VERSION ""

NS_ :

BS_:

BU_: APIM_CISM FCIMB RACM_RCIM DSP WCM DACMC HUD_ADV TRM_ITRM ACM GWM _delete APIM IPC GENERIC TSTR

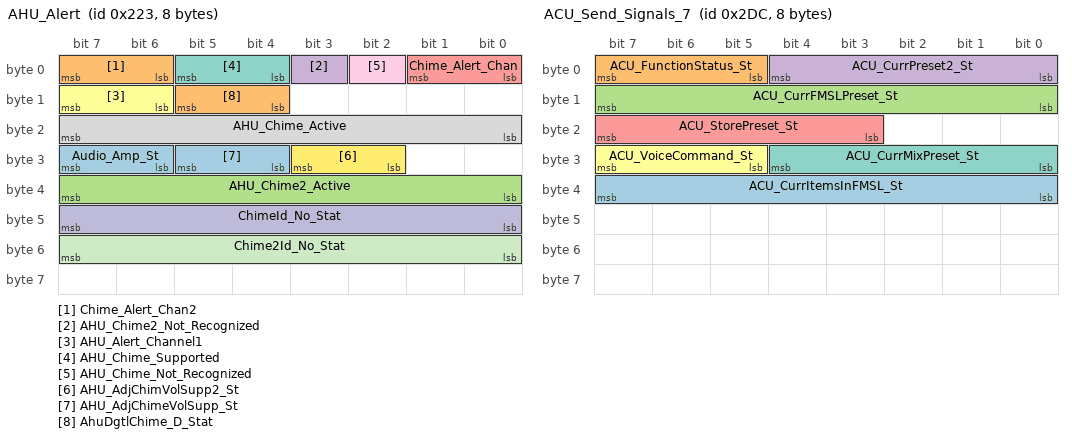
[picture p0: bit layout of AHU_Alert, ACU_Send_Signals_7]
BO_ 547 AHU_Alert: 8 ACM
 SG_ Audio_Amp_St : 31|2@0+ (1,0) [0|3] "SED"  GENERIC
 SG_ Chime_Alert_Chan2 : 7|2@0+ (1,0) [0|3] "SED"  DSP,IPC
 SG_ AHU_Chime2_Active : 39|8@0+ (1,0) [0|255] "SED"  DSP,IPC
 SG_ AHU_Chime2_Not_Recognized : 3|1@0+ (1,0) [0|1] "SED"  IPC
 SG_ Chime_Alert_Chan : 1|2@0+ (1,0) [0|3] "SED"  DSP,IPC
 SG_ AHU_Alert_Channel1 : 15|2@0+ (1,0) [0|3] "SED"  RACM_RCIM,IPC,APIM
 SG_ AHU_Chime_Supported : 5|2@0+ (1,0) [0|3] "SED"  APIM,IPC
 SG_ AHU_Chime_Active : 23|8@0+ (1,0) [0|255] "SED"  DSP,IPC
 SG_ AHU_Chime_Not_Recognized : 2|1@0+ (1,0) [0|1] "SED"  IPC
 SG_ ChimeId_No_Stat : 47|8@0+ (1,0) [0|255] "SED"  IPC
 SG_ Chime2Id_No_Stat : 55|8@0+ (1,0) [0|255] "SED"  IPC
 SG_ AHU_AdjChimVolSupp2_St : 27|2@0+ (1,0) [0|4] "SED"  IPC
 SG_ AHU_AdjChimeVolSupp_St : 29|2@0+ (1,0) [0|4] "SED"  IPC
 SG_ AhuDgtlChime_D_Stat : 13|2@0+ (1,0) [0|3] "SED"  DSP

BO_ 732 ACU_Send_Signals_7: 8 ACM
 SG_ ACU_CurrItemsInFMSL_St : 39|8@0+ (1,0) [0|255] "unitless"  APIM
 SG_ ACU_FunctionStatus_St : 7|3@0+ (1,0) [0|7] "SED"  RACM_RCIM,APIM,IPC
 SG_ ACU_CurrFMSLPreset_St : 15|8@0+ (1,0) [0|255] "unitless"  APIM
 SG_ ACU_CurrPreset2_St : 4|5@0+ (1,0) [0|31] "unitless"  HUD_ADV,RACM_RCIM,APIM,IPC
 SG_ ACU_StorePreset_St : 23|5@0+ (1,0) [0|31] "SED"  APIM,IPC
 SG_ ACU_VoiceCommand_St : 31|3@0+ (1,0) [0|7] "SED" Vector__XXX
 SG_ ACU_CurrMixPreset_St : 28|5@0+ (1,0) [0|31] "unitless"  IPC,RACM_RCIM,APIM

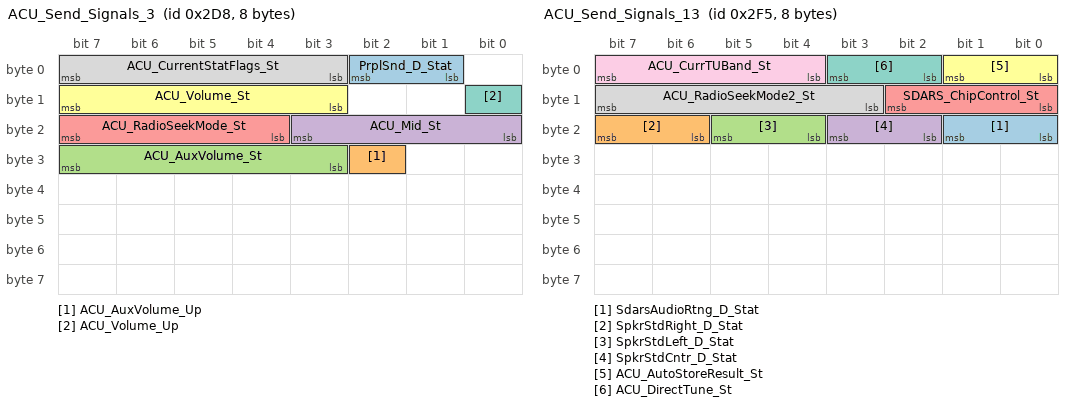
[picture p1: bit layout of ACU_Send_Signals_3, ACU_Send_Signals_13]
BO_ 728 ACU_Send_Signals_3: 8 ACM
 SG_ PrplSnd_D_Stat : 2|2@0+ (1,0) [0|3] "SED"  APIM_CISM,APIM
 SG_ ACU_AuxVolume_Up : 26|1@0+ (1,0) [0|1] "SED"  IPC
 SG_ ACU_AuxVolume_St : 31|5@0+ (1,0) [0|31] "unitless"  IPC
 SG_ ACU_Mid_St : 19|4@0+ (1,-7) [-7|8] "unitless"  APIM
 SG_ ACU_RadioSeekMode_St : 23|4@0+ (1,0) [0|15] "SED"  APIM,IPC
 SG_ ACU_Volume_St : 15|5@0+ (1,0) [0|30] "unitless"  HUD_ADV,GWM,RACM_RCIM,WCM,APIM,IPC
 SG_ ACU_Volume_Up : 8|1@0+ (1,0) [0|1] "SED"  HUD_ADV,RACM_RCIM,APIM,IPC
 SG_ ACU_CurrentStatFlags_St : 7|5@0+ (1,0) [0|31] "unitless"  RACM_RCIM,APIM,IPC

BO_ 489 ACU_Send_Signals_1: 8 ACM
 SG_ ACU_CurrentPSName_St : 7|64@0+ (1,0) [0|1.8446744074E+019] "unitless"  HUD_ADV,RACM_RCIM,APIM,IPC

BO_ 757 ACU_Send_Signals_13: 8 ACM
 SG_ SdarsAudioRtng_D_Stat : 17|2@0+ (1,0) [0|3] "SED"  APIM_CISM,APIM,GWM
 SG_ SpkrStdRight_D_Stat : 23|2@0+ (1,0) [0|3] "SED"  DSP,GWM
 SG_ SpkrStdLeft_D_Stat : 21|2@0+ (1,0) [0|3] "SED"  DSP,GWM
 SG_ SpkrStdCntr_D_Stat : 19|2@0+ (1,0) [0|3] "SED"  DSP,GWM
 SG_ SDARS_ChipControl_St : 10|3@0+ (1,0) [0|7] "SED"  APIM_CISM,GWM,APIM
 SG_ ACU_AutoStoreResult_St : 1|2@0+ (1,0) [0|3] "SED"  RACM_RCIM,GWM,APIM,IPC
 SG_ ACU_DirectTune_St : 3|2@0+ (1,0) [0|3] "SED"  GWM,APIM,IPC
 SG_ ACU_RadioSeekMode2_St : 15|5@0+ (1,0) [0|31] "SED"  HUD_ADV,RACM_RCIM,GWM,APIM,WCM,IPC
 SG_ ACU_CurrTUBand_St : 7|4@0+ (1,0) [0|15] "SED"  HUD_ADV,DSP,RACM_RCIM,GWM,APIM,WCM,IPC

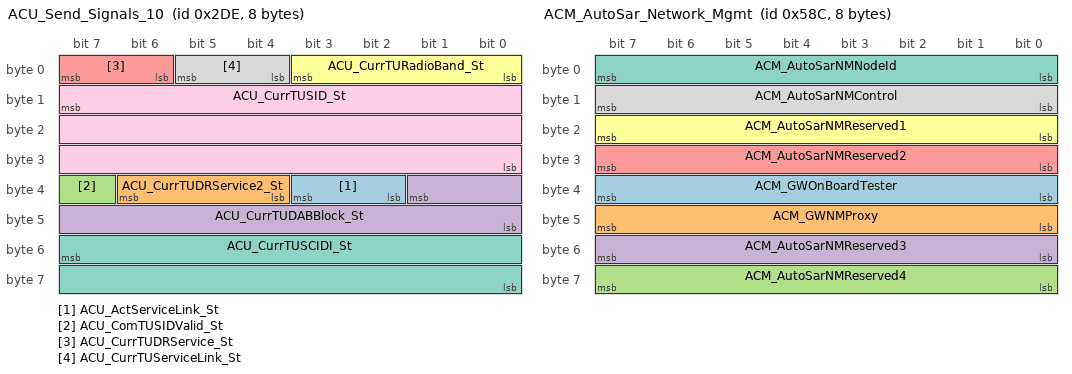
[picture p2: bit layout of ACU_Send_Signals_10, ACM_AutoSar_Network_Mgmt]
BO_ 734 ACU_Send_Signals_10: 8 ACM
 SG_ ACU_ActServiceLink_St : 35|2@0+ (1,0) [0|3] "SED"  IPC,RACM_RCIM,APIM
 SG_ ACU_CurrTUDRService2_St : 38|3@0+ (1,0) [0|7] "SED"  HUD_ADV,RACM_RCIM,APIM,IPC
 SG_ ACU_ComTUSIDValid_St : 39|1@0+ (1,0) [0|1] "SED"  APIM
 SG_ ACU_CurrTUDABBlock_St : 33|10@0+ (1,0) [0|1023] "SED"  HUD_ADV,RACM_RCIM,APIM,IPC
 SG_ ACU_CurrTUDRService_St : 7|2@0+ (1,0) [0|3] "SED"  APIM
 SG_ ACU_CurrTURadioBand_St : 3|4@0+ (1,0) [0|15] "SED" Vector__XXX
 SG_ ACU_CurrTUSCIDI_St : 55|16@0+ (1,0) [0|65535] "unitless"  RACM_RCIM,APIM
 SG_ ACU_CurrTUServiceLink_St : 5|2@0+ (1,0) [0|3] "SED"  RACM_RCIM,APIM
 SG_ ACU_CurrTUSID_St : 15|24@0+ (1,0) [0|16777215] "unitless"  RACM_RCIM,APIM

BO_ 1420 ACM_AutoSar_Network_Mgmt: 8 ACM
 SG_ ACM_GWOnBoardTester : 39|8@0+ (1,0) [0|255] "unitless"  HUD_ADV,GWM
 SG_ ACM_GWNMProxy : 47|8@0+ (1,0) [0|255] "unitless"  HUD_ADV,GWM
 SG_ ACM_AutoSarNMReserved4 : 63|8@0+ (1,0) [0|255] "unitless"  HUD_ADV,GWM
 SG_ ACM_AutoSarNMReserved3 : 55|8@0+ (1,0) [0|255] "unitless"  HUD_ADV,GWM
 SG_ ACM_AutoSarNMReserved2 : 31|8@0+ (1,0) [0|255] "unitless"  HUD_ADV,GWM
 SG_ ACM_AutoSarNMReserved1 : 23|8@0+ (1,0) [0|255] "unitless"  HUD_ADV,GWM
 SG_ ACM_AutoSarNMNodeId : 7|8@0+ (1,0) [0|255] "unitless"  HUD_ADV,GWM
 SG_ ACM_AutoSarNMControl : 15|8@0+ (1,0) [0|255] "unitless"  HUD_ADV,GWM

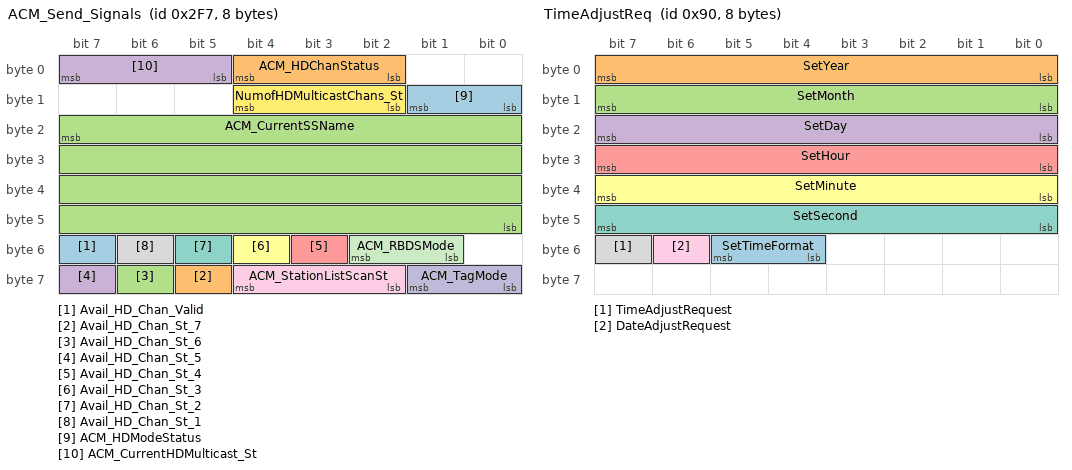
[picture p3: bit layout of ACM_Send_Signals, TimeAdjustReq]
BO_ 759 ACM_Send_Signals: 8 ACM
 SG_ Avail_HD_Chan_Valid : 55|1@0+ (1,0) [0|1] "SED"  APIM,RACM_RCIM
 SG_ Avail_HD_Chan_St_7 : 61|1@0+ (1,0) [0|1] "SED"  APIM,RACM_RCIM
 SG_ Avail_HD_Chan_St_6 : 62|1@0+ (1,0) [0|1] "SED"  APIM,RACM_RCIM
 SG_ Avail_HD_Chan_St_5 : 63|1@0+ (1,0) [0|1] "SED"  APIM,RACM_RCIM
 SG_ Avail_HD_Chan_St_4 : 51|1@0+ (1,0) [0|1] "SED"  APIM,RACM_RCIM
 SG_ Avail_HD_Chan_St_3 : 52|1@0+ (1,0) [0|1] "SED"  APIM,RACM_RCIM
 SG_ Avail_HD_Chan_St_2 : 53|1@0+ (1,0) [0|1] "SED"  APIM,RACM_RCIM
 SG_ Avail_HD_Chan_St_1 : 54|1@0+ (1,0) [0|1] "SED"  APIM,RACM_RCIM
 SG_ ACM_StationListScanSt : 60|3@0+ (1,0) [0|7] "SED"  APIM_CISM,APIM,IPC
 SG_ ACM_TagMode : 57|2@0+ (1,0) [0|3] "SED"  APIM_CISM,APIM,IPC
 SG_ ACM_RBDSMode : 50|2@0+ (1,0) [0|3] "SED"  APIM_CISM,RACM_RCIM,APIM,IPC
 SG_ NumofHDMulticastChans_St : 12|3@0+ (1,0) [0|7] "SED"  APIM_CISM,RACM_RCIM,APIM,IPC
 SG_ ACM_HDModeStatus : 9|2@0+ (1,0) [0|3] "SED"  APIM_CISM,HUD_ADV,RACM_RCIM,APIM,IPC
 SG_ ACM_HDChanStatus : 4|3@0+ (1,0) [0|7] "SED"  APIM_CISM,HUD_ADV,RACM_RCIM,APIM,IPC,DSP
 SG_ ACM_CurrentSSName : 23|32@0+ (1,0) [0|4294967295] "unitless"  APIM_CISM,HUD_ADV,RACM_RCIM,APIM,IPC
 SG_ ACM_CurrentHDMulticast_St : 7|3@0+ (1,0) [0|7] "SED"  APIM_CISM,HUD_ADV,RACM_RCIM,APIM,IPC

BO_ 144 TimeAdjustReq: 8 APIM
 SG_ SetTimeFormat : 53|2@0+ (1,0) [0|3] "SED"  IPC
 SG_ SetYear : 7|8@0+ (1,2000) [2000|2254] "year"  IPC
 SG_ SetMonth : 15|8@0+ (1,0) [0|12] "month"  IPC
 SG_ SetDay : 23|8@0+ (1,0) [0|31] "day"  IPC
 SG_ SetHour : 31|8@0+ (1,0) [0|23] "hour"  IPC
 SG_ SetMinute : 39|8@0+ (1,0) [0|59] "minute"  IPC
 SG_ SetSecond : 47|8@0+ (1,0) [0|59] "second"  IPC
 SG_ TimeAdjustRequest : 55|1@0+ (1,0) [0|1] "SED"  IPC
 SG_ DateAdjustRequest : 54|1@0+ (1,0) [0|1] "SED"  IPC

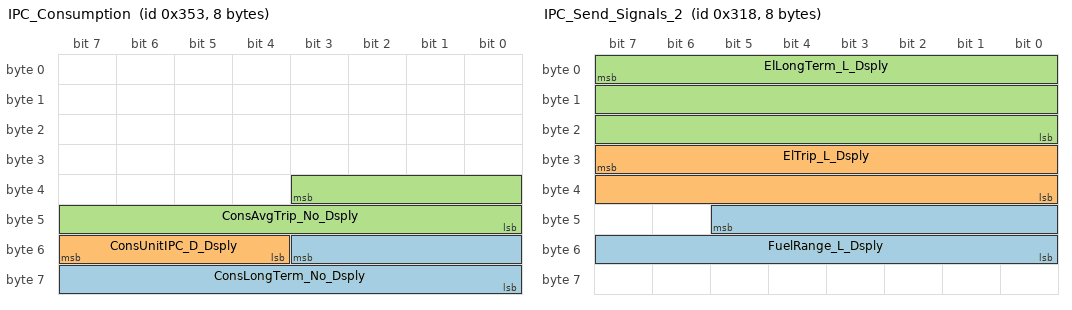
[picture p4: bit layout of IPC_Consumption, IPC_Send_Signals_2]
BO_ 851 IPC_Consumption: 8 IPC
 SG_ ConsLongTerm_No_Dsply : 51|12@0+ (1,0) [0|4093] "%"  GWM
 SG_ ConsUnitIPC_D_Dsply : 55|4@0+ (1,0) [0|15] "SED"  APIM_CISM,GWM,APIM
 SG_ ConsAvgTrip_No_Dsply : 35|12@0+ (1,0) [0|4093] "%"  GWM

BO_ 792 IPC_Send_Signals_2: 8 IPC
 SG_ FuelRange_L_Dsply : 45|14@0+ (0.1,0) [0|1638.3] "km"  APIM_CISM,HUD_ADV,GWM,ACM,APIM
 SG_ ElTrip_L_Dsply : 31|16@0+ (0.1,0) [0|6553.3] "unitless"  GWM
 SG_ ElLongTerm_L_Dsply : 7|24@0+ (0.1,0) [0|1677721.3] "unitless"  GWM

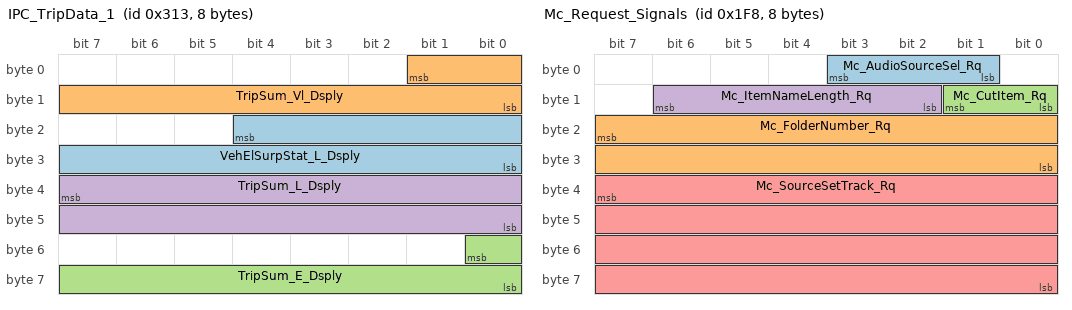
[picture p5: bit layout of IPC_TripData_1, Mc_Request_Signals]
BO_ 787 IPC_TripData_1: 8 IPC
 SG_ VehElSurpStat_L_Dsply : 20|13@0+ (0.1,-409.4) [-409.4|409.5] "Km"  GENERIC,GWM
 SG_ TripSum_Vl_Dsply : 1|10@0+ (0.1,0) [0|102.3] "Liters"  GWM
 SG_ TripSum_E_Dsply : 48|9@0+ (0.1,0) [0|50.9] "kw*hrs"  GWM
 SG_ TripSum_L_Dsply : 39|16@0+ (0.1,0) [0|6553.3] "Km"  GWM

BO_ 697 AUDIO_MC_WORD_Rx: 8 IPC
 SG_ AUDIO_MC_WORD_Rx : 7|64@0+ (1,0) [0|1.84467440737096E+019] "unitless"  APIM_CISM,ACM

BO_ 700 AUDIO_RDISP_WORD_Rx: 8 APIM
 SG_ AUDIO_RDISP_WORD_Rx : 7|64@0+ (1,0) [0|1.84467440737096E+019] "unitless"  APIM_CISM,ACM

BO_ 676 MC_RDISP_WORD_Tx: 8 IPC
 SG_ MC_RDISP_WORD_Tx : 7|64@0+ (1,0) [0|1.84467440737096E+019] "unitless"  APIM_CISM,APIM

BO_ 504 Mc_Request_Signals: 8 IPC
 SG_ Mc_AudioSourceSel_Rq : 3|3@0+ (1,0) [0|7] "SED"  APIM_CISM,ACM
 SG_ Mc_FolderNumber_Rq : 23|16@0+ (1,0) [0|65535] "unitless"  APIM_CISM,ACM
 SG_ Mc_CutItem_Rq : 9|2@0+ (1,0) [0|3] "SED"  APIM_CISM,ACM
 SG_ Mc_ItemNameLength_Rq : 14|5@0+ (1,0) [0|20] "SED"  APIM_CISM,ACM
 SG_ Mc_SourceSetTrack_Rq : 39|32@0+ (1,0) [0|4294967295] "unitless"  APIM_CISM,ACM

BO_ 410 Mc_Send_Signals_3: 8 IPC
 SG_ MyKey_e911Override_St : 39|2@0+ (1,0) [0|3] "SED"  APIM_CISM,APIM
 SG_ DoNotDisturbOveride_St : 26|2@0+ (1,0) [0|3] "SED"  APIM_CISM,APIM

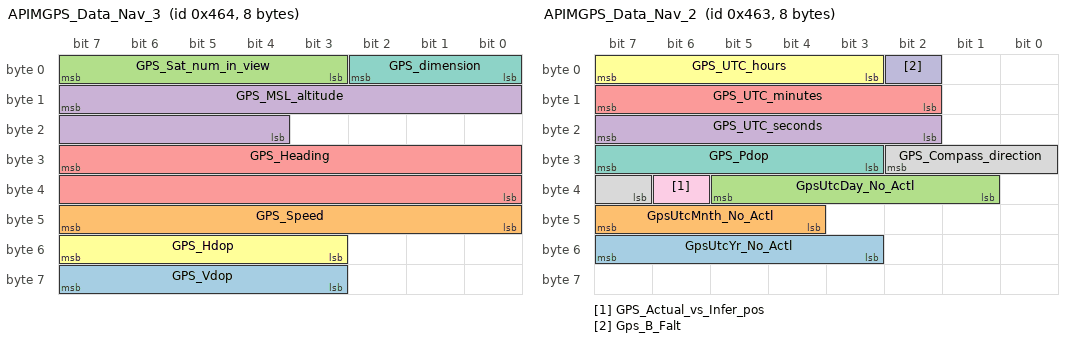
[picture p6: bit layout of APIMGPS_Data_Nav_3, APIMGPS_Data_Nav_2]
BO_ 1124 APIMGPS_Data_Nav_3: 8 APIM
 SG_ GPS_Vdop : 63|5@0+ (0.2,0) [0|5.8] "unitless"  GWM
 SG_ GPS_Speed : 47|8@0+ (1,0) [0|253] "MPH"  GWM
 SG_ GPS_Sat_num_in_view : 7|5@0+ (1,0) [0|29] "unitless"  GWM
 SG_ GPS_MSL_altitude : 15|12@0+ (10,-20460) [-20460|20470] "feet"  GWM
 SG_ GPS_Heading : 31|16@0+ (0.01,0) [0|655.33] "Degrees"  GWM
 SG_ GPS_Hdop : 55|5@0+ (0.2,0) [0|5.8] "unitless"  GWM
 SG_ GPS_dimension : 2|3@0+ (1,0) [0|7] "SED"  GWM

BO_ 1123 APIMGPS_Data_Nav_2: 8 APIM
 SG_ GpsUtcYr_No_Actl : 55|5@0+ (1,2010) [2010|2040] "Year"  GWM
 SG_ GpsUtcMnth_No_Actl : 47|4@0+ (1,1) [1|15] "Month"  GWM
 SG_ GpsUtcDay_No_Actl : 37|5@0+ (1,1) [1|32] "Day"  GWM
 SG_ GPS_UTC_seconds : 23|6@0+ (1,0) [0|59] "seconds"  GWM
 SG_ GPS_UTC_minutes : 15|6@0+ (1,0) [0|59] "Minutes"  GWM
 SG_ GPS_UTC_hours : 7|5@0+ (1,0) [0|23] "Hours"  GWM
 SG_ GPS_Pdop : 31|5@0+ (0.2,0) [0|5.8] "unitless"  GWM
 SG_ GPS_Compass_direction : 26|4@0+ (1,0) [0|15] "SED"  HUD_ADV,GWM,IPC
 SG_ GPS_Actual_vs_Infer_pos : 38|1@0+ (1,0) [0|1] "SED"  GWM
 SG_ Gps_B_Falt : 2|1@0+ (1,0) [0|1] "SED"  GWM

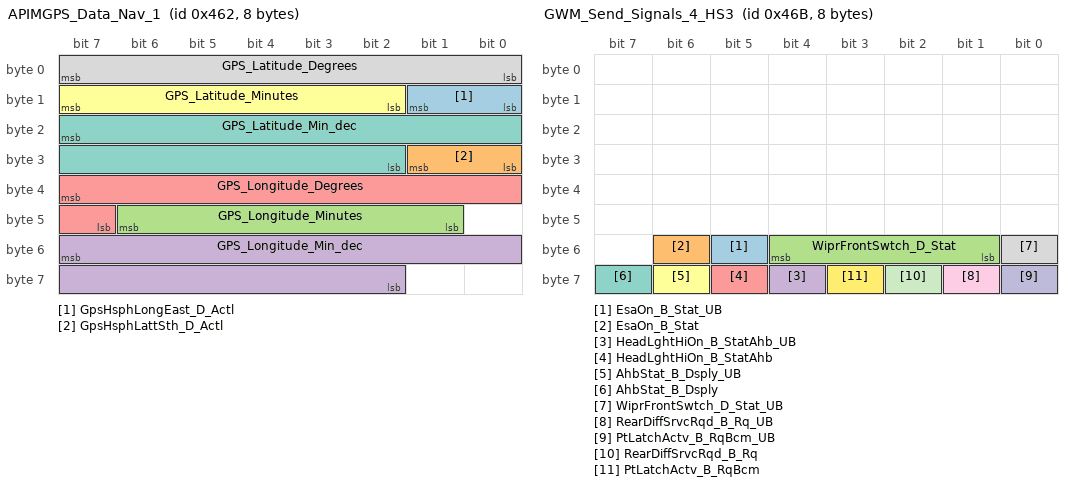
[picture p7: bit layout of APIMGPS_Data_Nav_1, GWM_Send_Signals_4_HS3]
BO_ 1122 APIMGPS_Data_Nav_1: 8 APIM
 SG_ GpsHsphLongEast_D_Actl : 9|2@0+ (1,0) [0|3] "SED"  GWM
 SG_ GpsHsphLattSth_D_Actl : 25|2@0+ (1,0) [0|3] "SED"  GWM
 SG_ GPS_Longitude_Minutes : 46|6@0+ (1,0) [0|61] "Minutes"  GWM
 SG_ GPS_Longitude_Min_dec : 55|14@0+ (0.0001,0) [0|1.6381] "Minutes"  GWM
 SG_ GPS_Longitude_Degrees : 39|9@0+ (1,-179) [-179|330] "Degrees"  GWM
 SG_ GPS_Latitude_Minutes : 15|6@0+ (1,0) [0|61] "Minutes"  GWM
 SG_ GPS_Latitude_Min_dec : 23|14@0+ (0.0001,0) [0|1.6381] "Minutes"  GWM
 SG_ GPS_Latitude_Degrees : 7|8@0+ (1,-89) [-89|164] "Degrees"  GWM

BO_ 1131 GWM_Send_Signals_4_HS3: 8 GWM
 SG_ EsaOn_B_Stat_UB : 53|1@0+ (1,0) [0|1] "SED"  IPC
 SG_ EsaOn_B_Stat : 54|1@0+ (1,0) [0|1] "SED"  IPC
 SG_ WiprFrontSwtch_D_Stat : 52|4@0+ (1,0) [0|15] "SED"  HUD_ADV,GENERIC
 SG_ HeadLghtHiOn_B_StatAhb_UB : 60|1@0+ (1,0) [0|1] "SED"  IPC
 SG_ HeadLghtHiOn_B_StatAhb : 61|1@0+ (1,0) [0|1] "SED"  IPC
 SG_ AhbStat_B_Dsply_UB : 62|1@0+ (1,0) [0|1] "SED"  IPC
 SG_ AhbStat_B_Dsply : 63|1@0+ (1,0) [0|1] "SED"  IPC
 SG_ WiprFrontSwtch_D_Stat_UB : 48|1@0+ (1,0) [0|1] "SED"  HUD_ADV,GENERIC
 SG_ RearDiffSrvcRqd_B_Rq_UB : 57|1@0+ (1,0) [0|1] "SED"  IPC
 SG_ PtLatchActv_B_RqBcm_UB : 56|1@0+ (1,0) [0|1] "SED"  IPC
 SG_ RearDiffSrvcRqd_B_Rq : 58|1@0+ (1,0) [0|1] "SED"  IPC
 SG_ PtLatchActv_B_RqBcm : 59|1@0+ (1,0) [0|1] "SED"  IPC

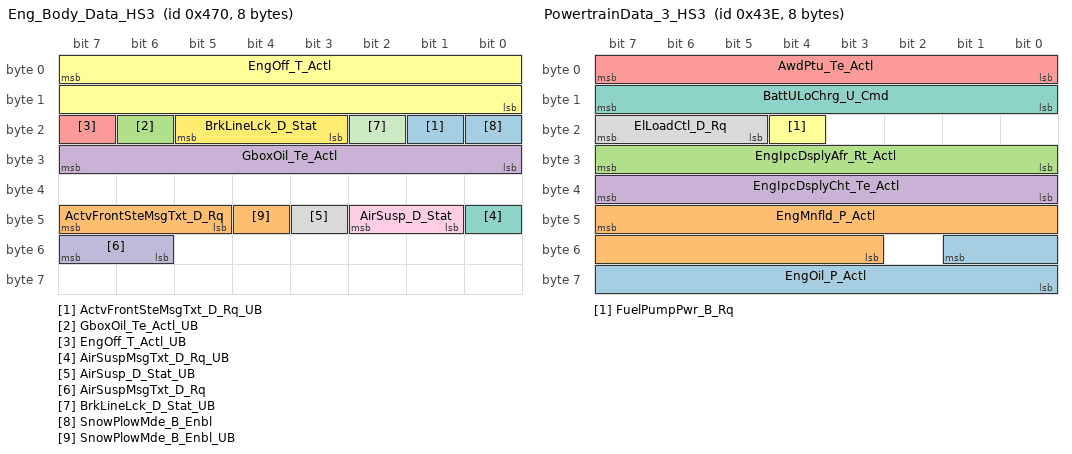
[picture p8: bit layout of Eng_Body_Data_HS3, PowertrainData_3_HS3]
BO_ 1136 Eng_Body_Data_HS3: 8 GWM
 SG_ ActvFrontSteMsgTxt_D_Rq_UB : 17|1@0+ (1,0) [0|1] "SED"  IPC
 SG_ ActvFrontSteMsgTxt_D_Rq : 47|3@0+ (1,0) [0|7] "SED"  IPC
 SG_ GboxOil_Te_Actl_UB : 22|1@0+ (1,0) [0|1] "SED"  APIM_CISM,APIM,IPC
 SG_ GboxOil_Te_Actl : 31|8@0+ (1,-60) [-60|193] "degC"  APIM_CISM,APIM,IPC
 SG_ EngOff_T_Actl_UB : 23|1@0+ (1,0) [0|1] "SED"  IPC
 SG_ EngOff_T_Actl : 7|16@0+ (1,0) [0|65534] "second^0.5"  IPC
 SG_ AirSuspMsgTxt_D_Rq_UB : 40|1@0+ (1,0) [0|1] "SED"  IPC
 SG_ AirSusp_D_Stat_UB : 43|1@0+ (1,0) [0|1] "SED"  IPC
 SG_ AirSusp_D_Stat : 42|2@0+ (1,0) [0|3] "SED"  IPC
 SG_ AirSuspMsgTxt_D_Rq : 55|2@0+ (1,0) [0|3] "SED"  IPC
 SG_ BrkLineLck_D_Stat_UB : 18|1@0+ (1,0) [0|1] "SED"  IPC
 SG_ BrkLineLck_D_Stat : 21|3@0+ (1,0) [0|7] "SED"  IPC
 SG_ SnowPlowMde_B_Enbl : 16|1@0+ (1,0) [0|1] "SED"  APIM_CISM,IPC,APIM
 SG_ SnowPlowMde_B_Enbl_UB : 44|1@0+ (1,0) [0|1] "SED"  APIM_CISM,IPC,APIM

BO_ 1106 TrailerAid_Stat1_HS3: 8 GWM
 SG_ TrlrSnsId_No_Actl : 7|48@0+ (1,0) [0|281474976710653] "unitless"  APIM,APIM_CISM,IPC

BO_ 1086 PowertrainData_3_HS3: 8 GWM
 SG_ EngOil_P_Actl : 49|10@0+ (1,0) [0|1023] "kilopascal"  APIM_CISM,APIM,IPC
 SG_ EngMnfld_P_Actl : 47|13@0+ (0.1,-206.8) [-206.8|612.3] "kilopascal"  APIM_CISM,APIM,IPC
 SG_ EngIpcDsplyAfr_Rt_Actl : 31|8@0+ (0.1,0) [0|25.5] "unitless"  IPC
 SG_ EngIpcDsplyCht_Te_Actl : 39|8@0+ (1,-60) [-60|195] "degC"  IPC
 SG_ AwdPtu_Te_Actl : 7|8@0+ (1,-50) [-50|204] "degC" Vector__XXX
 SG_ FuelPumpPwr_B_Rq : 20|1@0+ (1,0) [0|1] "SED"  IPC
 SG_ BattULoChrg_U_Cmd : 15|8@0+ (0.025,10.6) [10.6|16.975] "volt"  IPC
 SG_ ElLoadCtl_D_Rq : 23|3@0+ (1,0) [0|7] "SED"  IPC

BO_ 817 Locking_Systems_2_HS3: 8 GWM
 SG_ ChildLckMde_B_Stat : 56|1@0+ (1,0) [0|1] "SED"  GENERIC
 SG_ VehLckInd_D_Rq : 58|2@0+ (1,0) [0|3] "SED"  GENERIC
 SG_ DrTgateOpen_B_Rq : 59|1@0+ (1,0) [0|1] "SED"  GENERIC
 SG_ DrTgateExtSwMde_B_Stat : 32|1@0+ (1,0) [0|1] "SED"  GENERIC
 SG_ Remote_Device_Feedback : 50|3@0+ (1,0) [0|7] "SED"  GENERIC
 SG_ Veh_Lock_Requestor : 55|5@0+ (1,0) [0|31] "SED"  APIM_CISM,APIM,HUD_ADV
 SG_ R_Pwr_Sliding_Dr_Rqst : 36|1@0+ (1,0) [0|1] "SED"  GENERIC
 SG_ Power_Liftgate_Rqst : 0|1@0+ (1,0) [0|1] "SED"  GENERIC
 SG_ Veh_Lock_EvNum : 47|8@0+ (1,0) [0|255] "unitless"  HUD_ADV,IPC
 SG_ Power_Decklid_Rqst : 1|1@0+ (1,0) [0|1] "SED"  GENERIC
 SG_ L_Pwr_Sliding_Dr_Rqst : 3|1@0+ (1,0) [0|1] "SED"  GENERIC
 SG_ Keyfob_Pad_Msg_Count : 15|8@0+ (1,0) [0|255] "Counts"  GENERIC
 SG_ Veh_Lock_Sub_Id : 63|4@0+ (1,0) [0|15] "SED"  GENERIC
 SG_ Veh_Lock_Status : 34|2@0+ (1,0) [0|3] "SED"  APIM_CISM,HUD_ADV,APIM,RACM_RCIM,ACM,IPC
 SG_ ChildLck_D_Dsply : 7|2@0+ (1,0) [0|3] "SED"  GENERIC
 SG_ WindowLockout_B_Stat : 35|1@0+ (1,0) [0|1] "SED"  RACM_RCIM,GENERIC
 SG_ RollCodeUnlock : 23|16@0+ (1,0) [0|65535] "Unitless"  IPC
 SG_ Lockmsgtxt_D_Rq : 39|3@0+ (1,0) [0|7] "SED"  IPC
 SG_ FobComm_D_Stat : 5|2@0+ (1,0) [0|3] "SED"  GENERIC
 SG_ LockInhibit : 2|1@0+ (1,0) [0|1] "SED"  APIM_CISM,APIM

BO_ 611 Driveline_Data_1_HS3: 8 GWM
 SG_ AwdTerrMdeChng_D_Rdy : 58|3@0+ (1,0) [0|7] "SED"  IPC
 SG_ AwdTerrMde_D_Actl : 50|3@0+ (1,0) [0|7] "SED"  IPC
 SG_ AwdSys_D_Stat : 27|2@0+ (1,0) [0|3] "SED"  IPC
 SG_ AwdStat_D_RqDsply : 63|5@0+ (1,0) [0|31] "SED"  IPC
 SG_ AwdLck_D_Stat : 31|4@0+ (1,0) [0|15] "SED"  IPC
 SG_ AwdSrvcRqd_B_Rq : 0|1@0+ (1,0) [0|1] "SED"  IPC
 SG_ AwdLck_Tq_Rq : 15|12@0+ (1,0) [0|4093] "Nm"  IPC
 SG_ TrnAout_Tq_RqMx : 47|13@0+ (1,-1250) [-1250|6941] "Nm"  IPC
 SG_ AwdOffRoadMode_D_Stats : 25|2@0+ (1,0) [0|3] "SED"  APIM_CISM,APIM,IPC
 SG_ AwdLoLamp_D_RqDsply : 35|2@0+ (1,0) [0|3] "SED"  IPC
 SG_ AwdHiLamp_D_RqDsply : 19|2@0+ (1,0) [0|3] "SED"  IPC
 SG_ AwdAutoLamp_D_RqDsply : 17|2@0+ (1,0) [0|3] "SED"  IPC
 SG_ Awd2wdLamp_D_RqDsply : 2|2@0+ (1,0) [0|3] "SED"  IPC
 SG_ AwdRnge_D_Actl : 7|3@0+ (1,0) [0|7] "SED"  APIM_CISM,ACM,APIM,IPC
 SG_ NtrlTowAvail_B_Stat : 4|1@0+ (1,0) [0|1] "SED"  IPC
 SG_ AwdDrvMde_D_Stat : 38|3@0+ (1,0) [0|7] "SED"  IPC
 SG_ SelDrvMdeAwd_D_Stat : 33|2@0+ (1,0) [0|3] "SED"  GENERIC

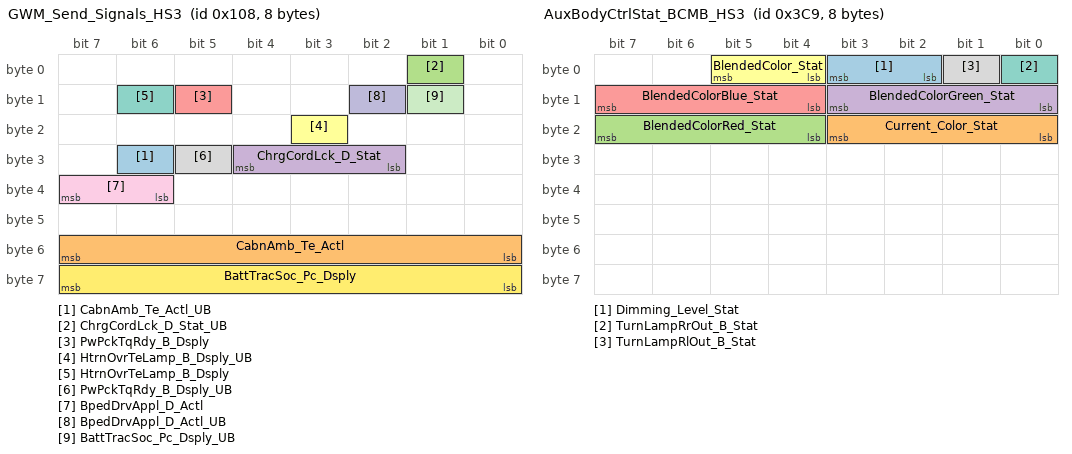
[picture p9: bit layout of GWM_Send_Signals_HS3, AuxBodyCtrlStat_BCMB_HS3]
BO_ 264 GWM_Send_Signals_HS3: 8 GWM
 SG_ CabnAmb_Te_Actl_UB : 30|1@0+ (1,0) [0|1] "SED"  APIM_CISM,WCM,ACM
 SG_ CabnAmb_Te_Actl : 55|8@0+ (0.5,-57) [-57|70] "degreesC"  APIM_CISM,WCM,ACM
 SG_ ChrgCordLck_D_Stat_UB : 1|1@0+ (1,0) [0|1] "SED"  APIM_CISM,APIM
 SG_ ChrgCordLck_D_Stat : 28|3@0+ (1,0) [0|7] "SED"  APIM_CISM,APIM
 SG_ PwPckTqRdy_B_Dsply : 13|1@0+ (1,0) [0|1] "SED"  APIM_CISM,APIM,IPC
 SG_ HtrnOvrTeLamp_B_Dsply_UB : 19|1@0+ (1,0) [0|1] "SED"  IPC
 SG_ HtrnOvrTeLamp_B_Dsply : 14|1@0+ (1,0) [0|1] "SED"  IPC
 SG_ PwPckTqRdy_B_Dsply_UB : 29|1@0+ (1,0) [0|1] "SED"  APIM_CISM,APIM,IPC
 SG_ BpedDrvAppl_D_Actl : 39|2@0+ (1,0) [0|3] "SED"  APIM_CISM,APIM,TRM_ITRM,IPC
 SG_ BpedDrvAppl_D_Actl_UB : 10|1@0+ (1,0) [0|1] "SED"  APIM_CISM,APIM,TRM_ITRM,IPC
 SG_ BattTracSoc_Pc_Dsply_UB : 9|1@0+ (1,0) [0|1] "SED"  APIM_CISM,HUD_ADV,APIM,IPC
 SG_ BattTracSoc_Pc_Dsply : 63|8@0+ (0.5,0) [0|126.5] "Percent"  APIM_CISM,HUD_ADV,APIM,IPC

BO_ 1114 TrailerAid_Data: 8 IPC
 SG_ TrailCtlSwtch_B_Stat2 : 16|1@0+ (1,0) [0|1] "SED"  GWM
 SG_ TrlBrkInitOut_D_Rq : 60|2@0+ (1,0) [0|3] "SED"  TRM_ITRM,GWM

BO_ 968 Cluster_Lighting_Rq: 8 IPC
 SG_ RvltnMatchAllw_D_Rq : 58|2@0+ (1,0) [0|3] "SED"  GWM
 SG_ BrkDrvMde_D_Rq : 18|3@0+ (1,0) [0|7] "SED"  GWM
 SG_ LnchCtl_N_Rq : 55|8@0+ (50,0) [0|12750] "rpm"  GWM
 SG_ LnchCtl_D_Rq : 63|2@0+ (1,0) [0|3] "SED"  GWM
 SG_ CurrentColor_CmdGage : 43|4@0+ (1,0) [0|15] "SED"  GWM
 SG_ BlendedColor_CmdGage : 25|2@0+ (1,0) [0|3] "SED"  GWM
 SG_ BlendColorRed_CmdGage : 47|4@0+ (1,0) [0|15] "SED"  GWM
 SG_ BlendColorGrn_CmdGage : 35|4@0+ (1,0) [0|15] "SED"  GWM
 SG_ BlendColorBlue_CmdGage : 39|4@0+ (1,0) [0|15] "SED"  GWM
 SG_ Dimming_Level_Cmd : 1|2@0+ (1,0) [0|3] "SED"  GWM
 SG_ Current_Color_Cmd : 23|4@0+ (1,0) [0|15] "SED"  GWM
 SG_ BlendedColorRed_Cmd : 11|4@0+ (1,0) [0|15] "SED"  GWM
 SG_ BlendedColorGreen_Cmd : 15|4@0+ (1,0) [0|15] "SED"  GWM
 SG_ BlendedColorBlue_Cmd : 5|4@0+ (1,0) [0|15] "SED"  GWM
 SG_ BlendedColor_Cmd : 7|2@0+ (1,0) [0|3] "SED"  GWM
 SG_ SuspDrvMde_D_Rq : 61|3@0+ (1,0) [0|7] "SED"  GWM
 SG_ SlMde_D_Rq : 27|2@0+ (1,0) [0|3] "SED"  GWM
 SG_ IsaOffst_D_Rq : 31|4@0+ (1,0) [0|15] "SED"  GWM

BO_ 969 AuxBodyCtrlStat_BCMB_HS3: 8 GWM
 SG_ Dimming_Level_Stat : 3|2@0+ (1,0) [0|3] "SED"  IPC
 SG_ Current_Color_Stat : 19|4@0+ (1,0) [0|15] "SED"  IPC
 SG_ BlendedColorRed_Stat : 23|4@0+ (1,0) [0|15] "SED"  IPC
 SG_ BlendedColorGreen_Stat : 11|4@0+ (1,0) [0|15] "SED"  IPC
 SG_ BlendedColorBlue_Stat : 15|4@0+ (1,0) [0|15] "SED"  IPC
 SG_ BlendedColor_Stat : 5|2@0+ (1,0) [0|3] "SED"  IPC
 SG_ TurnLampRrOut_B_Stat : 0|1@0+ (1,0) [0|1] "SED"  IPC
 SG_ TurnLampRlOut_B_Stat : 1|1@0+ (1,0) [0|1] "SED"  IPC

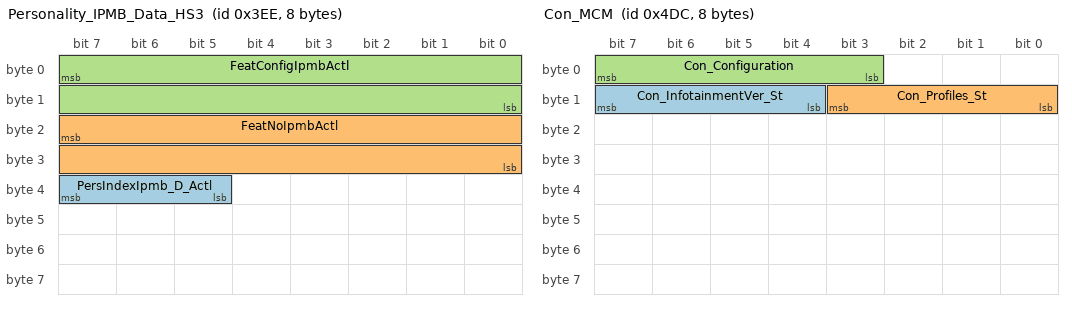
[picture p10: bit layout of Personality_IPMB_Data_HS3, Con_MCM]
BO_ 1006 Personality_IPMB_Data_HS3: 8 GWM
 SG_ PersIndexIpmb_D_Actl : 39|3@0+ (1,0) [0|7] "SED"  APIM_CISM,APIM,ACM
 SG_ FeatNoIpmbActl : 23|16@0+ (1,0) [0|65535] "Number"  APIM_CISM,APIM,ACM
 SG_ FeatConfigIpmbActl : 7|16@0+ (1,0) [0|65535] "Undefined"  APIM_CISM,APIM,ACM

BO_ 130 Steering_Wheel_Data2_HS3: 8 GWM
 SG_ EngExhMdeQuiet_B_RqDrv2 : 39|1@0+ (1,0) [0|1] "SED"  IPC
 SG_ SteWhlSwtchHome_B_Stat : 19|1@0+ (1,0) [0|1] "SED"  IPC
 SG_ SteWhlSwtchInfo_B_Stat : 18|1@0+ (1,0) [0|1] "SED"  IPC
 SG_ SelDrvMdeSwtch_D_Stat4 : 21|2@0+ (1,0) [0|3] "SED"  GENERIC
 SG_ SelDrvMdeSwtch3_D_Stat4 : 25|2@0+ (1,0) [0|3] "SED"  GENERIC
 SG_ SelDrvMdeSwtch2_D_Stat4 : 27|2@0+ (1,0) [0|3] "SED"  GENERIC
 SG_ SelDrvMdeSwtch1_D_Stat4 : 29|2@0+ (1,0) [0|3] "SED"  GENERIC
 SG_ PoliceAux4Swtch_B_Stat : 30|1@0+ (1,0) [0|1] "SED"  TRM_ITRM
 SG_ PoliceAux3Swtch_B_Stat : 31|1@0+ (1,0) [0|1] "SED"  TRM_ITRM
 SG_ PoliceAux2Swtch_B_Stat : 16|1@0+ (1,0) [0|1] "SED"  TRM_ITRM
 SG_ PoliceAux1Swtch_B_Stat : 17|1@0+ (1,0) [0|1] "SED"  TRM_ITRM
 SG_ SteWhlSwtchView_B_Stat : 23|1@0+ (1,0) [0|1] "SED"  IPC
 SG_ SteWhlSwtchSet_B_Stat : 8|1@0+ (1,0) [0|1] "SED"  IPC
 SG_ SteWhlSwtchPhon_B_Stat : 9|1@0+ (1,0) [0|1] "SED"  HUD_ADV,IPC
 SG_ SteWhlSwtchNav_B_Stat : 10|1@0+ (1,0) [0|1] "SED"  IPC
 SG_ SteWhlSwtchMed_B_Stat : 11|1@0+ (1,0) [0|1] "SED"  HUD_ADV,IPC
 SG_ SteWhlSwtchIod_B_Stat : 12|1@0+ (1,0) [0|1] "SED"  IPC
 SG_ SteWhlSwtchHud_B_Stat : 13|1@0+ (1,0) [0|1] "SED"  HUD_ADV,IPC
 SG_ SteWhlSwtchBack_B_Stat : 14|1@0+ (1,0) [0|1] "SED"  HUD_ADV,IPC
 SG_ SteWhlSwtchMenu_B_Stat : 22|1@0+ (1,0) [0|1] "SED"  IPC
 SG_ SteEffortInc_B_RqDrv : 5|1@0+ (1,0) [0|1] "SED"  IPC
 SG_ SelDrvMdeInc_B_RqDrv : 6|1@0+ (1,0) [0|1] "SED"  IPC
 SG_ SelDrvMdeDec_B_RqDrv : 7|1@0+ (1,0) [0|1] "SED"  IPC
 SG_ SuspDampInc_B_RqDrv : 15|1@0+ (1,0) [0|1] "SED"  IPC
 SG_ SteWhlSwtchUp_B_Stat : 3|1@0+ (1,0) [0|1] "SED"  HUD_ADV,IPC
 SG_ SteWhlSwtchRght_B_Stat : 2|1@0+ (1,0) [0|1] "SED"  HUD_ADV,IPC
 SG_ SteWhlSwtchOk_B_Stat : 4|1@0+ (1,0) [0|1] "SED"  HUD_ADV,IPC
 SG_ SteWhlSwtchLeft_B_Stat : 1|1@0+ (1,0) [0|1] "SED"  HUD_ADV,IPC
 SG_ SteWhlSwtchDown_B_Stat : 0|1@0+ (1,0) [0|1] "SED"  HUD_ADV,IPC

BO_ 1244 Con_MCM: 8 ACM
 SG_ Con_InfotainmentVer_St : 15|4@0+ (1,0) [0|0] ""  IPC
 SG_ Con_Profiles_St : 11|4@0+ (1,0) [0|0] ""  IPC
 SG_ Con_Configuration : 7|5@0+ (1,0) [0|0] ""  IPC

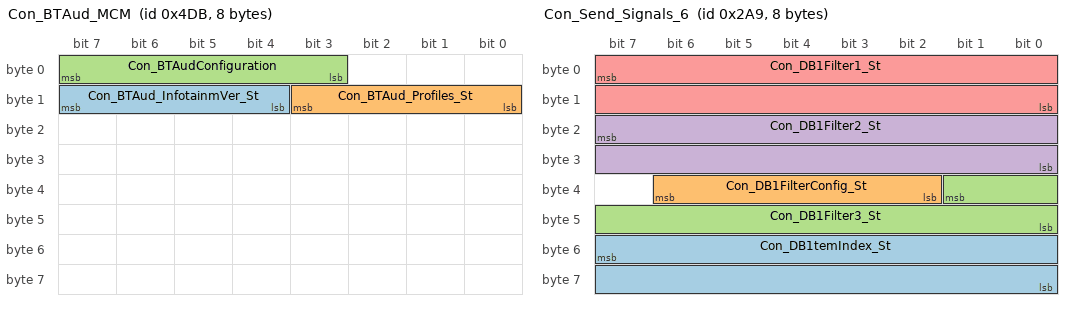
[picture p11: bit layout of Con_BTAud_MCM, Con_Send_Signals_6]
BO_ 1243 Con_BTAud_MCM: 8 ACM
 SG_ Con_BTAud_InfotainmVer_St : 15|4@0+ (1,0) [0|0] ""  IPC
 SG_ Con_BTAud_Profiles_St : 11|4@0+ (1,0) [0|0] ""  IPC
 SG_ Con_BTAudConfiguration : 7|5@0+ (1,0) [0|0] ""  IPC

BO_ 681 Con_Send_Signals_6: 8 ACM
 SG_ Con_DB1temIndex_St : 55|16@0+ (1,0) [0|0] ""  IPC
 SG_ Con_DB1FilterConfig_St : 38|5@0+ (1,0) [0|31] "SED"  IPC
 SG_ Con_DB1Filter3_St : 33|10@0+ (1,0) [0|1023] "unitless"  IPC
 SG_ Con_DB1Filter2_St : 23|16@0+ (1,0) [0|65535] "unitless"  IPC
 SG_ Con_DB1Filter1_St : 7|16@0+ (1,0) [0|65535] "unitless"  IPC

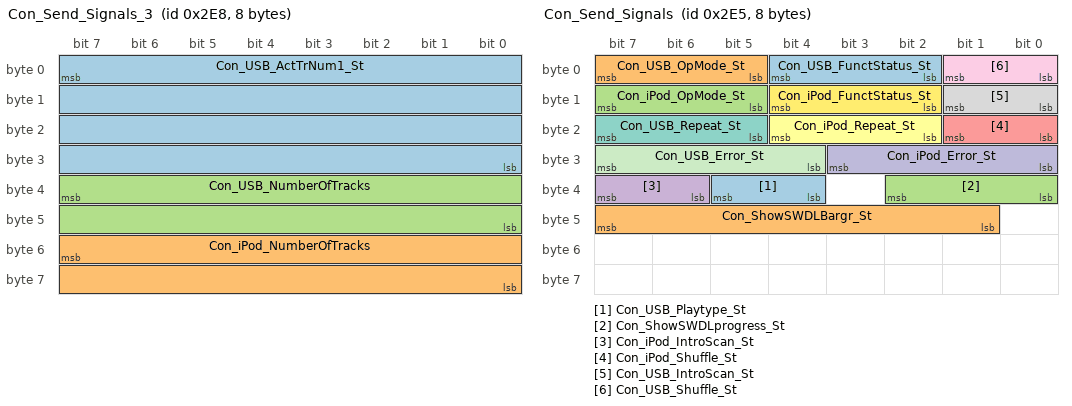
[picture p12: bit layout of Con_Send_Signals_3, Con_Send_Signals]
BO_ 744 Con_Send_Signals_3: 8 ACM
 SG_ Con_USB_ActTrNum1_St : 7|32@0+ (1,0) [0|4294967295] ""  IPC
 SG_ Con_iPod_NumberOfTracks : 55|16@0+ (1,0) [0|65535] ""  IPC
 SG_ Con_USB_NumberOfTracks : 39|16@0+ (1,0) [0|65535] ""  IPC

BO_ 741 Con_Send_Signals: 8 ACM
 SG_ Con_USB_Playtype_St : 37|2@0+ (1,0) [0|3] "SED"  APIM_CISM,APIM
 SG_ Con_ShowSWDLBargr_St : 47|7@0+ (1,0) [0|127] "unitless"  APIM_CISM,APIM
 SG_ Con_ShowSWDLprogress_St : 34|3@0+ (1,0) [0|7] "SED"  APIM_CISM,APIM
 SG_ Con_iPod_IntroScan_St : 39|2@0+ (1,0) [0|3] "SED"  APIM_CISM,APIM
 SG_ Con_iPod_Shuffle_St : 17|2@0+ (1,0) [0|3] "SED"  APIM_CISM,APIM
 SG_ Con_iPod_Repeat_St : 20|3@0+ (1,0) [0|7] "SED"  APIM_CISM,APIM
 SG_ Con_USB_Repeat_St : 23|3@0+ (1,0) [0|7] "SED"  APIM_CISM,APIM
 SG_ Con_USB_IntroScan_St : 9|2@0+ (1,0) [0|3] "SED"  APIM_CISM,APIM
 SG_ Con_USB_Shuffle_St : 1|2@0+ (1,0) [0|3] "SED"  APIM_CISM,APIM
 SG_ Con_iPod_Error_St : 27|4@0+ (1,0) [0|15] "SED"  APIM_CISM,APIM
 SG_ Con_USB_Error_St : 31|4@0+ (1,0) [0|15] "SED"  APIM_CISM,APIM
 SG_ Con_iPod_FunctStatus_St : 12|3@0+ (1,0) [0|7] "SED"  APIM_CISM,APIM
 SG_ Con_USB_FunctStatus_St : 4|3@0+ (1,0) [0|7] "SED"  APIM_CISM,APIM
 SG_ Con_USB_OpMode_St : 7|3@0+ (1,0) [0|7] "SED"  APIM_CISM,APIM
 SG_ Con_iPod_OpMode_St : 15|3@0+ (1,0) [0|7] "SED"  APIM_CISM,APIM

BO_ 954 Body_Info_10_HS3: 8 GWM
 SG_ PosLghtFl_D_Stat : 51|2@0+ (1,0) [0|3] "SED"  GENERIC
 SG_ PosLghtFr_D_Stat : 49|2@0+ (1,0) [0|3] "SED"  GENERIC
 SG_ CargoLght_D_Stat : 55|2@0+ (1,0) [0|3] "SED"  APIM_CISM,APIM
 SG_ TlghtTestLght_D_Stat : 44|3@0+ (1,0) [0|7] "SED"  APIM_CISM,APIM
 SG_ LghtAmbDrvMde_B_Stat : 34|1@0+ (1,0) [0|1] "SED"  APIM_CISM,APIM
 SG_ KeylessIdl_B_Stat : 41|1@0+ (1,0) [0|1] "SED"  APIM_CISM,APIM
 SG_ PwRnngBoardPoll_D_Stat : 36|2@0+ (1,0) [0|3] "SED"  GENERIC
 SG_ PoliceDmngLvl_D_Stat : 39|3@0+ (1,0) [0|7] "SED"  APIM,IPC,APIM_CISM,GWM
 SG_ TrlrHitchLamp_D_Stat : 25|1@0+ (1,0) [0|1] "SED"  APIM,APIM_CISM
 SG_ LicPlateLght_B_Stat : 26|1@0+ (1,0) [0|1] "SED"  APIM,APIM_CISM
 SG_ TrukBedLght_B_Stat : 24|1@0+ (1,0) [0|1] "SED"  APIM,APIM_CISM
 SG_ VehWlcmFrwlMde_D_Stat : 29|3@0+ (1,0) [0|7] "SED"  APIM_CISM,RACM_RCIM,APIM,IPC
 SG_ GenericSwtch3_No_Actl : 15|3@0+ (1,0) [0|7] "unitless"  GENERIC
 SG_ GenericSwtch2_No_Actl : 4|3@0+ (1,0) [0|7] "unitless"  GENERIC
 SG_ GenericSwtch1_No_Actl : 7|3@0+ (1,0) [0|7] "unitless"  GENERIC
 SG_ PudSptLghtRight_D_Rq : 17|2@0+ (1,0) [0|3] "SED"  GENERIC
 SG_ PudSptLghtLeft_D_Rq : 19|2@0+ (1,0) [0|3] "SED"  GENERIC
 SG_ ExtLghtRight_D_Stat : 21|2@0+ (1,0) [0|3] "SED"  APIM,APIM_CISM
 SG_ VehWlcmFrwl_D_Stat : 31|2@0+ (1,0) [0|3] "SED"  RACM_RCIM,GENERIC,APIM_CISM,APIM
 SG_ ExtLghtRear_D_Stat : 23|2@0+ (1,0) [0|3] "SED"  APIM,APIM_CISM
 SG_ ExtLghtLeft_D_Stat : 9|2@0+ (1,0) [0|3] "SED"  APIM,APIM_CISM
 SG_ ExtLghtAlrt_B_Rq : 12|1@0+ (1,0) [0|1] "SED"  APIM_CISM,APIM
 SG_ ExtLght_D_Falt : 1|2@0+ (1,0) [0|3] "SED"  APIM_CISM,APIM
 SG_ ExtLghtFront_D_Stat : 11|2@0+ (1,0) [0|3] "SED"  APIM_CISM,APIM
 SG_ TlghtTestPrecnd_D_Stat : 47|3@0+ (1,0) [0|7] "SED"  APIM_CISM,APIM
 SG_ TlghtTest_D_Stat : 33|2@0+ (1,0) [0|3] "SED"  APIM_CISM,APIM

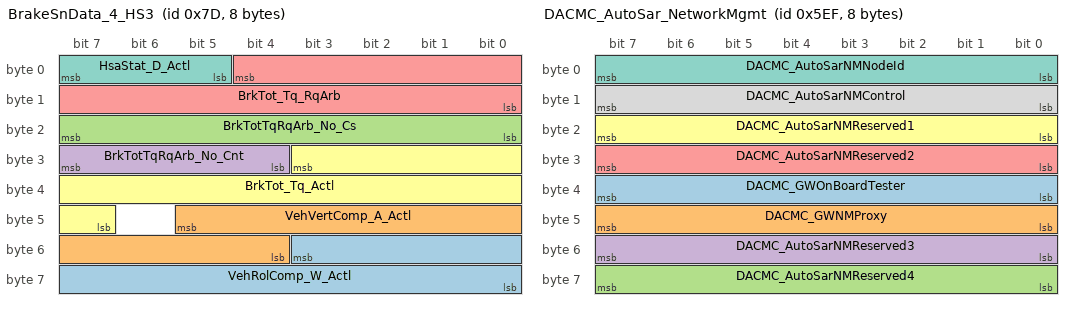
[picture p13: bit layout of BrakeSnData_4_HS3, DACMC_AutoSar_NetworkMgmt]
BO_ 125 BrakeSnData_4_HS3: 8 GWM
 SG_ VehRolComp_W_Actl : 51|12@0+ (0.03663,-75) [-75|74.92659] "degrees/sec"  APIM,APIM_CISM
 SG_ VehVertComp_A_Actl : 45|10@0+ (0.035,-17.9) [-17.9|17.835] "m/s^2"  APIM,APIM_CISM
 SG_ BrkTotTqRqArb_No_Cs : 23|8@0+ (1,0) [0|255] "Unitless"  TRM_ITRM
 SG_ BrkTotTqRqArb_No_Cnt : 31|4@0+ (1,0) [0|15] "Unitless"  TRM_ITRM
 SG_ BrkTot_Tq_RqArb : 4|13@0+ (4,0) [0|32756] "Nm"  TRM_ITRM,APIM_CISM,APIM
 SG_ BrkTot_Tq_Actl : 27|13@0+ (4,0) [0|32756] "Nm"  APIM_CISM,APIM,IPC
 SG_ HsaStat_D_Actl : 7|3@0+ (1,0) [0|7] "SED"  IPC

BO_ 2612224096 PARSEDPushIPCtoGWM_ECG: 8 IPC
 SG_ PARSEDPushIPCtoGWM_ECG : 7|29@0+ (1,0) [0|536870911] "unitless"  GWM

BO_ 2611052760 PARSEDPhysGWM_ECGtoIPC: 8 GWM
 SG_ PARSEDPhysGWM_ECGtoIPC : 7|29@0+ (1,0) [0|536870911] "unitless"  IPC

BO_ 2611175520 PARSEDPhysIPCtoGWM_ECG: 8 IPC
 SG_ PARSEDPhysIPCtoGWM_ECG : 7|29@0+ (1,0) [0|536870911] "unitless"  GWM

BO_ 2610126944 OTAPhysIPCtoGWM_ECG: 8 IPC
 SG_ OTAPhysIPCtoGWM_ECG : 7|29@0+ (1,0) [0|536870911] "unitless"  GWM

BO_ 2610004184 OTAPhysGWM_ECGtoIPC: 8 GWM
 SG_ OTAPhysGWM_ECGtoIPC : 7|29@0+ (1,0) [0|536870911] "unitless"  IPC

BO_ 2005 TesterPhysicalReqDACMC: 8 TSTR
 SG_ TesterPhysicalReqDACMC : 7|64@0+ (1,0) [0|1.84467E+019] "unitless"  DACMC

BO_ 2013 TesterPhysicalResDACMC: 8 DACMC
 SG_ TesterPhysicalResDACMC : 7|64@0+ (1,0) [0|1.84467E+019] "unitless"  TSTR

BO_ 1519 DACMC_AutoSar_NetworkMgmt: 8 DACMC
 SG_ DACMC_GWOnBoardTester : 39|8@0+ (1,0) [0|255] "unitless"  HUD_ADV,GWM
 SG_ DACMC_GWNMProxy : 47|8@0+ (1,0) [0|255] "unitless"  HUD_ADV,GWM
 SG_ DACMC_AutoSarNMReserved4 : 63|8@0+ (1,0) [0|255] "unitless"  HUD_ADV,GWM
 SG_ DACMC_AutoSarNMReserved3 : 55|8@0+ (1,0) [0|255] "unitless"  HUD_ADV,GWM
 SG_ DACMC_AutoSarNMReserved2 : 31|8@0+ (1,0) [0|255] "unitless"  HUD_ADV,GWM
 SG_ DACMC_AutoSarNMReserved1 : 23|8@0+ (1,0) [0|255] "unitless"  HUD_ADV,GWM
 SG_ DACMC_AutoSarNMNodeId : 7|8@0+ (1,0) [0|255] "unitless"  HUD_ADV,GWM
 SG_ DACMC_AutoSarNMControl : 15|8@0+ (1,0) [0|255] "unitless"  HUD_ADV,GWM

BO_ 2612002008 PARSEDFuncGWM_ECG_HS3: 8 GWM
 SG_ PARSEDFuncGWM_ECG : 7|29@0+ (1,0) [0|536870911] "unitless"  WCM,IPC

BO_ 2610953432 OTAFuncGWM_ECG_HS3: 8 GWM
 SG_ OTAFuncGWM_ECG : 7|29@0+ (1,0) [0|536870911] "unitless"  IPC,WCM

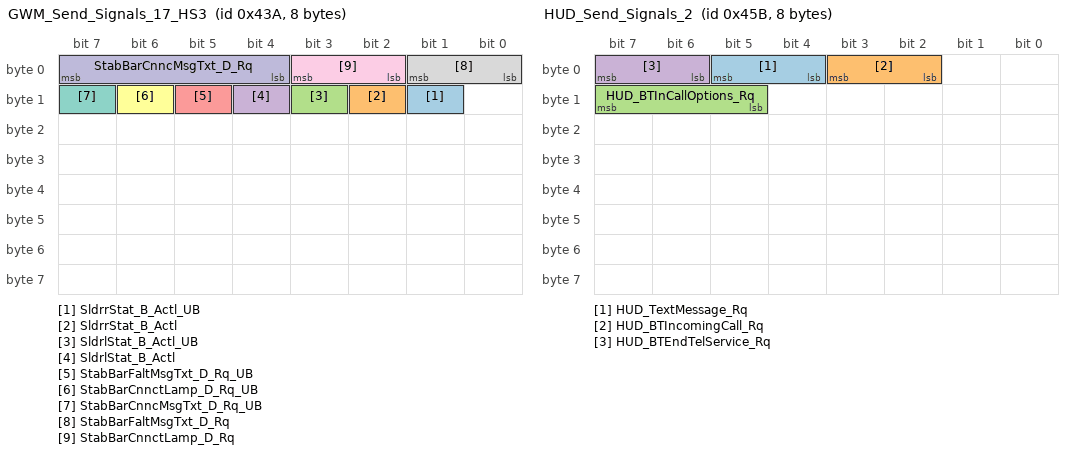
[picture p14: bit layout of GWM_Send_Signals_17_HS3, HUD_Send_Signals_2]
BO_ 1082 GWM_Send_Signals_17_HS3: 8 GWM
 SG_ SldrrStat_B_Actl_UB : 9|1@0+ (1,0) [0|1] "SED"  IPC
 SG_ SldrrStat_B_Actl : 10|1@0+ (1,0) [0|1] "SED"  IPC
 SG_ SldrlStat_B_Actl_UB : 11|1@0+ (1,0) [0|1] "SED"  IPC
 SG_ SldrlStat_B_Actl : 12|1@0+ (1,0) [0|1] "SED"  IPC
 SG_ StabBarFaltMsgTxt_D_Rq_UB : 13|1@0+ (1,0) [0|1] "SED"  IPC
 SG_ StabBarCnnctLamp_D_Rq_UB : 14|1@0+ (1,0) [0|1] "SED"  APIM_CISM,IPC,APIM
 SG_ StabBarCnncMsgTxt_D_Rq_UB : 15|1@0+ (1,0) [0|1] "SED"  IPC
 SG_ StabBarFaltMsgTxt_D_Rq : 1|2@0+ (1,0) [0|3] "SED"  IPC
 SG_ StabBarCnnctLamp_D_Rq : 3|2@0+ (1,0) [0|3] "SED"  APIM_CISM,IPC,APIM
 SG_ StabBarCnncMsgTxt_D_Rq : 7|4@0+ (1,0) [0|15] "SED"  IPC

BO_ 576 AUDIO_RDISP2_WORD_Tx: 8 ACM
 SG_ AUDIO_RDISP2_WORD_Tx : 7|64@0+ (1,0) [0|1.84467440737096E+019] "unitless"  HUD_ADV

BO_ 1115 HUD_Send_Signals_2: 8 HUD_ADV
 SG_ HUD_TextMessage_Rq : 5|2@0+ (1,0) [0|3] "SED"  APIM_CISM,APIM
 SG_ HUD_BTIncomingCall_Rq : 3|2@0+ (1,0) [0|3] "SED"  APIM_CISM,APIM
 SG_ HUD_BTInCallOptions_Rq : 15|3@0+ (1,0) [0|7] "SED"  APIM_CISM,APIM
 SG_ HUD_BTEndTelService_Rq : 7|2@0+ (1,0) [0|3] "SED"  APIM_CISM,APIM

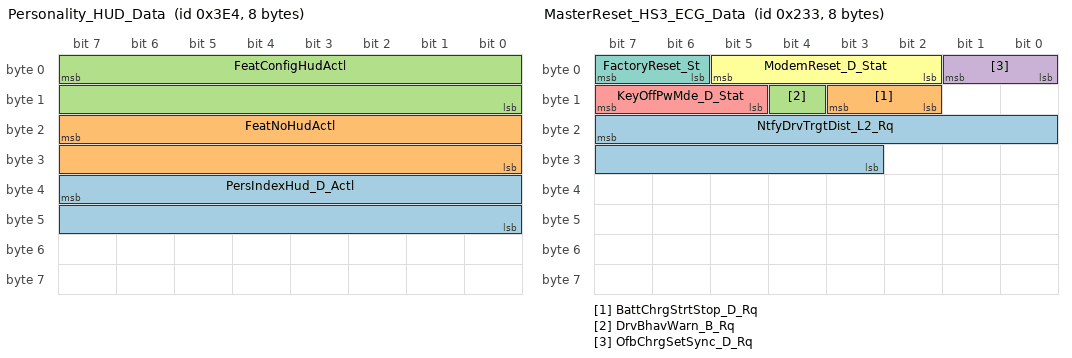
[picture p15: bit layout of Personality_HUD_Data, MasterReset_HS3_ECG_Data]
BO_ 996 Personality_HUD_Data: 8 HUD_ADV
 SG_ PersIndexHud_D_Actl : 39|16@0+ (1,0) [0|65535] "Unitless"  IPC
 SG_ FeatNoHudActl : 23|16@0+ (1,0) [0|65535] "Unitless"  IPC
 SG_ FeatConfigHudActl : 7|16@0+ (1,0) [0|65535] "Unitless"  IPC

BO_ 588 RDRV_RDISP2_WORD_Rx: 8 HUD_ADV
 SG_ RDRV_RDISP2_WORD_Rx : 7|64@0+ (1,0) [0|1.84467440737096E+019] "unitless"  GENERIC

BO_ 811 APIM_Data: 8 APIM
 SG_ ExtLghtDsply_D_Stat : 7|3@0+ (1,0) [0|7] "SED"  GWM
 SG_ SpeedoMajorUnit_D_Confg : 59|2@0+ (1,0) [0|3] "SED"  GWM
 SG_ ScMnSoc_Pc_RqMnu : 55|7@0+ (1,0) [0|125] "percent"  GWM
 SG_ ScEnbl_D_RqMnu : 57|2@0+ (1,0) [0|3] "SED"  GWM
 SG_ OnePdlDrvButtn_B_Falt : 16|1@0+ (1,0) [0|1] "SED"  GWM
 SG_ OnePdlDrvButtn_B_Stat : 48|1@0+ (1,0) [0|1] "SED"  GWM
 SG_ LongTermReset_B_RqMnu : 17|1@0+ (1,0) [0|1] "SED"  GWM
 SG_ DistToStopover_L_Actl : 31|16@0+ (0.1,0) [0|6553.4] "kilometer"  IPC,GWM
 SG_ StopoverType_D_Stat : 47|3@0+ (1,0) [0|0] "SED"  IPC,GWM
 SG_ ExtLghtRight_D_RqMnu : 11|3@0+ (1,0) [0|7] "SED"  GWM
 SG_ AutoLghtOvrrd_B_RqDrv : 8|1@0+ (1,0) [0|1] "SED"  GWM
 SG_ ExtLghtRear_D_RqMnu : 14|3@0+ (1,0) [0|7] "SED"  GWM
 SG_ ExtLghtLeft_D_RqMnu : 1|3@0+ (1,0) [0|7] "SED"  GWM
 SG_ ExtLghtFront_D_RqMnu : 4|3@0+ (1,0) [0|7] "SED"  GWM
 SG_ BecRleas_No_RqMnu : 23|3@0+ (1,0) [0|7] "unitless"  GWM
 SG_ TrnkFrontRleas_No_RqMnu : 20|3@0+ (1,0) [0|7] "unitless"  GWM
 SG_ GoTEditMnte_T_RqMnu : 63|4@0+ (1,0) [0|15] "SED"  GWM
 SG_ GoTEditHr_T_RqMnu : 44|5@0+ (1,0) [0|29] "SED"  GWM

BO_ 543 TelTaleData: 8 IPC
 SG_ TeltalWarnData_No_Actl : 7|64@0+ (1,0) [0|1.84467E+019] "unitless"  APIM,GWM,APIM_CISM

BO_ 563 MasterReset_HS3_ECG_Data: 8 GWM
 SG_ NtfyDrvTrgtDist_L2_Rq : 23|13@0+ (0.1,0) [0|818.9] "Km"  GENERIC
 SG_ BattChrgStrtStop_D_Rq : 11|2@0+ (1,0) [0|3] "SED"  GENERIC
 SG_ DrvBhavWarn_B_Rq : 12|1@0+ (1,0) [0|1] "SED"  IPC
 SG_ OfbChrgSetSync_D_Rq : 1|2@0+ (1,0) [0|3] "SED"  APIM,APIM_CISM
 SG_ KeyOffPwMde_D_Stat : 15|3@0+ (1,0) [0|7] "SED"  APIM_CISM,APIM
 SG_ ModemReset_D_Stat : 5|4@0+ (1,0) [0|15] "SED"  APIM_CISM,ACM,APIM
 SG_ FactoryReset_St : 7|2@0+ (1,0) [0|3] "SED"  APIM_CISM,ACM,APIM

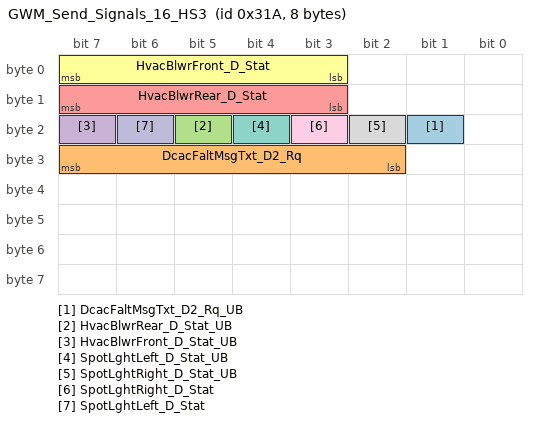
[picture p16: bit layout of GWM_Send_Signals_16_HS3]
BO_ 794 GWM_Send_Signals_16_HS3: 8 GWM
 SG_ DcacFaltMsgTxt_D2_Rq_UB : 17|1@0+ (1,0) [0|1] "SED"  APIM,APIM_CISM
 SG_ DcacFaltMsgTxt_D2_Rq : 31|6@0+ (1,0) [0|63] "SED"  APIM,APIM_CISM
 SG_ HvacBlwrRear_D_Stat_UB : 21|1@0+ (1,0) [0|1] "SED"  WCM
 SG_ HvacBlwrFront_D_Stat_UB : 23|1@0+ (1,0) [0|1] "SED"  WCM
 SG_ HvacBlwrRear_D_Stat : 15|5@0+ (1,0) [0|31] "SED"  WCM
 SG_ HvacBlwrFront_D_Stat : 7|5@0+ (1,0) [0|31] "SED"  WCM
 SG_ SpotLghtLeft_D_Stat_UB : 20|1@0+ (1,0) [0|1] "SED"  APIM,APIM_CISM
 SG_ SpotLghtRight_D_Stat_UB : 18|1@0+ (1,0) [0|1] "SED"  APIM,APIM_CISM
 SG_ SpotLghtRight_D_Stat : 19|1@0+ (1,0) [0|1] "SED"  APIM,APIM_CISM
 SG_ SpotLghtLeft_D_Stat : 22|1@0+ (1,0) [0|1] "SED"  APIM_CISM,APIM

BO_ 587 PHONE_RDISP2_WORD_Rx: 8 HUD_ADV
 SG_ PHONE_RDISP2_WORD_Rx : 7|64@0+ (1,0) [0|1.84467440737096E+019] "unitless"  APIM_CISM,ACM,APIM

BO_ 579 PHONE_RDISP2_WORD_Tx: 8 APIM
 SG_ PHONE_RDISP2_WORD_Tx : 7|64@0+ (1,0) [0|1.84467440737096E+019] "unitless"  HUD_ADV

BO_ 585 NAV_RDISP2_WORD_Rx: 8 HUD_ADV
 SG_ NAV_RDISP2_WORD_Rx : 7|64@0+ (1,0) [0|1.84467440737096E+019] "unitless"  APIM_CISM,APIM

BO_TX_BU_ 547 : APIM_CISM,ACM;
BO_TX_BU_ 732 : APIM_CISM,ACM;
BO_TX_BU_ 728 : APIM_CISM,ACM;
BO_TX_BU_ 489 : APIM_CISM,ACM;
BO_TX_BU_ 757 : APIM_CISM,ACM;
BO_TX_BU_ 734 : APIM_CISM,ACM;
BO_TX_BU_ 759 : APIM_CISM,ACM;
BO_TX_BU_ 144 : APIM_CISM,APIM;
BO_TX_BU_ 700 : APIM_CISM,APIM;
BO_TX_BU_ 1124 : APIM_CISM,APIM;
BO_TX_BU_ 1123 : APIM_CISM,APIM;
BO_TX_BU_ 1122 : APIM_CISM,APIM;
BO_TX_BU_ 1244 : APIM_CISM,ACM;
BO_TX_BU_ 1243 : APIM_CISM,ACM;
BO_TX_BU_ 681 : APIM_CISM,ACM;
BO_TX_BU_ 744 : APIM_CISM,ACM;
BO_TX_BU_ 741 : APIM_CISM,ACM;
BO_TX_BU_ 576 : APIM_CISM,ACM;
BO_TX_BU_ 811 : APIM_CISM,APIM;
BO_TX_BU_ 579 : APIM_CISM,APIM;
CM_ SG_ 547 Audio_Amp_St "Object. Audio_Amp_St";
CM_ SG_ 547 Chime_Alert_Chan2 "Object.AlertMethod. AHU_Alerts";
CM_ SG_ 547 AHU_Chime2_Active "Object. AlertMethod. AHU_Alerts

0x0 Inactive
0x1 No_Chime
0x2 Chime_1
0x3 Chime_2
0x4 Chime_3
cont.
0x3F Chime_62";
CM_ SG_ 547 AHU_Chime2_Not_Recognized "Object.AlertMethod. AHU_Alerts";
CM_ SG_ 547 Chime_Alert_Chan "Object.AlertMethod. AHU_Alerts";
CM_ SG_ 547 AHU_Alert_Channel1 "Object.AlertMethod.AHU_Alerts

";
CM_ SG_ 547 AHU_Chime_Supported "Object.AlertMethod. AHU_Alerts";
CM_ SG_ 547 AHU_Chime_Active "Object. AlertMethod. AHU_Alerts

0x0 Inactive
0x1 No_Chime
0x2 Chime_1
0x3 Chime_2
0x4 Chime_3
cont.
0x3F Chime_62";
CM_ SG_ 547 AHU_Chime_Not_Recognized "Object.AlertMethod. AHU_Alerts";
CM_ SG_ 547 AHU_AdjChimVolSupp2_St "AdjustableChimeVolSupported2";
CM_ SG_ 547 AHU_AdjChimeVolSupp_St "AdjustableChimeVolSupported";
CM_ SG_ 732 ACU_CurrItemsInFMSL_St "Object Tuner.CurrentItemsInFMSL";
CM_ SG_ 732 ACU_FunctionStatus_St "Object Indash CD Changer.FunctionStatus
Object Single CD.FunctionStatus";
CM_ SG_ 732 ACU_CurrFMSLPreset_St "Object Tuner.CurrentFMSLPreset

Not applicable for LLA, HLA
CurrentSLIndex";
CM_ SG_ 732 ACU_CurrPreset2_St "Object Tuner.CurrentPreset2";
CM_ SG_ 732 ACU_StorePreset_St "Object Tuner.StorePreset";
CM_ SG_ 732 ACU_VoiceCommand_St "Object VoiceRecogniser.VoiceCommand";
CM_ SG_ 732 ACU_CurrMixPreset_St "Object Tuner.CurrMixPreset";
CM_ SG_ 728 ACU_AuxVolume_Up "Object Audio.Volume_UP
Indicate user value recalls if the value is set to lower/upper border ";
CM_ SG_ 728 ACU_AuxVolume_St "Object Audio.AuxVolume

Level 0..30";
CM_ SG_ 728 ACU_Mid_St "Object Audio.Mid

Level -7..0..7


Method: AHU_Midrange";
CM_ SG_ 728 ACU_RadioSeekMode_St "Object Tuner.RadioSeekMode";
CM_ SG_ 728 ACU_Volume_St "Object Audio.Volume

Level 0..30
Method AHU_Audio_Vol_Level

Refer method table in SPSS for details
0x0 No Volume
0x1 Vol_Step1
0x2 Vol_Step2
0x3 Vol_Step3
Cont.
0x1E Vol_Step30";
CM_ SG_ 728 ACU_Volume_Up "Object Audio.Volume_UP
Indicate user value recalls if the value is set to lower/upper border 
Method AHU_Audio_Vol_Updated";
CM_ SG_ 728 ACU_CurrentStatFlags_St "Object Tuner.CurrentStatFlags

Bit 0: Validation
Bit 1: EON not sup; 1: EON sup
Bit 2: TP not sup; 1: TP sup
Bit 3: 0: Mono; 1: Stereo
Bit 4: 0: RDS not sup; 1: RDS sup";
CM_ SG_ 489 ACU_CurrentPSName_St "Object Tuner.CurrentPSName
Object Tuner.DAB.CurrentServiceName

Text with maximum 8 characters";
CM_ SG_ 757 ACU_AutoStoreResult_St "Object Tuner. RadioSeekModeResult";
CM_ SG_ 757 ACU_DirectTune_St "Object.Tuner.DirectTune";
CM_ SG_ 757 ACU_RadioSeekMode2_St "Object Tuner.RadioSeekMode2";
CM_ SG_ 757 ACU_CurrTUBand_St "Object.Tuner.CurrentTUBand";
CM_ SG_ 734 ACU_ActServiceLink_St "Object DAB.ActServiceLink";
CM_ SG_ 734 ACU_CurrTUDRService2_St "Object DAB.CurrentDRServiceStatus";
CM_ SG_ 734 ACU_ComTUSIDValid_St "Object DAB.CurrentSID.Availability
";
CM_ SG_ 734 ACU_CurrTUDABBlock_St "Object DAB.CurrentDABBlock
Bitfield:
Bit 0..4: L-Band Canada: Numeric value (NV)(1 .. 23); L-Band Europe: NV (A=1 .. W=23); Band III: NV (A=1 .. W=23); 
Bit 5..8: Band III: NV (not used for L-Band; set value to 0h)
Bit 9: 0: Band III, 1: L-Band
";
CM_ SG_ 734 ACU_CurrTUDRService_St "Object DAB.CurrentDRServiceStatus";
CM_ SG_ 734 ACU_CurrTURadioBand_St "Object DAB.CurrentTUBand

Gen3 Values 
$1: reserved
$2: reserved 
$3: reserved
$4: reserved
$5: reserved
$6: reserved";
CM_ SG_ 734 ACU_CurrTUSCIDI_St "Object DAB.CurrentSCIDI";
CM_ SG_ 734 ACU_CurrTUServiceLink_St "Object DAB.CurrentServiceLink";
CM_ SG_ 734 ACU_CurrTUSID_St "Object DAB.CurrentSID.SID

For Digital Radio: 
Byte 1..2: 16 bit hex coded SID
Byte 3:     8 bit hex coded ECC";
CM_ SG_ 759 Avail_HD_Chan_Valid "Object. AvailableHDChannel.St";
CM_ SG_ 759 Avail_HD_Chan_St_7 "Object. AvailableHDChannel.St";
CM_ SG_ 759 Avail_HD_Chan_St_6 "Object. AvailableHDChannel.St";
CM_ SG_ 759 Avail_HD_Chan_St_5 "Object. AvailableHDChannel.St";
CM_ SG_ 759 Avail_HD_Chan_St_4 "Object. AvailableHDChannel.St";
CM_ SG_ 759 Avail_HD_Chan_St_3 "Object. AvailableHDChannel.St";
CM_ SG_ 759 Avail_HD_Chan_St_2 "Object. AvailableHDChannel.St";
CM_ SG_ 759 Avail_HD_Chan_St_1 "Object. AvailableHDChannel.St";
CM_ SG_ 759 ACM_StationListScanSt "Object.AMFMSlave.StationListScan
$0:Invalid";
CM_ SG_ 759 ACM_TagMode "Object.AMFMSlave.TagMode";
CM_ SG_ 759 ACM_RBDSMode "Object.AMFMSlave.RBDSMode";
CM_ SG_ 759 NumofHDMulticastChans_St "Object. AMFMSlave.NumofHDMulticastChans";
CM_ SG_ 759 ACM_HDModeStatus "Object.AMFMSlave.HDMode";
CM_ SG_ 759 ACM_HDChanStatus "Object. AMFMSlave.HDChanStatus
$0:Inactive";
CM_ SG_ 759 ACM_CurrentSSName "Object.AMFMSlave.Method CurrentSSName";
CM_ SG_ 759 ACM_CurrentHDMulticast_St "Object.AMFMSlave.CurrentHDMulticast";
CM_ BO_ 144 "GW Message IMS->BMS";
CM_ SG_ 144 SetTimeFormat "Object.BodyInterface.Settings.VehicleTimeFormatUserSelection";
CM_ SG_ 144 SetYear "Object Clock.SetYear

Request from the Audio Control Unit to the Cluster in order to adjust the years, with an offset of 2000.";
CM_ SG_ 144 SetMonth "Object Clock.SetMonth

Request from the Audio Control Unit to the Cluster in order to adjust the months.";
CM_ SG_ 144 SetDay "Object Clock.SetDay

Request from the Audio Control Unit to the Cluster in order to adjust the days.";
CM_ SG_ 144 SetHour "Object Clock.SetHour

Request from the Audio Control Unit to the Cluster in order to adjust the hours.";
CM_ SG_ 144 SetMinute "Object Clock.SetMinute

Request from the Audio Control Unit to the Cluster in order to adjust the minutes.";
CM_ SG_ 144 SetSecond "Object Clock.SetSecond

Request from the Audio Control Unit to the Cluster in order to adjust the seconds.";
CM_ SG_ 144 TimeAdjustRequest "Object Clock.TimeAdjustRequest

Request from the Audio Control Unit to the Cluster in order to adjust the time.";
CM_ SG_ 144 DateAdjustRequest "Object Clock.DateAdjustRequest

Request from the Audio Control Unit to the Cluster in order to adjust the date.";
CM_ SG_ 851 ConsUnitIPC_D_Dsply "Communicates the instrument cluster current unit mode setting. Used thru-out displays to update units and labels for the fuel consumption history displays. If units updated on cluster, other displays thru-out vehicle should be updated as well.";
CM_ SG_ 792 ElTrip_L_Dsply "Key cycle trip distance driven with the engine off (Trip EV Miles)";
CM_ SG_ 792 ElLongTerm_L_Dsply "Long term distance distance driven with the engine off since the last long term reset (Long Term EV Miles).";
CM_ SG_ 787 VehElSurpStat_L_Dsply "Number of surplus / debt miles displayed on the BEV instrument cluster. Used for BEV cluster and centerstack displays in both numerical an emotive displays. Negative numbers mean a debt, positive numbers are a surplus. ";
CM_ SG_ 787 TripSum_Vl_Dsply "This signal represents the total fuel used by the vehicle on the current trip. It is intended to be used on the cluster shutdown summary screen and in remote data functions (i.e. MyData).";
CM_ SG_ 787 TripSum_E_Dsply "This signal represents the total energy used by the vehicle on the current trip. It is intended to be used on the cluster shutdown summary screen.";
CM_ SG_ 787 TripSum_L_Dsply "Trip Length (Last Drive)";
CM_ SG_ 697 AUDIO_MC_WORD_Rx "MM ISO 15765-2 Message Catalogue
Section MC - Audio";
CM_ SG_ 700 AUDIO_RDISP_WORD_Rx "MM ISO 15765-2 Message Catalogue
Section RDISP - Audio
";
CM_ SG_ 676 MC_RDISP_WORD_Tx "Communicates ConsHistGraph_St, which includes data to populate the consumption history display.";
CM_ SG_ 504 Mc_AudioSourceSel_Rq "Object Single CD.GetFolderName.AudioSource
Object Media Player
BTAudio.GetFolderName.AudioSource
BTAudio.SetTrack.AudioSource
USB.GetFolderName.AudioSource
USB.SetTrack.AudioSource
SDCard.GetFolderName.AudioSource
SDCard.SetTrack.AudioSource";
CM_ SG_ 504 Mc_FolderNumber_Rq "Object Media Player BTAudio.GetFolderName.FolderName
Object Media Player USB.GetFolderName.FolderName
Object Single CD.GetFolderName.FolderNumber
Object Media Player SDCard.FolderNumber

$FFFF: Inactive";
CM_ SG_ 504 Mc_CutItem_Rq "Object Media Player BTAudio.GetFolderName.CutItemName
Object Media Player USB.GetFolderName.CutItemName
Object Single CD.GetFolderName.CutItem
Object Media Player SDCard.CutItem";
CM_ SG_ 504 Mc_ItemNameLength_Rq "Object Media Player BTAudio.GetFolderName.ItemNameLength
Object Media Player USB.GetFolderName.ItemNameLength
Object Media Player SDCard.GetFolderName.ItemNameLength
Object Single CD.GetFolderName.ItemNameLength";
CM_ SG_ 504 Mc_SourceSetTrack_Rq "Object Media Player BTAudio.SetTrack
Object Media Player USB.SetTrack
Object Media Player SDCard.SetTrack

$0000: Inactive";
CM_ SG_ 410 MyKey_e911Override_St "Object MyKey.MyKey_e911Override_St";
CM_ SG_ 410 DoNotDisturbOveride_St "Object MyKey.DoNotDisturbOverride_St 
";
CM_ BO_ 1124 "HS3 APIM Sync Gen3 Tx 0x464.  FrameGateway to 0x467 on HS1, HS2, HS3 and MS1.";
CM_ BO_ 1123 "HS3 APIM Sync Gen3 Tx 0x463.  FrameGateway to 0x466 on HS1, HS2, HS3 and MS1.";
CM_ BO_ 1122 "HS3 APIM Sync Gen3 Tx 0x462.  FrameGateway to 0x465 on HS1, HS2, HS3 and MS1.";
CM_ SG_ 1136 GboxOil_Te_Actl "Signal not transmitted on HEV variants. MHT(U611/625) HPCM Rx 0x230 from PCM_HEV. Powersplit FWD HEV’s(Cx482/3 430) HPCM Tx 0x230.";
CM_ BO_ 1106 " new RCM Serial Trailer Aid (TrailerAid_Stat1) 48 bits";
CM_ SG_ 1086 ElLoadCtl_D_Rq "Signal not transmitted on HEV variants.";
CM_ BO_ 611 "Used on Applications with 4x4 supplied by Motorola.";
CM_ SG_ 611 AwdStat_D_RqDsply "Signal not transmitted on programs that do not have AWD.";
CM_ SG_ 611 AwdSrvcRqd_B_Rq "Signal not transmitted on programs that do not have AWD.";
CM_ SG_ 611 AwdLck_Tq_Rq "Signal not transmitted on programs that do not have AWD.";
CM_ SG_ 264 BpedDrvAppl_D_Actl "CCMGenSigTimeoutTime=1000";
CM_ SG_ 969 TurnLampRrOut_B_Stat "Signal not transmitted on vehicles without a BCMB module.";
CM_ SG_ 969 TurnLampRlOut_B_Stat "Signal not transmitted on vehicles without a BCMB module.";
CM_ SG_ 130 SelDrvMdeSwtch3_D_Stat4 "ECM_HEV does not support or Transmit signal.";
CM_ SG_ 1244 Con_InfotainmentVer_St "Object Configuration Management.CON_InfotainmetVer";
CM_ SG_ 1244 Con_Profiles_St "Object Configuration Management.CON_Profiles

Bit 0: 0: invalid 1: valid
Bit 1: 0: No iPod browsing support 1: iPod browsing support
Bit 2: 0: No USB browsing support 1: USB browsing support
Bit 3: Reserved
Bit 4: Reserved";
CM_ SG_ 1244 Con_Configuration "Object Configuration Management.CON_Configuration

Bit 0: 0=invalid, 1=valid
Bit 1: SWDLviaUSB support: 0=No, 1=Yes
Bit 2: iPod support 0=No, 1:=Yes
Bit 3: USB support 0=No, 1=Yes
Bit 4: Reserved";
CM_ SG_ 1243 Con_BTAud_InfotainmVer_St "Object Configuration Management.BTAud_InfotainmentVer";
CM_ SG_ 1243 Con_BTAud_Profiles_St "Object Configuration Management.BTAud_Profiles

Bit 0: 0: invalid 1: valid
Bit 1: 0: No BTAudio browsing support 1: BTAudio browsing support
Bit 2: 0: No BTAudio device setting support 1: BTAudio device setting support
Bit 3: ElapsedRemainingTiming

";
CM_ SG_ 1243 Con_BTAudConfiguration "Object Configuration Management.BTAud_Configuration

Bit 0: 0: invalid 1: valid
Bit 1: 0: No BTAudio streaming support 1: BTAudio streaming
Bit 2: 0: No mobile navigation support 1: Mobile navigation";
CM_ SG_ 681 Con_DB1temIndex_St "Object Media Player iPod.MDBActiveTrack.ItemIndex";
CM_ SG_ 681 Con_DB1FilterConfig_St "Object Media Player iPod.MDBActiveTrack.MDBFilterConf";
CM_ SG_ 681 Con_DB1Filter3_St "Object Media Player iPod.MDBActiveTrack.MDBFilter3";
CM_ SG_ 681 Con_DB1Filter2_St "Object Media Player iPod..MDBActiveTrack.MDBFilter2";
CM_ SG_ 681 Con_DB1Filter1_St "Object Media Player iPod..MDBActiveTrack.MDBFilter1";
CM_ SG_ 744 Con_USB_ActTrNum1_St "Object Media Player USB.ActiveTrackNum1";
CM_ SG_ 744 Con_iPod_NumberOfTracks "Object Media Player USB..NumberofTracks
Info: Tracks in current folder";
CM_ SG_ 744 Con_USB_NumberOfTracks "Object Media Player USB..NumberofTracks
Info: Tracks in current folder";
CM_ SG_ 741 Con_USB_Playtype_St "Object Media Player USB.Playtype
Playtype:
Playlist is selected if CON module plays tracks out of a Playlist
";
CM_ SG_ 741 Con_ShowSWDLBargr_St "Object SWDL.ShowSWDLBargraphStatus

Range (dec): 0% - 100% (0x00 - 0x64)

No update in progress: ConnectivitySWUpdateNotRunning: $7E";
CM_ SG_ 741 Con_ShowSWDLprogress_St "Object SWDL.Con_ShowCONSWDL_St";
CM_ SG_ 741 Con_iPod_IntroScan_St "Object Media Player iPod.Introscan";
CM_ SG_ 741 Con_iPod_Shuffle_St "Object Media Player iPod.Shuffle";
CM_ SG_ 741 Con_iPod_Repeat_St "Object Media Player iPod.Repeat";
CM_ SG_ 741 Con_USB_Repeat_St "Object Media Player USB.Repeat";
CM_ SG_ 741 Con_USB_IntroScan_St "Object Media Player USB.IntroScan";
CM_ SG_ 741 Con_USB_Shuffle_St "Object MediaPlayer USB.Shuffle";
CM_ SG_ 741 Con_iPod_Error_St "Object Media Player iPod.iPodError";
CM_ SG_ 741 Con_USB_Error_St "Object Media Player USB.USBError";
CM_ SG_ 741 Con_iPod_FunctStatus_St "Object Media Player iPod.FunctionStatus";
CM_ SG_ 741 Con_USB_FunctStatus_St "Object Media Player USB.FunctionStatus";
CM_ SG_ 741 Con_USB_OpMode_St "Object Media Player USB.OperationMode";
CM_ SG_ 741 Con_iPod_OpMode_St "Object Media Player iPod.OperationMode";
CM_ SG_ 954 GenericSwtch2_No_Actl "U625 Police Wig Wag feature";
CM_ BO_ 2611175520 "TpTxIndex = 463569112 paired to 0x1BA180D8";
CM_ BO_ 2610126944 "TpTxIndex = 462520536 which is paired to 0x1B9180D8 OTAPhysGWM_ECGtoIPC ";
CM_ SG_ 576 AUDIO_RDISP2_WORD_Tx "MM ISO 15765-2 Message Catalogue AUDIO - RDISP2";
CM_ SG_ 1115 HUD_TextMessage_Rq "Object. BTPhoneClient.TextMessage.Rq";
CM_ SG_ 1115 HUD_BTIncomingCall_Rq "Object Bluetooth Phone.BTIncomingCall";
CM_ SG_ 1115 HUD_BTInCallOptions_Rq "Object.BTPhoneClient.BTInCallOptions.Rq.SingleParam";
CM_ SG_ 1115 HUD_BTEndTelService_Rq "Object Bluetooth Phone.BTEndTelService";
CM_ SG_ 588 RDRV_RDISP2_WORD_Rx "MM ISO 15765-2 Message Catalogue RDISP2 - RDRV";
CM_ SG_ 563 NtfyDrvTrgtDist_L2_Rq "Object.SetTripRangeAlert_Rq
This signal is meant to provide the customer settings for the target distance remote notification";
CM_ SG_ 587 PHONE_RDISP2_WORD_Rx "MM ISO 15765-2 Message Catalogue
Section MC - PHONE";
CM_ SG_ 579 PHONE_RDISP2_WORD_Tx "MM ISO 15765-2 Message Catalogue
Section  PHONE - MC";
CM_ SG_ 585 NAV_RDISP2_WORD_Rx "MM ISO 15765-2 Message Catalogue NavRepClient2 - NavRepServer";
BA_DEF_ BO_  "FrameRouting" STRING ;
BA_DEF_ BO_  "FrameGatewayNetwork" STRING ;
BA_DEF_ BO_  "NetworkInitialization" ENUM  "No","Yes";
BA_DEF_ BO_  "FrameGatewayId" HEX 0 1407;
BA_DEF_ BO_  "EventRateOfChange" INT 10 10000;
BA_DEF_ BO_  "GenMsgStartDelayTime" INT 0 10000;
BA_DEF_ BO_  "GenMsgNrOfRepetition" INT 0 100;
BA_DEF_ BO_  "GenMsgDelayTime" INT 0 1000;
BA_DEF_ BO_  "GenMsgCycleTime" INT 0 100000;
BA_DEF_ BO_  "GenMsgSendType" ENUM  "FixedPeriodic","Event","EnabledPeriodic","NotUsed","NotUsed","EventPeriodic","NotUsed","NotUsed","NoMsgSendType";
BA_DEF_ SG_  "U_U55X_MY2022_Tx" ENUM  "No","Yes";
BA_DEF_ SG_  "U_CD542_MY2021_Tx" ENUM  "No","Yes";
BA_DEF_ SG_  "ECGUsedTxSignal" ENUM  "No","Yes";
BA_DEF_ SG_  "U_T6_MCA_MY2020_Tx" ENUM  "No","Yes";
BA_DEF_ SG_  "U_P702_MY2021_Tx" ENUM  "No","Yes";
BA_DEF_ SG_  "U_CX727_MY2021_Tx" ENUM  "No","Yes";
BA_DEF_ SG_  "U_FNV2_IVI_Rx" ENUM  "No","Yes";
BA_DEF_ SG_  "U_U55X_MY2022_Rx" ENUM  "No","Yes";
BA_DEF_ SG_  "U_CD542_MY2021_Rx" ENUM  "No","Yes";
BA_DEF_ SG_  "ECGUsedRxSignal" ENUM  "No","Yes";
BA_DEF_ SG_  "U_T6_MCA_MY2020_Rx" ENUM  "No","Yes";
BA_DEF_ SG_  "U_P702_MY2021_Rx" ENUM  "No","Yes";
BA_DEF_ SG_  "U_CX727_MY2021_Rx" ENUM  "No","Yes";
BA_DEF_ SG_  "GenSigStartValue" HEX 0 268435455;
BA_DEF_ SG_  "MetaData" ENUM  "No","Yes";
BA_DEF_ SG_  "ContentDependant" ENUM  "No","Yes";
BA_DEF_ SG_  "GenSigStartValueInteger" INT 0 1000000000;
BA_DEF_ SG_  "UsedOnPgmDBC" ENUM  "No","Yes";
BA_DEF_ SG_  "WakeupSignal" ENUM  "No","Yes";
BA_DEF_ SG_  "GenSigInactiveValue" INT 0 100000;
BA_DEF_ SG_  "GenSigSendType" ENUM  "Cyclic","OnWrite","vector_leerstring","OnChange","vector_leerstring","IfActive","vector_leerstring","NoSigSendType";
BA_DEF_ BO_  "OvtpPushApplication" ENUM  "FALSE","TRUE";
BA_DEF_ BO_  "SCP_FreshnessValueLength" INT 0 512;
BA_DEF_ BO_  "SCP_FreshnessValueTxLength" INT 0 512;
BA_DEF_ BO_  "SCP_AuthInfoTxLength" INT 0 512;
BA_DEF_ BO_  "GenMsgRoutingTimeoutTime" INT 0 5000;
BA_DEF_ BO_  "MessageGateway" ENUM  "No","Yes";
BA_DEF_ BO_  "NmAsrMessage" ENUM  "No","Yes";
BA_DEF_ BO_  "DiagState" ENUM  "No","Yes";
BA_DEF_ BO_  "TpTxIndex" INT 0 536870911;
BA_DEF_ BO_  "DiagRequest" ENUM  "No","Yes";
BA_DEF_ BO_  "DiagResponse" ENUM  "No","Yes";
BA_DEF_ BO_  "GenMsgILSupport" ENUM  "No","Yes";
BA_DEF_DEF_  "FrameRouting" "";
BA_DEF_DEF_  "FrameGatewayNetwork" "NONE";
BA_DEF_DEF_  "NetworkInitialization" "Yes";
BA_DEF_DEF_  "FrameGatewayId" 0;
BA_DEF_DEF_  "EventRateOfChange" 10000;
BA_DEF_DEF_  "GenMsgStartDelayTime" 0;
BA_DEF_DEF_  "GenMsgNrOfRepetition" 1;
BA_DEF_DEF_  "GenMsgDelayTime" 20;
BA_DEF_DEF_  "GenMsgCycleTime" 0;
BA_DEF_DEF_  "GenMsgSendType" "NoMsgSendType";
BA_DEF_DEF_  "U_U55X_MY2022_Tx" "No";
BA_DEF_DEF_  "U_CD542_MY2021_Tx" "No";
BA_DEF_DEF_  "ECGUsedTxSignal" "No";
BA_DEF_DEF_  "U_T6_MCA_MY2020_Tx" "No";
BA_DEF_DEF_  "U_P702_MY2021_Tx" "No";
BA_DEF_DEF_  "U_CX727_MY2021_Tx" "No";
BA_DEF_DEF_  "U_FNV2_IVI_Rx" "No";
BA_DEF_DEF_  "U_U55X_MY2022_Rx" "No";
BA_DEF_DEF_  "U_CD542_MY2021_Rx" "No";
BA_DEF_DEF_  "ECGUsedRxSignal" "No";
BA_DEF_DEF_  "U_T6_MCA_MY2020_Rx" "No";
BA_DEF_DEF_  "U_P702_MY2021_Rx" "No";
BA_DEF_DEF_  "U_CX727_MY2021_Rx" "No";
BA_DEF_DEF_  "GenSigStartValue" 0;
BA_DEF_DEF_  "MetaData" "No";
BA_DEF_DEF_  "ContentDependant" "No";
BA_DEF_DEF_  "GenSigStartValueInteger" 0;
BA_DEF_DEF_  "UsedOnPgmDBC" "Yes";
BA_DEF_DEF_  "WakeupSignal" "No";
BA_DEF_DEF_  "GenSigInactiveValue" 0;
BA_DEF_DEF_  "GenSigSendType" "NoSigSendType";
BA_DEF_DEF_  "OvtpPushApplication" "FALSE";
BA_DEF_DEF_  "SCP_FreshnessValueLength" 64;
BA_DEF_DEF_  "SCP_FreshnessValueTxLength" 11;
BA_DEF_DEF_  "SCP_AuthInfoTxLength" 53;
BA_DEF_DEF_  "GenMsgRoutingTimeoutTime" 0;
BA_DEF_DEF_  "MessageGateway" "No";
BA_DEF_DEF_  "NmAsrMessage" "No";
BA_DEF_DEF_  "DiagState" "No";
BA_DEF_DEF_  "TpTxIndex" 0;
BA_DEF_DEF_  "DiagRequest" "No";
BA_DEF_DEF_  "DiagResponse" "No";
BA_DEF_DEF_  "GenMsgILSupport" "Yes";
BA_ "GenMsgSendType" BO_ 547 5;
BA_ "GenMsgCycleTime" BO_ 547 1000;
BA_ "GenMsgSendType" BO_ 732 5;
BA_ "GenMsgCycleTime" BO_ 732 1000;
BA_ "GenMsgSendType" BO_ 728 5;
BA_ "GenMsgCycleTime" BO_ 728 1000;
BA_ "GenMsgSendType" BO_ 489 1;
BA_ "GenMsgSendType" BO_ 757 5;
BA_ "GenMsgCycleTime" BO_ 757 1000;
BA_ "GenMsgSendType" BO_ 734 5;
BA_ "GenMsgCycleTime" BO_ 734 1000;
BA_ "GenMsgILSupport" BO_ 1420 0;
BA_ "NmAsrMessage" BO_ 1420 1;
BA_ "GenMsgSendType" BO_ 1420 0;
BA_ "GenMsgCycleTime" BO_ 1420 1000;
BA_ "NetworkInitialization" BO_ 1420 0;
BA_ "GenMsgSendType" BO_ 759 5;
BA_ "GenMsgCycleTime" BO_ 759 1000;
BA_ "GenMsgSendType" BO_ 144 1;
BA_ "GenMsgSendType" BO_ 851 5;
BA_ "GenMsgCycleTime" BO_ 851 1000;
BA_ "GenMsgSendType" BO_ 792 0;
BA_ "GenMsgCycleTime" BO_ 792 100;
BA_ "GenMsgSendType" BO_ 787 0;
BA_ "GenMsgCycleTime" BO_ 787 1000;
BA_ "TpTxIndex" BO_ 697 12;
BA_ "TpTxIndex" BO_ 700 15;
BA_ "TpTxIndex" BO_ 676 29;
BA_ "GenMsgSendType" BO_ 504 1;
BA_ "GenMsgSendType" BO_ 410 5;
BA_ "GenMsgCycleTime" BO_ 410 1000;
BA_ "GenMsgSendType" BO_ 1124 1;
BA_ "GenMsgSendType" BO_ 1123 1;
BA_ "GenMsgSendType" BO_ 1122 1;
BA_ "GenMsgSendType" BO_ 1131 5;
BA_ "GenMsgCycleTime" BO_ 1131 1000;
BA_ "GenMsgSendType" BO_ 1136 0;
BA_ "GenMsgCycleTime" BO_ 1136 100;
BA_ "FrameGatewayId" BO_ 1106 1106;
BA_ "FrameGatewayNetwork" BO_ 1106 "HS2_CAN";
BA_ "FrameRouting" BO_ 1106 "HS2_CAN,0x452;";
BA_ "FrameGatewayId" BO_ 1086 1086;
BA_ "FrameGatewayNetwork" BO_ 1086 "FD1_CAN";
BA_ "FrameRouting" BO_ 1086 "FD1_CAN,0x43E;HS1_CAN,0x43E";
BA_ "FrameGatewayId" BO_ 817 817;
BA_ "FrameGatewayNetwork" BO_ 817 "HS1_CAN";
BA_ "FrameRouting" BO_ 817 "HS1_CAN,0x331;";
BA_ "FrameGatewayId" BO_ 611 611;
BA_ "FrameGatewayNetwork" BO_ 611 "FD1_CAN";
BA_ "FrameRouting" BO_ 611 "FD1_CAN,0x263;HS1_CAN,0x263";
BA_ "GenMsgSendType" BO_ 264 5;
BA_ "GenMsgCycleTime" BO_ 264 1000;
BA_ "GenMsgSendType" BO_ 1114 5;
BA_ "GenMsgCycleTime" BO_ 1114 1000;
BA_ "GenMsgSendType" BO_ 968 5;
BA_ "GenMsgCycleTime" BO_ 968 1000;
BA_ "FrameGatewayId" BO_ 969 969;
BA_ "FrameGatewayNetwork" BO_ 969 "MS1_CAN";
BA_ "FrameRouting" BO_ 969 "MS1_CAN,0x3C9;";
BA_ "FrameRouting" BO_ 1006 "FD1_CAN,0x3EE;HS2_CAN,0x3EE";
BA_ "FrameGatewayId" BO_ 130 129;
BA_ "FrameGatewayNetwork" BO_ 130 "HS2_CAN";
BA_ "FrameRouting" BO_ 130 "HS2_CAN,0x81;";
BA_ "GenMsgSendType" BO_ 1244 0;
BA_ "GenMsgCycleTime" BO_ 1244 1000;
BA_ "GenMsgSendType" BO_ 1243 0;
BA_ "GenMsgCycleTime" BO_ 1243 1000;
BA_ "GenMsgSendType" BO_ 681 5;
BA_ "GenMsgCycleTime" BO_ 681 1000;
BA_ "GenMsgSendType" BO_ 744 5;
BA_ "GenMsgCycleTime" BO_ 744 1000;
BA_ "GenMsgSendType" BO_ 741 5;
BA_ "GenMsgCycleTime" BO_ 741 1000;
BA_ "FrameGatewayId" BO_ 954 954;
BA_ "FrameGatewayNetwork" BO_ 954 "HS1_CAN";
BA_ "FrameRouting" BO_ 954 "HS1_CAN,0x3BA;";
BA_ "MessageGateway" BO_ 125 1;
BA_ "FrameGatewayId" BO_ 125 125;
BA_ "FrameGatewayNetwork" BO_ 125 "FD1_CAN";
BA_ "FrameRouting" BO_ 125 "FD1_CAN,0x7D;";
BA_ "TpTxIndex" BO_ 2612224096 464617688;
BA_ "OvtpPushApplication" BO_ 2612224096 1;
BA_ "GenMsgSendType" BO_ 2612224096 1;
BA_ "GenMsgDelayTime" BO_ 2612224096 0;
BA_ "NetworkInitialization" BO_ 2612224096 0;
BA_ "TpTxIndex" BO_ 2611052760 463569112;
BA_ "GenMsgSendType" BO_ 2611052760 1;
BA_ "GenMsgDelayTime" BO_ 2611052760 0;
BA_ "NetworkInitialization" BO_ 2611052760 0;
BA_ "TpTxIndex" BO_ 2611175520 463569112;
BA_ "GenMsgSendType" BO_ 2611175520 1;
BA_ "GenMsgDelayTime" BO_ 2611175520 0;
BA_ "NetworkInitialization" BO_ 2611175520 0;
BA_ "TpTxIndex" BO_ 2610126944 462520536;
BA_ "GenMsgSendType" BO_ 2610126944 1;
BA_ "GenMsgDelayTime" BO_ 2610126944 0;
BA_ "NetworkInitialization" BO_ 2610126944 0;
BA_ "TpTxIndex" BO_ 2610004184 462520536;
BA_ "GenMsgSendType" BO_ 2610004184 1;
BA_ "GenMsgDelayTime" BO_ 2610004184 0;
BA_ "NetworkInitialization" BO_ 2610004184 0;
BA_ "GenMsgILSupport" BO_ 2005 0;
BA_ "DiagRequest" BO_ 2005 1;
BA_ "GenMsgSendType" BO_ 2005 1;
BA_ "GenMsgDelayTime" BO_ 2005 0;
BA_ "NetworkInitialization" BO_ 2005 0;
BA_ "GenMsgILSupport" BO_ 2013 0;
BA_ "DiagResponse" BO_ 2013 1;
BA_ "GenMsgSendType" BO_ 2013 1;
BA_ "GenMsgDelayTime" BO_ 2013 0;
BA_ "NetworkInitialization" BO_ 2013 0;
BA_ "GenMsgILSupport" BO_ 1519 0;
BA_ "NmAsrMessage" BO_ 1519 1;
BA_ "GenMsgSendType" BO_ 1519 0;
BA_ "GenMsgCycleTime" BO_ 1519 1000;
BA_ "NetworkInitialization" BO_ 1519 0;
BA_ "TpTxIndex" BO_ 2612002008 464518360;
BA_ "GenMsgSendType" BO_ 2612002008 1;
BA_ "GenMsgDelayTime" BO_ 2612002008 0;
BA_ "NetworkInitialization" BO_ 2612002008 0;
BA_ "TpTxIndex" BO_ 2610953432 463469784;
BA_ "GenMsgSendType" BO_ 2610953432 1;
BA_ "GenMsgDelayTime" BO_ 2610953432 0;
BA_ "NetworkInitialization" BO_ 2610953432 0;
BA_ "GenMsgSendType" BO_ 1082 5;
BA_ "GenMsgCycleTime" BO_ 1082 1000;
BA_ "TpTxIndex" BO_ 576 41;
BA_ "GenMsgSendType" BO_ 1115 5;
BA_ "GenMsgCycleTime" BO_ 1115 1000;
BA_ "GenMsgSendType" BO_ 996 5;
BA_ "GenMsgCycleTime" BO_ 996 1000;
BA_ "TpTxIndex" BO_ 588 45;
BA_ "GenMsgSendType" BO_ 811 5;
BA_ "GenMsgCycleTime" BO_ 811 1000;
BA_ "GenMsgSendType" BO_ 543 0;
BA_ "GenMsgCycleTime" BO_ 543 1000;
BA_ "GenMsgSendType" BO_ 563 5;
BA_ "GenMsgCycleTime" BO_ 563 1000;
BA_ "GenMsgSendType" BO_ 794 5;
BA_ "GenMsgCycleTime" BO_ 794 1000;
BA_ "TpTxIndex" BO_ 587 44;
BA_ "TpTxIndex" BO_ 579 44;
BA_ "TpTxIndex" BO_ 585 42;
BA_ "GenSigSendType" SG_ 547 Audio_Amp_St 3;
BA_ "U_P702_MY2021_Tx" SG_ 547 Audio_Amp_St 1;
BA_ "U_T6_MCA_MY2020_Tx" SG_ 547 Audio_Amp_St 1;
BA_ "U_U55X_MY2022_Tx" SG_ 547 Audio_Amp_St 1;
BA_ "GenSigSendType" SG_ 547 Chime_Alert_Chan2 3;
BA_ "U_T6_MCA_MY2020_Rx" SG_ 547 Chime_Alert_Chan2 1;
BA_ "U_CD542_MY2021_Rx" SG_ 547 Chime_Alert_Chan2 1;
BA_ "U_P702_MY2021_Rx" SG_ 547 Chime_Alert_Chan2 1;
BA_ "U_U55X_MY2022_Rx" SG_ 547 Chime_Alert_Chan2 1;
BA_ "U_P702_MY2021_Tx" SG_ 547 Chime_Alert_Chan2 1;
BA_ "U_T6_MCA_MY2020_Tx" SG_ 547 Chime_Alert_Chan2 1;
BA_ "U_CD542_MY2021_Tx" SG_ 547 Chime_Alert_Chan2 1;
BA_ "U_U55X_MY2022_Tx" SG_ 547 Chime_Alert_Chan2 1;
BA_ "GenSigSendType" SG_ 547 AHU_Chime2_Active 3;
BA_ "U_P702_MY2021_Rx" SG_ 547 AHU_Chime2_Active 1;
BA_ "U_T6_MCA_MY2020_Rx" SG_ 547 AHU_Chime2_Active 1;
BA_ "U_CD542_MY2021_Rx" SG_ 547 AHU_Chime2_Active 1;
BA_ "U_U55X_MY2022_Rx" SG_ 547 AHU_Chime2_Active 1;
BA_ "U_P702_MY2021_Tx" SG_ 547 AHU_Chime2_Active 1;
BA_ "U_T6_MCA_MY2020_Tx" SG_ 547 AHU_Chime2_Active 1;
BA_ "U_CD542_MY2021_Tx" SG_ 547 AHU_Chime2_Active 1;
BA_ "U_U55X_MY2022_Tx" SG_ 547 AHU_Chime2_Active 1;
BA_ "GenSigSendType" SG_ 547 AHU_Chime2_Not_Recognized 3;
BA_ "U_P702_MY2021_Rx" SG_ 547 AHU_Chime2_Not_Recognized 1;
BA_ "U_T6_MCA_MY2020_Rx" SG_ 547 AHU_Chime2_Not_Recognized 1;
BA_ "U_CD542_MY2021_Rx" SG_ 547 AHU_Chime2_Not_Recognized 1;
BA_ "U_U55X_MY2022_Rx" SG_ 547 AHU_Chime2_Not_Recognized 1;
BA_ "U_P702_MY2021_Tx" SG_ 547 AHU_Chime2_Not_Recognized 1;
BA_ "U_T6_MCA_MY2020_Tx" SG_ 547 AHU_Chime2_Not_Recognized 1;
BA_ "U_U55X_MY2022_Tx" SG_ 547 AHU_Chime2_Not_Recognized 1;
BA_ "GenSigSendType" SG_ 547 Chime_Alert_Chan 3;
BA_ "U_T6_MCA_MY2020_Rx" SG_ 547 Chime_Alert_Chan 1;
BA_ "U_CD542_MY2021_Rx" SG_ 547 Chime_Alert_Chan 1;
BA_ "U_P702_MY2021_Rx" SG_ 547 Chime_Alert_Chan 1;
BA_ "U_U55X_MY2022_Rx" SG_ 547 Chime_Alert_Chan 1;
BA_ "U_P702_MY2021_Tx" SG_ 547 Chime_Alert_Chan 1;
BA_ "U_T6_MCA_MY2020_Tx" SG_ 547 Chime_Alert_Chan 1;
BA_ "U_CD542_MY2021_Tx" SG_ 547 Chime_Alert_Chan 1;
BA_ "U_U55X_MY2022_Tx" SG_ 547 Chime_Alert_Chan 1;
BA_ "GenSigSendType" SG_ 547 AHU_Alert_Channel1 3;
BA_ "U_P702_MY2021_Rx" SG_ 547 AHU_Alert_Channel1 1;
BA_ "U_T6_MCA_MY2020_Rx" SG_ 547 AHU_Alert_Channel1 1;
BA_ "U_CD542_MY2021_Rx" SG_ 547 AHU_Alert_Channel1 1;
BA_ "U_U55X_MY2022_Rx" SG_ 547 AHU_Alert_Channel1 1;
BA_ "U_P702_MY2021_Tx" SG_ 547 AHU_Alert_Channel1 1;
BA_ "U_T6_MCA_MY2020_Tx" SG_ 547 AHU_Alert_Channel1 1;
BA_ "U_CD542_MY2021_Tx" SG_ 547 AHU_Alert_Channel1 1;
BA_ "U_U55X_MY2022_Tx" SG_ 547 AHU_Alert_Channel1 1;
BA_ "GenSigSendType" SG_ 547 AHU_Chime_Supported 3;
BA_ "U_P702_MY2021_Rx" SG_ 547 AHU_Chime_Supported 1;
BA_ "U_T6_MCA_MY2020_Rx" SG_ 547 AHU_Chime_Supported 1;
BA_ "U_CD542_MY2021_Rx" SG_ 547 AHU_Chime_Supported 1;
BA_ "U_U55X_MY2022_Rx" SG_ 547 AHU_Chime_Supported 1;
BA_ "U_P702_MY2021_Tx" SG_ 547 AHU_Chime_Supported 1;
BA_ "U_T6_MCA_MY2020_Tx" SG_ 547 AHU_Chime_Supported 1;
BA_ "U_CD542_MY2021_Tx" SG_ 547 AHU_Chime_Supported 1;
BA_ "U_U55X_MY2022_Tx" SG_ 547 AHU_Chime_Supported 1;
BA_ "GenSigSendType" SG_ 547 AHU_Chime_Active 3;
BA_ "U_P702_MY2021_Rx" SG_ 547 AHU_Chime_Active 1;
BA_ "U_T6_MCA_MY2020_Rx" SG_ 547 AHU_Chime_Active 1;
BA_ "U_CD542_MY2021_Rx" SG_ 547 AHU_Chime_Active 1;
BA_ "U_U55X_MY2022_Rx" SG_ 547 AHU_Chime_Active 1;
BA_ "U_P702_MY2021_Tx" SG_ 547 AHU_Chime_Active 1;
BA_ "U_T6_MCA_MY2020_Tx" SG_ 547 AHU_Chime_Active 1;
BA_ "U_CD542_MY2021_Tx" SG_ 547 AHU_Chime_Active 1;
BA_ "U_U55X_MY2022_Tx" SG_ 547 AHU_Chime_Active 1;
BA_ "GenSigSendType" SG_ 547 AHU_Chime_Not_Recognized 3;
BA_ "U_P702_MY2021_Rx" SG_ 547 AHU_Chime_Not_Recognized 1;
BA_ "U_T6_MCA_MY2020_Rx" SG_ 547 AHU_Chime_Not_Recognized 1;
BA_ "U_CD542_MY2021_Rx" SG_ 547 AHU_Chime_Not_Recognized 1;
BA_ "U_U55X_MY2022_Rx" SG_ 547 AHU_Chime_Not_Recognized 1;
BA_ "U_P702_MY2021_Tx" SG_ 547 AHU_Chime_Not_Recognized 1;
BA_ "U_T6_MCA_MY2020_Tx" SG_ 547 AHU_Chime_Not_Recognized 1;
BA_ "U_U55X_MY2022_Tx" SG_ 547 AHU_Chime_Not_Recognized 1;
BA_ "GenSigSendType" SG_ 547 ChimeId_No_Stat 3;
BA_ "U_T6_MCA_MY2020_Rx" SG_ 547 ChimeId_No_Stat 1;
BA_ "U_CD542_MY2021_Rx" SG_ 547 ChimeId_No_Stat 1;
BA_ "U_P702_MY2021_Tx" SG_ 547 ChimeId_No_Stat 1;
BA_ "U_T6_MCA_MY2020_Tx" SG_ 547 ChimeId_No_Stat 1;
BA_ "U_U55X_MY2022_Tx" SG_ 547 ChimeId_No_Stat 1;
BA_ "GenSigSendType" SG_ 547 Chime2Id_No_Stat 3;
BA_ "U_T6_MCA_MY2020_Rx" SG_ 547 Chime2Id_No_Stat 1;
BA_ "U_CD542_MY2021_Rx" SG_ 547 Chime2Id_No_Stat 1;
BA_ "U_P702_MY2021_Tx" SG_ 547 Chime2Id_No_Stat 1;
BA_ "U_T6_MCA_MY2020_Tx" SG_ 547 Chime2Id_No_Stat 1;
BA_ "U_U55X_MY2022_Tx" SG_ 547 Chime2Id_No_Stat 1;
BA_ "GenSigSendType" SG_ 547 AHU_AdjChimVolSupp2_St 3;
BA_ "U_T6_MCA_MY2020_Rx" SG_ 547 AHU_AdjChimVolSupp2_St 1;
BA_ "U_CD542_MY2021_Rx" SG_ 547 AHU_AdjChimVolSupp2_St 1;
BA_ "U_U55X_MY2022_Rx" SG_ 547 AHU_AdjChimVolSupp2_St 1;
BA_ "U_P702_MY2021_Tx" SG_ 547 AHU_AdjChimVolSupp2_St 1;
BA_ "U_T6_MCA_MY2020_Tx" SG_ 547 AHU_AdjChimVolSupp2_St 1;
BA_ "U_U55X_MY2022_Tx" SG_ 547 AHU_AdjChimVolSupp2_St 1;
BA_ "GenSigSendType" SG_ 547 AHU_AdjChimeVolSupp_St 3;
BA_ "U_T6_MCA_MY2020_Rx" SG_ 547 AHU_AdjChimeVolSupp_St 1;
BA_ "U_CD542_MY2021_Rx" SG_ 547 AHU_AdjChimeVolSupp_St 1;
BA_ "U_U55X_MY2022_Rx" SG_ 547 AHU_AdjChimeVolSupp_St 1;
BA_ "U_P702_MY2021_Tx" SG_ 547 AHU_AdjChimeVolSupp_St 1;
BA_ "U_T6_MCA_MY2020_Tx" SG_ 547 AHU_AdjChimeVolSupp_St 1;
BA_ "U_U55X_MY2022_Tx" SG_ 547 AHU_AdjChimeVolSupp_St 1;
BA_ "GenSigSendType" SG_ 547 AhuDgtlChime_D_Stat 3;
BA_ "U_T6_MCA_MY2020_Rx" SG_ 547 AhuDgtlChime_D_Stat 1;
BA_ "U_U55X_MY2022_Rx" SG_ 547 AhuDgtlChime_D_Stat 1;
BA_ "U_P702_MY2021_Tx" SG_ 547 AhuDgtlChime_D_Stat 1;
BA_ "U_T6_MCA_MY2020_Tx" SG_ 547 AhuDgtlChime_D_Stat 1;
BA_ "U_U55X_MY2022_Tx" SG_ 547 AhuDgtlChime_D_Stat 1;
BA_ "U_T6_MCA_MY2020_Rx" SG_ 732 ACU_CurrItemsInFMSL_St 1;
BA_ "U_CD542_MY2021_Rx" SG_ 732 ACU_CurrItemsInFMSL_St 1;
BA_ "U_U55X_MY2022_Rx" SG_ 732 ACU_CurrItemsInFMSL_St 1;
BA_ "U_P702_MY2021_Tx" SG_ 732 ACU_CurrItemsInFMSL_St 1;
BA_ "U_T6_MCA_MY2020_Tx" SG_ 732 ACU_CurrItemsInFMSL_St 1;
BA_ "U_CD542_MY2021_Tx" SG_ 732 ACU_CurrItemsInFMSL_St 1;
BA_ "U_U55X_MY2022_Tx" SG_ 732 ACU_CurrItemsInFMSL_St 1;
BA_ "GenSigSendType" SG_ 732 ACU_FunctionStatus_St 3;
BA_ "U_T6_MCA_MY2020_Rx" SG_ 732 ACU_FunctionStatus_St 1;
BA_ "U_CD542_MY2021_Rx" SG_ 732 ACU_FunctionStatus_St 1;
BA_ "U_U55X_MY2022_Rx" SG_ 732 ACU_FunctionStatus_St 1;
BA_ "U_P702_MY2021_Tx" SG_ 732 ACU_FunctionStatus_St 1;
BA_ "U_T6_MCA_MY2020_Tx" SG_ 732 ACU_FunctionStatus_St 1;
BA_ "U_CD542_MY2021_Tx" SG_ 732 ACU_FunctionStatus_St 1;
BA_ "U_U55X_MY2022_Tx" SG_ 732 ACU_FunctionStatus_St 1;
BA_ "U_P702_MY2021_Rx" SG_ 732 ACU_CurrFMSLPreset_St 1;
BA_ "U_T6_MCA_MY2020_Rx" SG_ 732 ACU_CurrFMSLPreset_St 1;
BA_ "U_CD542_MY2021_Rx" SG_ 732 ACU_CurrFMSLPreset_St 1;
BA_ "U_U55X_MY2022_Rx" SG_ 732 ACU_CurrFMSLPreset_St 1;
BA_ "U_P702_MY2021_Tx" SG_ 732 ACU_CurrFMSLPreset_St 1;
BA_ "U_T6_MCA_MY2020_Tx" SG_ 732 ACU_CurrFMSLPreset_St 1;
BA_ "U_CD542_MY2021_Tx" SG_ 732 ACU_CurrFMSLPreset_St 1;
BA_ "U_U55X_MY2022_Tx" SG_ 732 ACU_CurrFMSLPreset_St 1;
BA_ "U_T6_MCA_MY2020_Rx" SG_ 732 ACU_CurrPreset2_St 1;
BA_ "U_CD542_MY2021_Rx" SG_ 732 ACU_CurrPreset2_St 1;
BA_ "U_U55X_MY2022_Rx" SG_ 732 ACU_CurrPreset2_St 1;
BA_ "U_P702_MY2021_Rx" SG_ 732 ACU_CurrPreset2_St 1;
BA_ "U_P702_MY2021_Tx" SG_ 732 ACU_CurrPreset2_St 1;
BA_ "U_T6_MCA_MY2020_Tx" SG_ 732 ACU_CurrPreset2_St 1;
BA_ "U_CD542_MY2021_Tx" SG_ 732 ACU_CurrPreset2_St 1;
BA_ "U_U55X_MY2022_Tx" SG_ 732 ACU_CurrPreset2_St 1;
BA_ "GenSigSendType" SG_ 732 ACU_StorePreset_St 3;
BA_ "U_T6_MCA_MY2020_Rx" SG_ 732 ACU_StorePreset_St 1;
BA_ "U_CD542_MY2021_Rx" SG_ 732 ACU_StorePreset_St 1;
BA_ "U_U55X_MY2022_Rx" SG_ 732 ACU_StorePreset_St 1;
BA_ "U_P702_MY2021_Rx" SG_ 732 ACU_StorePreset_St 1;
BA_ "U_P702_MY2021_Tx" SG_ 732 ACU_StorePreset_St 1;
BA_ "U_T6_MCA_MY2020_Tx" SG_ 732 ACU_StorePreset_St 1;
BA_ "U_CD542_MY2021_Tx" SG_ 732 ACU_StorePreset_St 1;
BA_ "U_U55X_MY2022_Tx" SG_ 732 ACU_StorePreset_St 1;
BA_ "GenSigSendType" SG_ 732 ACU_VoiceCommand_St 3;
BA_ "U_P702_MY2021_Tx" SG_ 732 ACU_VoiceCommand_St 1;
BA_ "U_T6_MCA_MY2020_Tx" SG_ 732 ACU_VoiceCommand_St 1;
BA_ "U_U55X_MY2022_Tx" SG_ 732 ACU_VoiceCommand_St 1;
BA_ "U_P702_MY2021_Rx" SG_ 732 ACU_CurrMixPreset_St 1;
BA_ "U_T6_MCA_MY2020_Rx" SG_ 732 ACU_CurrMixPreset_St 1;
BA_ "U_CD542_MY2021_Rx" SG_ 732 ACU_CurrMixPreset_St 1;
BA_ "U_U55X_MY2022_Rx" SG_ 732 ACU_CurrMixPreset_St 1;
BA_ "U_P702_MY2021_Tx" SG_ 732 ACU_CurrMixPreset_St 1;
BA_ "U_T6_MCA_MY2020_Tx" SG_ 732 ACU_CurrMixPreset_St 1;
BA_ "U_CD542_MY2021_Tx" SG_ 732 ACU_CurrMixPreset_St 1;
BA_ "U_U55X_MY2022_Tx" SG_ 732 ACU_CurrMixPreset_St 1;
BA_ "GenSigSendType" SG_ 728 PrplSnd_D_Stat 3;
BA_ "U_T6_MCA_MY2020_Rx" SG_ 728 PrplSnd_D_Stat 1;
BA_ "U_CD542_MY2021_Rx" SG_ 728 PrplSnd_D_Stat 1;
BA_ "U_U55X_MY2022_Rx" SG_ 728 PrplSnd_D_Stat 1;
BA_ "U_T6_MCA_MY2020_Tx" SG_ 728 PrplSnd_D_Stat 1;
BA_ "U_U55X_MY2022_Tx" SG_ 728 PrplSnd_D_Stat 1;
BA_ "GenSigSendType" SG_ 728 ACU_AuxVolume_Up 3;
BA_ "U_T6_MCA_MY2020_Rx" SG_ 728 ACU_AuxVolume_Up 1;
BA_ "U_CD542_MY2021_Rx" SG_ 728 ACU_AuxVolume_Up 1;
BA_ "U_U55X_MY2022_Rx" SG_ 728 ACU_AuxVolume_Up 1;
BA_ "U_P702_MY2021_Tx" SG_ 728 ACU_AuxVolume_Up 1;
BA_ "U_T6_MCA_MY2020_Tx" SG_ 728 ACU_AuxVolume_Up 1;
BA_ "U_U55X_MY2022_Tx" SG_ 728 ACU_AuxVolume_Up 1;
BA_ "U_T6_MCA_MY2020_Rx" SG_ 728 ACU_AuxVolume_St 1;
BA_ "U_CD542_MY2021_Rx" SG_ 728 ACU_AuxVolume_St 1;
BA_ "U_U55X_MY2022_Rx" SG_ 728 ACU_AuxVolume_St 1;
BA_ "U_P702_MY2021_Tx" SG_ 728 ACU_AuxVolume_St 1;
BA_ "U_T6_MCA_MY2020_Tx" SG_ 728 ACU_AuxVolume_St 1;
BA_ "U_U55X_MY2022_Tx" SG_ 728 ACU_AuxVolume_St 1;
BA_ "U_P702_MY2021_Rx" SG_ 728 ACU_Mid_St 1;
BA_ "U_T6_MCA_MY2020_Rx" SG_ 728 ACU_Mid_St 1;
BA_ "U_CD542_MY2021_Rx" SG_ 728 ACU_Mid_St 1;
BA_ "U_U55X_MY2022_Rx" SG_ 728 ACU_Mid_St 1;
BA_ "U_P702_MY2021_Tx" SG_ 728 ACU_Mid_St 1;
BA_ "U_T6_MCA_MY2020_Tx" SG_ 728 ACU_Mid_St 1;
BA_ "U_CD542_MY2021_Tx" SG_ 728 ACU_Mid_St 1;
BA_ "U_U55X_MY2022_Tx" SG_ 728 ACU_Mid_St 1;
BA_ "GenSigSendType" SG_ 728 ACU_RadioSeekMode_St 3;
BA_ "U_T6_MCA_MY2020_Rx" SG_ 728 ACU_RadioSeekMode_St 1;
BA_ "U_CD542_MY2021_Rx" SG_ 728 ACU_RadioSeekMode_St 1;
BA_ "U_U55X_MY2022_Rx" SG_ 728 ACU_RadioSeekMode_St 1;
BA_ "U_P702_MY2021_Rx" SG_ 728 ACU_RadioSeekMode_St 1;
BA_ "U_P702_MY2021_Tx" SG_ 728 ACU_RadioSeekMode_St 1;
BA_ "U_T6_MCA_MY2020_Tx" SG_ 728 ACU_RadioSeekMode_St 1;
BA_ "U_U55X_MY2022_Tx" SG_ 728 ACU_RadioSeekMode_St 1;
BA_ "U_T6_MCA_MY2020_Rx" SG_ 728 ACU_Volume_St 1;
BA_ "U_CD542_MY2021_Rx" SG_ 728 ACU_Volume_St 1;
BA_ "U_U55X_MY2022_Rx" SG_ 728 ACU_Volume_St 1;
BA_ "U_P702_MY2021_Rx" SG_ 728 ACU_Volume_St 1;
BA_ "ECGUsedRxSignal" SG_ 728 ACU_Volume_St 1;
BA_ "U_P702_MY2021_Tx" SG_ 728 ACU_Volume_St 1;
BA_ "U_T6_MCA_MY2020_Tx" SG_ 728 ACU_Volume_St 1;
BA_ "U_CD542_MY2021_Tx" SG_ 728 ACU_Volume_St 1;
BA_ "U_U55X_MY2022_Tx" SG_ 728 ACU_Volume_St 1;
BA_ "GenSigSendType" SG_ 728 ACU_Volume_Up 3;
BA_ "U_T6_MCA_MY2020_Rx" SG_ 728 ACU_Volume_Up 1;
BA_ "U_CD542_MY2021_Rx" SG_ 728 ACU_Volume_Up 1;
BA_ "U_U55X_MY2022_Rx" SG_ 728 ACU_Volume_Up 1;
BA_ "U_P702_MY2021_Rx" SG_ 728 ACU_Volume_Up 1;
BA_ "U_P702_MY2021_Tx" SG_ 728 ACU_Volume_Up 1;
BA_ "U_T6_MCA_MY2020_Tx" SG_ 728 ACU_Volume_Up 1;
BA_ "U_CD542_MY2021_Tx" SG_ 728 ACU_Volume_Up 1;
BA_ "U_U55X_MY2022_Tx" SG_ 728 ACU_Volume_Up 1;
BA_ "U_T6_MCA_MY2020_Rx" SG_ 728 ACU_CurrentStatFlags_St 1;
BA_ "U_CD542_MY2021_Rx" SG_ 728 ACU_CurrentStatFlags_St 1;
BA_ "U_U55X_MY2022_Rx" SG_ 728 ACU_CurrentStatFlags_St 1;
BA_ "U_P702_MY2021_Rx" SG_ 728 ACU_CurrentStatFlags_St 1;
BA_ "U_P702_MY2021_Tx" SG_ 728 ACU_CurrentStatFlags_St 1;
BA_ "U_T6_MCA_MY2020_Tx" SG_ 728 ACU_CurrentStatFlags_St 1;
BA_ "U_CD542_MY2021_Tx" SG_ 728 ACU_CurrentStatFlags_St 1;
BA_ "U_U55X_MY2022_Tx" SG_ 728 ACU_CurrentStatFlags_St 1;
BA_ "GenSigSendType" SG_ 489 ACU_CurrentPSName_St 3;
BA_ "U_T6_MCA_MY2020_Rx" SG_ 489 ACU_CurrentPSName_St 1;
BA_ "U_CD542_MY2021_Rx" SG_ 489 ACU_CurrentPSName_St 1;
BA_ "U_U55X_MY2022_Rx" SG_ 489 ACU_CurrentPSName_St 1;
BA_ "U_P702_MY2021_Rx" SG_ 489 ACU_CurrentPSName_St 1;
BA_ "U_P702_MY2021_Tx" SG_ 489 ACU_CurrentPSName_St 1;
BA_ "U_T6_MCA_MY2020_Tx" SG_ 489 ACU_CurrentPSName_St 1;
BA_ "U_CD542_MY2021_Tx" SG_ 489 ACU_CurrentPSName_St 1;
BA_ "U_U55X_MY2022_Tx" SG_ 489 ACU_CurrentPSName_St 1;
BA_ "GenSigSendType" SG_ 757 SdarsAudioRtng_D_Stat 3;
BA_ "U_U55X_MY2022_Rx" SG_ 757 SdarsAudioRtng_D_Stat 1;
BA_ "U_T6_MCA_MY2020_Tx" SG_ 757 SdarsAudioRtng_D_Stat 1;
BA_ "U_U55X_MY2022_Tx" SG_ 757 SdarsAudioRtng_D_Stat 1;
BA_ "GenSigSendType" SG_ 757 SpkrStdRight_D_Stat 3;
BA_ "U_T6_MCA_MY2020_Rx" SG_ 757 SpkrStdRight_D_Stat 1;
BA_ "U_P702_MY2021_Tx" SG_ 757 SpkrStdRight_D_Stat 1;
BA_ "U_T6_MCA_MY2020_Tx" SG_ 757 SpkrStdRight_D_Stat 1;
BA_ "U_CD542_MY2021_Tx" SG_ 757 SpkrStdRight_D_Stat 1;
BA_ "U_U55X_MY2022_Tx" SG_ 757 SpkrStdRight_D_Stat 1;
BA_ "GenSigSendType" SG_ 757 SpkrStdLeft_D_Stat 3;
BA_ "U_T6_MCA_MY2020_Rx" SG_ 757 SpkrStdLeft_D_Stat 1;
BA_ "U_P702_MY2021_Tx" SG_ 757 SpkrStdLeft_D_Stat 1;
BA_ "U_T6_MCA_MY2020_Tx" SG_ 757 SpkrStdLeft_D_Stat 1;
BA_ "U_CD542_MY2021_Tx" SG_ 757 SpkrStdLeft_D_Stat 1;
BA_ "U_U55X_MY2022_Tx" SG_ 757 SpkrStdLeft_D_Stat 1;
BA_ "GenSigSendType" SG_ 757 SpkrStdCntr_D_Stat 3;
BA_ "U_T6_MCA_MY2020_Rx" SG_ 757 SpkrStdCntr_D_Stat 1;
BA_ "U_P702_MY2021_Tx" SG_ 757 SpkrStdCntr_D_Stat 1;
BA_ "U_T6_MCA_MY2020_Tx" SG_ 757 SpkrStdCntr_D_Stat 1;
BA_ "U_CD542_MY2021_Tx" SG_ 757 SpkrStdCntr_D_Stat 1;
BA_ "U_U55X_MY2022_Tx" SG_ 757 SpkrStdCntr_D_Stat 1;
BA_ "GenSigSendType" SG_ 757 SDARS_ChipControl_St 3;
BA_ "U_P702_MY2021_Rx" SG_ 757 SDARS_ChipControl_St 1;
BA_ "U_T6_MCA_MY2020_Rx" SG_ 757 SDARS_ChipControl_St 1;
BA_ "U_CD542_MY2021_Rx" SG_ 757 SDARS_ChipControl_St 1;
BA_ "U_U55X_MY2022_Rx" SG_ 757 SDARS_ChipControl_St 1;
BA_ "U_P702_MY2021_Tx" SG_ 757 SDARS_ChipControl_St 1;
BA_ "U_T6_MCA_MY2020_Tx" SG_ 757 SDARS_ChipControl_St 1;
BA_ "U_CD542_MY2021_Tx" SG_ 757 SDARS_ChipControl_St 1;
BA_ "U_U55X_MY2022_Tx" SG_ 757 SDARS_ChipControl_St 1;
BA_ "GenSigSendType" SG_ 757 ACU_AutoStoreResult_St 3;
BA_ "U_T6_MCA_MY2020_Rx" SG_ 757 ACU_AutoStoreResult_St 1;
BA_ "U_CD542_MY2021_Rx" SG_ 757 ACU_AutoStoreResult_St 1;
BA_ "U_P702_MY2021_Rx" SG_ 757 ACU_AutoStoreResult_St 1;
BA_ "U_U55X_MY2022_Rx" SG_ 757 ACU_AutoStoreResult_St 1;
BA_ "U_P702_MY2021_Tx" SG_ 757 ACU_AutoStoreResult_St 1;
BA_ "U_T6_MCA_MY2020_Tx" SG_ 757 ACU_AutoStoreResult_St 1;
BA_ "U_CD542_MY2021_Tx" SG_ 757 ACU_AutoStoreResult_St 1;
BA_ "U_U55X_MY2022_Tx" SG_ 757 ACU_AutoStoreResult_St 1;
BA_ "GenSigSendType" SG_ 757 ACU_DirectTune_St 3;
BA_ "U_T6_MCA_MY2020_Rx" SG_ 757 ACU_DirectTune_St 1;
BA_ "U_CD542_MY2021_Rx" SG_ 757 ACU_DirectTune_St 1;
BA_ "U_P702_MY2021_Rx" SG_ 757 ACU_DirectTune_St 1;
BA_ "U_U55X_MY2022_Rx" SG_ 757 ACU_DirectTune_St 1;
BA_ "U_P702_MY2021_Tx" SG_ 757 ACU_DirectTune_St 1;
BA_ "U_T6_MCA_MY2020_Tx" SG_ 757 ACU_DirectTune_St 1;
BA_ "U_CD542_MY2021_Tx" SG_ 757 ACU_DirectTune_St 1;
BA_ "U_U55X_MY2022_Tx" SG_ 757 ACU_DirectTune_St 1;
BA_ "GenSigSendType" SG_ 757 ACU_RadioSeekMode2_St 3;
BA_ "U_T6_MCA_MY2020_Rx" SG_ 757 ACU_RadioSeekMode2_St 1;
BA_ "U_CD542_MY2021_Rx" SG_ 757 ACU_RadioSeekMode2_St 1;
BA_ "U_CX727_MY2021_Rx" SG_ 757 ACU_RadioSeekMode2_St 1;
BA_ "U_P702_MY2021_Rx" SG_ 757 ACU_RadioSeekMode2_St 1;
BA_ "U_U55X_MY2022_Rx" SG_ 757 ACU_RadioSeekMode2_St 1;
BA_ "U_P702_MY2021_Tx" SG_ 757 ACU_RadioSeekMode2_St 1;
BA_ "U_T6_MCA_MY2020_Tx" SG_ 757 ACU_RadioSeekMode2_St 1;
BA_ "U_CD542_MY2021_Tx" SG_ 757 ACU_RadioSeekMode2_St 1;
BA_ "U_U55X_MY2022_Tx" SG_ 757 ACU_RadioSeekMode2_St 1;
BA_ "GenSigSendType" SG_ 757 ACU_CurrTUBand_St 3;
BA_ "U_T6_MCA_MY2020_Rx" SG_ 757 ACU_CurrTUBand_St 1;
BA_ "U_CD542_MY2021_Rx" SG_ 757 ACU_CurrTUBand_St 1;
BA_ "U_U55X_MY2022_Rx" SG_ 757 ACU_CurrTUBand_St 1;
BA_ "U_CX727_MY2021_Rx" SG_ 757 ACU_CurrTUBand_St 1;
BA_ "U_P702_MY2021_Rx" SG_ 757 ACU_CurrTUBand_St 1;
BA_ "U_P702_MY2021_Tx" SG_ 757 ACU_CurrTUBand_St 1;
BA_ "U_T6_MCA_MY2020_Tx" SG_ 757 ACU_CurrTUBand_St 1;
BA_ "U_CD542_MY2021_Tx" SG_ 757 ACU_CurrTUBand_St 1;
BA_ "U_U55X_MY2022_Tx" SG_ 757 ACU_CurrTUBand_St 1;
BA_ "GenSigSendType" SG_ 734 ACU_ActServiceLink_St 3;
BA_ "U_P702_MY2021_Rx" SG_ 734 ACU_ActServiceLink_St 1;
BA_ "U_T6_MCA_MY2020_Rx" SG_ 734 ACU_ActServiceLink_St 1;
BA_ "U_CD542_MY2021_Rx" SG_ 734 ACU_ActServiceLink_St 1;
BA_ "U_U55X_MY2022_Rx" SG_ 734 ACU_ActServiceLink_St 1;
BA_ "U_P702_MY2021_Tx" SG_ 734 ACU_ActServiceLink_St 1;
BA_ "U_T6_MCA_MY2020_Tx" SG_ 734 ACU_ActServiceLink_St 1;
BA_ "U_CD542_MY2021_Tx" SG_ 734 ACU_ActServiceLink_St 1;
BA_ "U_U55X_MY2022_Tx" SG_ 734 ACU_ActServiceLink_St 1;
BA_ "GenSigSendType" SG_ 734 ACU_CurrTUDRService2_St 3;
BA_ "U_T6_MCA_MY2020_Rx" SG_ 734 ACU_CurrTUDRService2_St 1;
BA_ "U_CD542_MY2021_Rx" SG_ 734 ACU_CurrTUDRService2_St 1;
BA_ "U_P702_MY2021_Rx" SG_ 734 ACU_CurrTUDRService2_St 1;
BA_ "U_U55X_MY2022_Rx" SG_ 734 ACU_CurrTUDRService2_St 1;
BA_ "U_P702_MY2021_Tx" SG_ 734 ACU_CurrTUDRService2_St 1;
BA_ "U_T6_MCA_MY2020_Tx" SG_ 734 ACU_CurrTUDRService2_St 1;
BA_ "U_CD542_MY2021_Tx" SG_ 734 ACU_CurrTUDRService2_St 1;
BA_ "U_U55X_MY2022_Tx" SG_ 734 ACU_CurrTUDRService2_St 1;
BA_ "GenSigSendType" SG_ 734 ACU_ComTUSIDValid_St 3;
BA_ "U_P702_MY2021_Rx" SG_ 734 ACU_ComTUSIDValid_St 1;
BA_ "U_T6_MCA_MY2020_Rx" SG_ 734 ACU_ComTUSIDValid_St 1;
BA_ "U_CD542_MY2021_Rx" SG_ 734 ACU_ComTUSIDValid_St 1;
BA_ "U_U55X_MY2022_Rx" SG_ 734 ACU_ComTUSIDValid_St 1;
BA_ "U_P702_MY2021_Tx" SG_ 734 ACU_ComTUSIDValid_St 1;
BA_ "U_T6_MCA_MY2020_Tx" SG_ 734 ACU_ComTUSIDValid_St 1;
BA_ "U_CD542_MY2021_Tx" SG_ 734 ACU_ComTUSIDValid_St 1;
BA_ "U_U55X_MY2022_Tx" SG_ 734 ACU_ComTUSIDValid_St 1;
BA_ "GenSigSendType" SG_ 734 ACU_CurrTUDABBlock_St 3;
BA_ "U_T6_MCA_MY2020_Rx" SG_ 734 ACU_CurrTUDABBlock_St 1;
BA_ "U_CD542_MY2021_Rx" SG_ 734 ACU_CurrTUDABBlock_St 1;
BA_ "U_U55X_MY2022_Rx" SG_ 734 ACU_CurrTUDABBlock_St 1;
BA_ "U_P702_MY2021_Rx" SG_ 734 ACU_CurrTUDABBlock_St 1;
BA_ "U_P702_MY2021_Tx" SG_ 734 ACU_CurrTUDABBlock_St 1;
BA_ "U_T6_MCA_MY2020_Tx" SG_ 734 ACU_CurrTUDABBlock_St 1;
BA_ "U_CD542_MY2021_Tx" SG_ 734 ACU_CurrTUDABBlock_St 1;
BA_ "U_U55X_MY2022_Tx" SG_ 734 ACU_CurrTUDABBlock_St 1;
BA_ "GenSigSendType" SG_ 734 ACU_CurrTUDRService_St 3;
BA_ "U_P702_MY2021_Rx" SG_ 734 ACU_CurrTUDRService_St 1;
BA_ "U_T6_MCA_MY2020_Rx" SG_ 734 ACU_CurrTUDRService_St 1;
BA_ "U_CD542_MY2021_Rx" SG_ 734 ACU_CurrTUDRService_St 1;
BA_ "U_U55X_MY2022_Rx" SG_ 734 ACU_CurrTUDRService_St 1;
BA_ "U_P702_MY2021_Tx" SG_ 734 ACU_CurrTUDRService_St 1;
BA_ "U_T6_MCA_MY2020_Tx" SG_ 734 ACU_CurrTUDRService_St 1;
BA_ "U_CD542_MY2021_Tx" SG_ 734 ACU_CurrTUDRService_St 1;
BA_ "U_U55X_MY2022_Tx" SG_ 734 ACU_CurrTUDRService_St 1;
BA_ "GenSigSendType" SG_ 734 ACU_CurrTURadioBand_St 3;
BA_ "U_P702_MY2021_Tx" SG_ 734 ACU_CurrTURadioBand_St 1;
BA_ "U_T6_MCA_MY2020_Tx" SG_ 734 ACU_CurrTURadioBand_St 1;
BA_ "U_U55X_MY2022_Tx" SG_ 734 ACU_CurrTURadioBand_St 1;
BA_ "U_P702_MY2021_Rx" SG_ 734 ACU_CurrTUSCIDI_St 1;
BA_ "U_T6_MCA_MY2020_Rx" SG_ 734 ACU_CurrTUSCIDI_St 1;
BA_ "U_CD542_MY2021_Rx" SG_ 734 ACU_CurrTUSCIDI_St 1;
BA_ "U_U55X_MY2022_Rx" SG_ 734 ACU_CurrTUSCIDI_St 1;
BA_ "U_P702_MY2021_Tx" SG_ 734 ACU_CurrTUSCIDI_St 1;
BA_ "U_T6_MCA_MY2020_Tx" SG_ 734 ACU_CurrTUSCIDI_St 1;
BA_ "U_CD542_MY2021_Tx" SG_ 734 ACU_CurrTUSCIDI_St 1;
BA_ "U_U55X_MY2022_Tx" SG_ 734 ACU_CurrTUSCIDI_St 1;
BA_ "GenSigSendType" SG_ 734 ACU_CurrTUServiceLink_St 3;
BA_ "U_P702_MY2021_Rx" SG_ 734 ACU_CurrTUServiceLink_St 1;
BA_ "U_T6_MCA_MY2020_Rx" SG_ 734 ACU_CurrTUServiceLink_St 1;
BA_ "U_CD542_MY2021_Rx" SG_ 734 ACU_CurrTUServiceLink_St 1;
BA_ "U_U55X_MY2022_Rx" SG_ 734 ACU_CurrTUServiceLink_St 1;
BA_ "U_P702_MY2021_Tx" SG_ 734 ACU_CurrTUServiceLink_St 1;
BA_ "U_T6_MCA_MY2020_Tx" SG_ 734 ACU_CurrTUServiceLink_St 1;
BA_ "U_CD542_MY2021_Tx" SG_ 734 ACU_CurrTUServiceLink_St 1;
BA_ "U_U55X_MY2022_Tx" SG_ 734 ACU_CurrTUServiceLink_St 1;
BA_ "U_P702_MY2021_Rx" SG_ 734 ACU_CurrTUSID_St 1;
BA_ "U_T6_MCA_MY2020_Rx" SG_ 734 ACU_CurrTUSID_St 1;
BA_ "U_CD542_MY2021_Rx" SG_ 734 ACU_CurrTUSID_St 1;
BA_ "U_U55X_MY2022_Rx" SG_ 734 ACU_CurrTUSID_St 1;
BA_ "U_P702_MY2021_Tx" SG_ 734 ACU_CurrTUSID_St 1;
BA_ "U_T6_MCA_MY2020_Tx" SG_ 734 ACU_CurrTUSID_St 1;
BA_ "U_CD542_MY2021_Tx" SG_ 734 ACU_CurrTUSID_St 1;
BA_ "U_U55X_MY2022_Tx" SG_ 734 ACU_CurrTUSID_St 1;
BA_ "GenSigStartValueInteger" SG_ 1420 ACM_GWOnBoardTester 255;
BA_ "ContentDependant" SG_ 1420 ACM_GWOnBoardTester 1;
BA_ "GenSigStartValue" SG_ 1420 ACM_GWOnBoardTester 255;
BA_ "U_U55X_MY2022_Rx" SG_ 1420 ACM_GWOnBoardTester 1;
BA_ "U_P702_MY2021_Tx" SG_ 1420 ACM_GWOnBoardTester 1;
BA_ "U_T6_MCA_MY2020_Tx" SG_ 1420 ACM_GWOnBoardTester 1;
BA_ "U_CD542_MY2021_Tx" SG_ 1420 ACM_GWOnBoardTester 1;
BA_ "U_U55X_MY2022_Tx" SG_ 1420 ACM_GWOnBoardTester 1;
BA_ "GenSigStartValueInteger" SG_ 1420 ACM_GWNMProxy 255;
BA_ "ContentDependant" SG_ 1420 ACM_GWNMProxy 1;
BA_ "GenSigStartValue" SG_ 1420 ACM_GWNMProxy 255;
BA_ "U_U55X_MY2022_Rx" SG_ 1420 ACM_GWNMProxy 1;
BA_ "U_P702_MY2021_Tx" SG_ 1420 ACM_GWNMProxy 1;
BA_ "U_T6_MCA_MY2020_Tx" SG_ 1420 ACM_GWNMProxy 1;
BA_ "U_CD542_MY2021_Tx" SG_ 1420 ACM_GWNMProxy 1;
BA_ "U_U55X_MY2022_Tx" SG_ 1420 ACM_GWNMProxy 1;
BA_ "GenSigStartValueInteger" SG_ 1420 ACM_AutoSarNMReserved4 255;
BA_ "ContentDependant" SG_ 1420 ACM_AutoSarNMReserved4 1;
BA_ "GenSigStartValue" SG_ 1420 ACM_AutoSarNMReserved4 255;
BA_ "U_U55X_MY2022_Rx" SG_ 1420 ACM_AutoSarNMReserved4 1;
BA_ "U_P702_MY2021_Tx" SG_ 1420 ACM_AutoSarNMReserved4 1;
BA_ "U_T6_MCA_MY2020_Tx" SG_ 1420 ACM_AutoSarNMReserved4 1;
BA_ "U_CD542_MY2021_Tx" SG_ 1420 ACM_AutoSarNMReserved4 1;
BA_ "U_U55X_MY2022_Tx" SG_ 1420 ACM_AutoSarNMReserved4 1;
BA_ "GenSigStartValueInteger" SG_ 1420 ACM_AutoSarNMReserved3 255;
BA_ "ContentDependant" SG_ 1420 ACM_AutoSarNMReserved3 1;
BA_ "GenSigStartValue" SG_ 1420 ACM_AutoSarNMReserved3 255;
BA_ "U_U55X_MY2022_Rx" SG_ 1420 ACM_AutoSarNMReserved3 1;
BA_ "U_P702_MY2021_Tx" SG_ 1420 ACM_AutoSarNMReserved3 1;
BA_ "U_T6_MCA_MY2020_Tx" SG_ 1420 ACM_AutoSarNMReserved3 1;
BA_ "U_CD542_MY2021_Tx" SG_ 1420 ACM_AutoSarNMReserved3 1;
BA_ "U_U55X_MY2022_Tx" SG_ 1420 ACM_AutoSarNMReserved3 1;
BA_ "GenSigStartValueInteger" SG_ 1420 ACM_AutoSarNMReserved2 255;
BA_ "ContentDependant" SG_ 1420 ACM_AutoSarNMReserved2 1;
BA_ "GenSigStartValue" SG_ 1420 ACM_AutoSarNMReserved2 255;
BA_ "U_U55X_MY2022_Rx" SG_ 1420 ACM_AutoSarNMReserved2 1;
BA_ "U_P702_MY2021_Tx" SG_ 1420 ACM_AutoSarNMReserved2 1;
BA_ "U_T6_MCA_MY2020_Tx" SG_ 1420 ACM_AutoSarNMReserved2 1;
BA_ "U_CD542_MY2021_Tx" SG_ 1420 ACM_AutoSarNMReserved2 1;
BA_ "U_U55X_MY2022_Tx" SG_ 1420 ACM_AutoSarNMReserved2 1;
BA_ "GenSigStartValueInteger" SG_ 1420 ACM_AutoSarNMReserved1 255;
BA_ "ContentDependant" SG_ 1420 ACM_AutoSarNMReserved1 1;
BA_ "GenSigStartValue" SG_ 1420 ACM_AutoSarNMReserved1 255;
BA_ "U_U55X_MY2022_Rx" SG_ 1420 ACM_AutoSarNMReserved1 1;
BA_ "U_P702_MY2021_Tx" SG_ 1420 ACM_AutoSarNMReserved1 1;
BA_ "U_T6_MCA_MY2020_Tx" SG_ 1420 ACM_AutoSarNMReserved1 1;
BA_ "U_CD542_MY2021_Tx" SG_ 1420 ACM_AutoSarNMReserved1 1;
BA_ "U_U55X_MY2022_Tx" SG_ 1420 ACM_AutoSarNMReserved1 1;
BA_ "GenSigStartValueInteger" SG_ 1420 ACM_AutoSarNMNodeId 140;
BA_ "ContentDependant" SG_ 1420 ACM_AutoSarNMNodeId 1;
BA_ "GenSigStartValue" SG_ 1420 ACM_AutoSarNMNodeId 140;
BA_ "U_U55X_MY2022_Rx" SG_ 1420 ACM_AutoSarNMNodeId 1;
BA_ "U_P702_MY2021_Tx" SG_ 1420 ACM_AutoSarNMNodeId 1;
BA_ "U_T6_MCA_MY2020_Tx" SG_ 1420 ACM_AutoSarNMNodeId 1;
BA_ "U_CD542_MY2021_Tx" SG_ 1420 ACM_AutoSarNMNodeId 1;
BA_ "U_U55X_MY2022_Tx" SG_ 1420 ACM_AutoSarNMNodeId 1;
BA_ "ContentDependant" SG_ 1420 ACM_AutoSarNMControl 1;
BA_ "U_U55X_MY2022_Rx" SG_ 1420 ACM_AutoSarNMControl 1;
BA_ "U_P702_MY2021_Tx" SG_ 1420 ACM_AutoSarNMControl 1;
BA_ "U_T6_MCA_MY2020_Tx" SG_ 1420 ACM_AutoSarNMControl 1;
BA_ "U_CD542_MY2021_Tx" SG_ 1420 ACM_AutoSarNMControl 1;
BA_ "U_U55X_MY2022_Tx" SG_ 1420 ACM_AutoSarNMControl 1;
BA_ "GenSigSendType" SG_ 759 Avail_HD_Chan_Valid 3;
BA_ "U_T6_MCA_MY2020_Rx" SG_ 759 Avail_HD_Chan_Valid 1;
BA_ "U_CD542_MY2021_Rx" SG_ 759 Avail_HD_Chan_Valid 1;
BA_ "U_U55X_MY2022_Rx" SG_ 759 Avail_HD_Chan_Valid 1;
BA_ "U_P702_MY2021_Tx" SG_ 759 Avail_HD_Chan_Valid 1;
BA_ "U_T6_MCA_MY2020_Tx" SG_ 759 Avail_HD_Chan_Valid 1;
BA_ "U_CD542_MY2021_Tx" SG_ 759 Avail_HD_Chan_Valid 1;
BA_ "U_U55X_MY2022_Tx" SG_ 759 Avail_HD_Chan_Valid 1;
BA_ "GenSigSendType" SG_ 759 Avail_HD_Chan_St_7 3;
BA_ "U_T6_MCA_MY2020_Rx" SG_ 759 Avail_HD_Chan_St_7 1;
BA_ "U_CD542_MY2021_Rx" SG_ 759 Avail_HD_Chan_St_7 1;
BA_ "U_U55X_MY2022_Rx" SG_ 759 Avail_HD_Chan_St_7 1;
BA_ "U_P702_MY2021_Tx" SG_ 759 Avail_HD_Chan_St_7 1;
BA_ "U_T6_MCA_MY2020_Tx" SG_ 759 Avail_HD_Chan_St_7 1;
BA_ "U_CD542_MY2021_Tx" SG_ 759 Avail_HD_Chan_St_7 1;
BA_ "U_U55X_MY2022_Tx" SG_ 759 Avail_HD_Chan_St_7 1;
BA_ "GenSigSendType" SG_ 759 Avail_HD_Chan_St_6 3;
BA_ "U_T6_MCA_MY2020_Rx" SG_ 759 Avail_HD_Chan_St_6 1;
BA_ "U_CD542_MY2021_Rx" SG_ 759 Avail_HD_Chan_St_6 1;
BA_ "U_U55X_MY2022_Rx" SG_ 759 Avail_HD_Chan_St_6 1;
BA_ "U_P702_MY2021_Tx" SG_ 759 Avail_HD_Chan_St_6 1;
BA_ "U_T6_MCA_MY2020_Tx" SG_ 759 Avail_HD_Chan_St_6 1;
BA_ "U_CD542_MY2021_Tx" SG_ 759 Avail_HD_Chan_St_6 1;
BA_ "U_U55X_MY2022_Tx" SG_ 759 Avail_HD_Chan_St_6 1;
BA_ "GenSigSendType" SG_ 759 Avail_HD_Chan_St_5 3;
BA_ "U_T6_MCA_MY2020_Rx" SG_ 759 Avail_HD_Chan_St_5 1;
BA_ "U_CD542_MY2021_Rx" SG_ 759 Avail_HD_Chan_St_5 1;
BA_ "U_U55X_MY2022_Rx" SG_ 759 Avail_HD_Chan_St_5 1;
BA_ "U_P702_MY2021_Tx" SG_ 759 Avail_HD_Chan_St_5 1;
BA_ "U_T6_MCA_MY2020_Tx" SG_ 759 Avail_HD_Chan_St_5 1;
BA_ "U_CD542_MY2021_Tx" SG_ 759 Avail_HD_Chan_St_5 1;
BA_ "U_U55X_MY2022_Tx" SG_ 759 Avail_HD_Chan_St_5 1;
BA_ "GenSigSendType" SG_ 759 Avail_HD_Chan_St_4 3;
BA_ "U_T6_MCA_MY2020_Rx" SG_ 759 Avail_HD_Chan_St_4 1;
BA_ "U_CD542_MY2021_Rx" SG_ 759 Avail_HD_Chan_St_4 1;
BA_ "U_U55X_MY2022_Rx" SG_ 759 Avail_HD_Chan_St_4 1;
BA_ "U_P702_MY2021_Tx" SG_ 759 Avail_HD_Chan_St_4 1;
BA_ "U_T6_MCA_MY2020_Tx" SG_ 759 Avail_HD_Chan_St_4 1;
BA_ "U_CD542_MY2021_Tx" SG_ 759 Avail_HD_Chan_St_4 1;
BA_ "U_U55X_MY2022_Tx" SG_ 759 Avail_HD_Chan_St_4 1;
BA_ "GenSigSendType" SG_ 759 Avail_HD_Chan_St_3 3;
BA_ "U_T6_MCA_MY2020_Rx" SG_ 759 Avail_HD_Chan_St_3 1;
BA_ "U_CD542_MY2021_Rx" SG_ 759 Avail_HD_Chan_St_3 1;
BA_ "U_U55X_MY2022_Rx" SG_ 759 Avail_HD_Chan_St_3 1;
BA_ "U_P702_MY2021_Tx" SG_ 759 Avail_HD_Chan_St_3 1;
BA_ "U_T6_MCA_MY2020_Tx" SG_ 759 Avail_HD_Chan_St_3 1;
BA_ "U_CD542_MY2021_Tx" SG_ 759 Avail_HD_Chan_St_3 1;
BA_ "U_U55X_MY2022_Tx" SG_ 759 Avail_HD_Chan_St_3 1;
BA_ "GenSigSendType" SG_ 759 Avail_HD_Chan_St_2 3;
BA_ "U_T6_MCA_MY2020_Rx" SG_ 759 Avail_HD_Chan_St_2 1;
BA_ "U_CD542_MY2021_Rx" SG_ 759 Avail_HD_Chan_St_2 1;
BA_ "U_U55X_MY2022_Rx" SG_ 759 Avail_HD_Chan_St_2 1;
BA_ "U_P702_MY2021_Tx" SG_ 759 Avail_HD_Chan_St_2 1;
BA_ "U_T6_MCA_MY2020_Tx" SG_ 759 Avail_HD_Chan_St_2 1;
BA_ "U_CD542_MY2021_Tx" SG_ 759 Avail_HD_Chan_St_2 1;
BA_ "U_U55X_MY2022_Tx" SG_ 759 Avail_HD_Chan_St_2 1;
BA_ "GenSigSendType" SG_ 759 Avail_HD_Chan_St_1 3;
BA_ "U_T6_MCA_MY2020_Rx" SG_ 759 Avail_HD_Chan_St_1 1;
BA_ "U_CD542_MY2021_Rx" SG_ 759 Avail_HD_Chan_St_1 1;
BA_ "U_U55X_MY2022_Rx" SG_ 759 Avail_HD_Chan_St_1 1;
BA_ "U_P702_MY2021_Tx" SG_ 759 Avail_HD_Chan_St_1 1;
BA_ "U_T6_MCA_MY2020_Tx" SG_ 759 Avail_HD_Chan_St_1 1;
BA_ "U_CD542_MY2021_Tx" SG_ 759 Avail_HD_Chan_St_1 1;
BA_ "U_U55X_MY2022_Tx" SG_ 759 Avail_HD_Chan_St_1 1;
BA_ "GenSigSendType" SG_ 759 ACM_StationListScanSt 3;
BA_ "U_T6_MCA_MY2020_Rx" SG_ 759 ACM_StationListScanSt 1;
BA_ "U_CD542_MY2021_Rx" SG_ 759 ACM_StationListScanSt 1;
BA_ "U_P702_MY2021_Rx" SG_ 759 ACM_StationListScanSt 1;
BA_ "U_U55X_MY2022_Rx" SG_ 759 ACM_StationListScanSt 1;
BA_ "U_P702_MY2021_Tx" SG_ 759 ACM_StationListScanSt 1;
BA_ "U_T6_MCA_MY2020_Tx" SG_ 759 ACM_StationListScanSt 1;
BA_ "U_CD542_MY2021_Tx" SG_ 759 ACM_StationListScanSt 1;
BA_ "U_U55X_MY2022_Tx" SG_ 759 ACM_StationListScanSt 1;
BA_ "GenSigSendType" SG_ 759 ACM_TagMode 3;
BA_ "U_T6_MCA_MY2020_Rx" SG_ 759 ACM_TagMode 1;
BA_ "U_CD542_MY2021_Rx" SG_ 759 ACM_TagMode 1;
BA_ "U_P702_MY2021_Rx" SG_ 759 ACM_TagMode 1;
BA_ "U_U55X_MY2022_Rx" SG_ 759 ACM_TagMode 1;
BA_ "U_P702_MY2021_Tx" SG_ 759 ACM_TagMode 1;
BA_ "U_T6_MCA_MY2020_Tx" SG_ 759 ACM_TagMode 1;
BA_ "U_CD542_MY2021_Tx" SG_ 759 ACM_TagMode 1;
BA_ "U_U55X_MY2022_Tx" SG_ 759 ACM_TagMode 1;
BA_ "GenSigSendType" SG_ 759 ACM_RBDSMode 3;
BA_ "U_T6_MCA_MY2020_Rx" SG_ 759 ACM_RBDSMode 1;
BA_ "U_CD542_MY2021_Rx" SG_ 759 ACM_RBDSMode 1;
BA_ "U_P702_MY2021_Rx" SG_ 759 ACM_RBDSMode 1;
BA_ "U_U55X_MY2022_Rx" SG_ 759 ACM_RBDSMode 1;
BA_ "U_P702_MY2021_Tx" SG_ 759 ACM_RBDSMode 1;
BA_ "U_T6_MCA_MY2020_Tx" SG_ 759 ACM_RBDSMode 1;
BA_ "U_CD542_MY2021_Tx" SG_ 759 ACM_RBDSMode 1;
BA_ "U_U55X_MY2022_Tx" SG_ 759 ACM_RBDSMode 1;
BA_ "GenSigSendType" SG_ 759 NumofHDMulticastChans_St 3;
BA_ "U_T6_MCA_MY2020_Rx" SG_ 759 NumofHDMulticastChans_St 1;
BA_ "U_CD542_MY2021_Rx" SG_ 759 NumofHDMulticastChans_St 1;
BA_ "U_U55X_MY2022_Rx" SG_ 759 NumofHDMulticastChans_St 1;
BA_ "U_P702_MY2021_Rx" SG_ 759 NumofHDMulticastChans_St 1;
BA_ "U_P702_MY2021_Tx" SG_ 759 NumofHDMulticastChans_St 1;
BA_ "U_T6_MCA_MY2020_Tx" SG_ 759 NumofHDMulticastChans_St 1;
BA_ "U_U55X_MY2022_Tx" SG_ 759 NumofHDMulticastChans_St 1;
BA_ "GenSigSendType" SG_ 759 ACM_HDModeStatus 3;
BA_ "U_T6_MCA_MY2020_Rx" SG_ 759 ACM_HDModeStatus 1;
BA_ "U_CD542_MY2021_Rx" SG_ 759 ACM_HDModeStatus 1;
BA_ "U_P702_MY2021_Rx" SG_ 759 ACM_HDModeStatus 1;
BA_ "U_U55X_MY2022_Rx" SG_ 759 ACM_HDModeStatus 1;
BA_ "U_P702_MY2021_Tx" SG_ 759 ACM_HDModeStatus 1;
BA_ "U_T6_MCA_MY2020_Tx" SG_ 759 ACM_HDModeStatus 1;
BA_ "U_CD542_MY2021_Tx" SG_ 759 ACM_HDModeStatus 1;
BA_ "U_U55X_MY2022_Tx" SG_ 759 ACM_HDModeStatus 1;
BA_ "GenSigSendType" SG_ 759 ACM_HDChanStatus 3;
BA_ "U_T6_MCA_MY2020_Rx" SG_ 759 ACM_HDChanStatus 1;
BA_ "U_CD542_MY2021_Rx" SG_ 759 ACM_HDChanStatus 1;
BA_ "U_U55X_MY2022_Rx" SG_ 759 ACM_HDChanStatus 1;
BA_ "U_P702_MY2021_Rx" SG_ 759 ACM_HDChanStatus 1;
BA_ "U_P702_MY2021_Tx" SG_ 759 ACM_HDChanStatus 1;
BA_ "U_T6_MCA_MY2020_Tx" SG_ 759 ACM_HDChanStatus 1;
BA_ "U_CD542_MY2021_Tx" SG_ 759 ACM_HDChanStatus 1;
BA_ "U_U55X_MY2022_Tx" SG_ 759 ACM_HDChanStatus 1;
BA_ "GenSigSendType" SG_ 759 ACM_CurrentSSName 3;
BA_ "U_T6_MCA_MY2020_Rx" SG_ 759 ACM_CurrentSSName 1;
BA_ "U_CD542_MY2021_Rx" SG_ 759 ACM_CurrentSSName 1;
BA_ "U_U55X_MY2022_Rx" SG_ 759 ACM_CurrentSSName 1;
BA_ "U_P702_MY2021_Rx" SG_ 759 ACM_CurrentSSName 1;
BA_ "U_P702_MY2021_Tx" SG_ 759 ACM_CurrentSSName 1;
BA_ "U_T6_MCA_MY2020_Tx" SG_ 759 ACM_CurrentSSName 1;
BA_ "U_CD542_MY2021_Tx" SG_ 759 ACM_CurrentSSName 1;
BA_ "U_U55X_MY2022_Tx" SG_ 759 ACM_CurrentSSName 1;
BA_ "GenSigSendType" SG_ 759 ACM_CurrentHDMulticast_St 3;
BA_ "U_T6_MCA_MY2020_Rx" SG_ 759 ACM_CurrentHDMulticast_St 1;
BA_ "U_CD542_MY2021_Rx" SG_ 759 ACM_CurrentHDMulticast_St 1;
BA_ "U_P702_MY2021_Rx" SG_ 759 ACM_CurrentHDMulticast_St 1;
BA_ "U_U55X_MY2022_Rx" SG_ 759 ACM_CurrentHDMulticast_St 1;
BA_ "U_P702_MY2021_Tx" SG_ 759 ACM_CurrentHDMulticast_St 1;
BA_ "U_T6_MCA_MY2020_Tx" SG_ 759 ACM_CurrentHDMulticast_St 1;
BA_ "U_U55X_MY2022_Tx" SG_ 759 ACM_CurrentHDMulticast_St 1;
BA_ "GenSigSendType" SG_ 144 SetTimeFormat 3;
BA_ "U_P702_MY2021_Tx" SG_ 144 SetTimeFormat 1;
BA_ "U_T6_MCA_MY2020_Tx" SG_ 144 SetTimeFormat 1;
BA_ "U_CD542_MY2021_Tx" SG_ 144 SetTimeFormat 1;
BA_ "U_U55X_MY2022_Tx" SG_ 144 SetTimeFormat 1;
BA_ "U_P702_MY2021_Tx" SG_ 144 SetYear 1;
BA_ "U_T6_MCA_MY2020_Tx" SG_ 144 SetYear 1;
BA_ "U_CD542_MY2021_Tx" SG_ 144 SetYear 1;
BA_ "U_U55X_MY2022_Tx" SG_ 144 SetYear 1;
BA_ "U_P702_MY2021_Tx" SG_ 144 SetMonth 1;
BA_ "U_T6_MCA_MY2020_Tx" SG_ 144 SetMonth 1;
BA_ "U_CD542_MY2021_Tx" SG_ 144 SetMonth 1;
BA_ "U_U55X_MY2022_Tx" SG_ 144 SetMonth 1;
BA_ "U_P702_MY2021_Tx" SG_ 144 SetDay 1;
BA_ "U_T6_MCA_MY2020_Tx" SG_ 144 SetDay 1;
BA_ "U_CD542_MY2021_Tx" SG_ 144 SetDay 1;
BA_ "U_U55X_MY2022_Tx" SG_ 144 SetDay 1;
BA_ "U_P702_MY2021_Tx" SG_ 144 SetHour 1;
BA_ "U_T6_MCA_MY2020_Tx" SG_ 144 SetHour 1;
BA_ "U_CD542_MY2021_Tx" SG_ 144 SetHour 1;
BA_ "U_U55X_MY2022_Tx" SG_ 144 SetHour 1;
BA_ "U_P702_MY2021_Tx" SG_ 144 SetMinute 1;
BA_ "U_T6_MCA_MY2020_Tx" SG_ 144 SetMinute 1;
BA_ "U_CD542_MY2021_Tx" SG_ 144 SetMinute 1;
BA_ "U_U55X_MY2022_Tx" SG_ 144 SetMinute 1;
BA_ "U_P702_MY2021_Tx" SG_ 144 SetSecond 1;
BA_ "U_T6_MCA_MY2020_Tx" SG_ 144 SetSecond 1;
BA_ "U_CD542_MY2021_Tx" SG_ 144 SetSecond 1;
BA_ "U_U55X_MY2022_Tx" SG_ 144 SetSecond 1;
BA_ "GenSigSendType" SG_ 144 TimeAdjustRequest 3;
BA_ "U_P702_MY2021_Tx" SG_ 144 TimeAdjustRequest 1;
BA_ "U_T6_MCA_MY2020_Tx" SG_ 144 TimeAdjustRequest 1;
BA_ "U_CD542_MY2021_Tx" SG_ 144 TimeAdjustRequest 1;
BA_ "U_U55X_MY2022_Tx" SG_ 144 TimeAdjustRequest 1;
BA_ "GenSigSendType" SG_ 144 DateAdjustRequest 3;
BA_ "U_T6_MCA_MY2020_Rx" SG_ 144 DateAdjustRequest 1;
BA_ "U_U55X_MY2022_Rx" SG_ 144 DateAdjustRequest 1;
BA_ "U_P702_MY2021_Tx" SG_ 144 DateAdjustRequest 1;
BA_ "U_T6_MCA_MY2020_Tx" SG_ 144 DateAdjustRequest 1;
BA_ "U_CD542_MY2021_Tx" SG_ 144 DateAdjustRequest 1;
BA_ "U_U55X_MY2022_Tx" SG_ 144 DateAdjustRequest 1;
BA_ "U_T6_MCA_MY2020_Rx" SG_ 851 ConsLongTerm_No_Dsply 1;
BA_ "ECGUsedRxSignal" SG_ 851 ConsLongTerm_No_Dsply 1;
BA_ "U_CD542_MY2021_Rx" SG_ 851 ConsLongTerm_No_Dsply 1;
BA_ "U_U55X_MY2022_Rx" SG_ 851 ConsLongTerm_No_Dsply 1;
BA_ "U_P702_MY2021_Tx" SG_ 851 ConsLongTerm_No_Dsply 1;
BA_ "U_T6_MCA_MY2020_Tx" SG_ 851 ConsLongTerm_No_Dsply 1;
BA_ "U_CD542_MY2021_Tx" SG_ 851 ConsLongTerm_No_Dsply 1;
BA_ "U_U55X_MY2022_Tx" SG_ 851 ConsLongTerm_No_Dsply 1;
BA_ "GenSigSendType" SG_ 851 ConsUnitIPC_D_Dsply 3;
BA_ "U_P702_MY2021_Rx" SG_ 851 ConsUnitIPC_D_Dsply 1;
BA_ "U_T6_MCA_MY2020_Rx" SG_ 851 ConsUnitIPC_D_Dsply 1;
BA_ "U_CD542_MY2021_Rx" SG_ 851 ConsUnitIPC_D_Dsply 1;
BA_ "U_U55X_MY2022_Rx" SG_ 851 ConsUnitIPC_D_Dsply 1;
BA_ "ECGUsedRxSignal" SG_ 851 ConsUnitIPC_D_Dsply 1;
BA_ "U_P702_MY2021_Tx" SG_ 851 ConsUnitIPC_D_Dsply 1;
BA_ "U_T6_MCA_MY2020_Tx" SG_ 851 ConsUnitIPC_D_Dsply 1;
BA_ "U_CD542_MY2021_Tx" SG_ 851 ConsUnitIPC_D_Dsply 1;
BA_ "U_U55X_MY2022_Tx" SG_ 851 ConsUnitIPC_D_Dsply 1;
BA_ "U_T6_MCA_MY2020_Rx" SG_ 851 ConsAvgTrip_No_Dsply 1;
BA_ "ECGUsedRxSignal" SG_ 851 ConsAvgTrip_No_Dsply 1;
BA_ "U_CD542_MY2021_Rx" SG_ 851 ConsAvgTrip_No_Dsply 1;
BA_ "U_U55X_MY2022_Rx" SG_ 851 ConsAvgTrip_No_Dsply 1;
BA_ "U_P702_MY2021_Tx" SG_ 851 ConsAvgTrip_No_Dsply 1;
BA_ "U_T6_MCA_MY2020_Tx" SG_ 851 ConsAvgTrip_No_Dsply 1;
BA_ "U_CD542_MY2021_Tx" SG_ 851 ConsAvgTrip_No_Dsply 1;
BA_ "U_U55X_MY2022_Tx" SG_ 851 ConsAvgTrip_No_Dsply 1;
BA_ "U_P702_MY2021_Rx" SG_ 792 FuelRange_L_Dsply 1;
BA_ "U_T6_MCA_MY2020_Rx" SG_ 792 FuelRange_L_Dsply 1;
BA_ "U_U55X_MY2022_Rx" SG_ 792 FuelRange_L_Dsply 1;
BA_ "U_CD542_MY2021_Rx" SG_ 792 FuelRange_L_Dsply 1;
BA_ "ECGUsedRxSignal" SG_ 792 FuelRange_L_Dsply 1;
BA_ "U_P702_MY2021_Tx" SG_ 792 FuelRange_L_Dsply 1;
BA_ "U_T6_MCA_MY2020_Tx" SG_ 792 FuelRange_L_Dsply 1;
BA_ "U_CD542_MY2021_Tx" SG_ 792 FuelRange_L_Dsply 1;
BA_ "U_U55X_MY2022_Tx" SG_ 792 FuelRange_L_Dsply 1;
BA_ "ContentDependant" SG_ 792 ElTrip_L_Dsply 1;
BA_ "U_T6_MCA_MY2020_Rx" SG_ 792 ElTrip_L_Dsply 1;
BA_ "ECGUsedRxSignal" SG_ 792 ElTrip_L_Dsply 1;
BA_ "U_CD542_MY2021_Rx" SG_ 792 ElTrip_L_Dsply 1;
BA_ "U_U55X_MY2022_Rx" SG_ 792 ElTrip_L_Dsply 1;
BA_ "U_P702_MY2021_Tx" SG_ 792 ElTrip_L_Dsply 1;
BA_ "U_T6_MCA_MY2020_Tx" SG_ 792 ElTrip_L_Dsply 1;
BA_ "U_CD542_MY2021_Tx" SG_ 792 ElTrip_L_Dsply 1;
BA_ "U_U55X_MY2022_Tx" SG_ 792 ElTrip_L_Dsply 1;
BA_ "ContentDependant" SG_ 792 ElLongTerm_L_Dsply 1;
BA_ "U_T6_MCA_MY2020_Rx" SG_ 792 ElLongTerm_L_Dsply 1;
BA_ "ECGUsedRxSignal" SG_ 792 ElLongTerm_L_Dsply 1;
BA_ "U_CD542_MY2021_Rx" SG_ 792 ElLongTerm_L_Dsply 1;
BA_ "U_U55X_MY2022_Rx" SG_ 792 ElLongTerm_L_Dsply 1;
BA_ "U_P702_MY2021_Tx" SG_ 792 ElLongTerm_L_Dsply 1;
BA_ "U_T6_MCA_MY2020_Tx" SG_ 792 ElLongTerm_L_Dsply 1;
BA_ "U_CD542_MY2021_Tx" SG_ 792 ElLongTerm_L_Dsply 1;
BA_ "U_U55X_MY2022_Tx" SG_ 792 ElLongTerm_L_Dsply 1;
BA_ "U_P702_MY2021_Tx" SG_ 787 VehElSurpStat_L_Dsply 1;
BA_ "U_T6_MCA_MY2020_Tx" SG_ 787 VehElSurpStat_L_Dsply 1;
BA_ "U_CD542_MY2021_Tx" SG_ 787 VehElSurpStat_L_Dsply 1;
BA_ "U_U55X_MY2022_Tx" SG_ 787 VehElSurpStat_L_Dsply 1;
BA_ "U_T6_MCA_MY2020_Rx" SG_ 787 TripSum_Vl_Dsply 1;
BA_ "ECGUsedRxSignal" SG_ 787 TripSum_Vl_Dsply 1;
BA_ "U_CD542_MY2021_Rx" SG_ 787 TripSum_Vl_Dsply 1;
BA_ "U_U55X_MY2022_Rx" SG_ 787 TripSum_Vl_Dsply 1;
BA_ "U_P702_MY2021_Tx" SG_ 787 TripSum_Vl_Dsply 1;
BA_ "U_T6_MCA_MY2020_Tx" SG_ 787 TripSum_Vl_Dsply 1;
BA_ "U_CD542_MY2021_Tx" SG_ 787 TripSum_Vl_Dsply 1;
BA_ "U_U55X_MY2022_Tx" SG_ 787 TripSum_Vl_Dsply 1;
BA_ "U_T6_MCA_MY2020_Rx" SG_ 787 TripSum_E_Dsply 1;
BA_ "ECGUsedRxSignal" SG_ 787 TripSum_E_Dsply 1;
BA_ "U_CD542_MY2021_Rx" SG_ 787 TripSum_E_Dsply 1;
BA_ "U_U55X_MY2022_Rx" SG_ 787 TripSum_E_Dsply 1;
BA_ "U_P702_MY2021_Tx" SG_ 787 TripSum_E_Dsply 1;
BA_ "U_T6_MCA_MY2020_Tx" SG_ 787 TripSum_E_Dsply 1;
BA_ "U_CD542_MY2021_Tx" SG_ 787 TripSum_E_Dsply 1;
BA_ "U_U55X_MY2022_Tx" SG_ 787 TripSum_E_Dsply 1;
BA_ "U_T6_MCA_MY2020_Rx" SG_ 787 TripSum_L_Dsply 1;
BA_ "ECGUsedRxSignal" SG_ 787 TripSum_L_Dsply 1;
BA_ "U_CD542_MY2021_Rx" SG_ 787 TripSum_L_Dsply 1;
BA_ "U_U55X_MY2022_Rx" SG_ 787 TripSum_L_Dsply 1;
BA_ "U_P702_MY2021_Tx" SG_ 787 TripSum_L_Dsply 1;
BA_ "U_T6_MCA_MY2020_Tx" SG_ 787 TripSum_L_Dsply 1;
BA_ "U_CD542_MY2021_Tx" SG_ 787 TripSum_L_Dsply 1;
BA_ "U_U55X_MY2022_Tx" SG_ 787 TripSum_L_Dsply 1;
BA_ "U_P702_MY2021_Rx" SG_ 697 AUDIO_MC_WORD_Rx 1;
BA_ "U_T6_MCA_MY2020_Rx" SG_ 697 AUDIO_MC_WORD_Rx 1;
BA_ "U_CD542_MY2021_Rx" SG_ 697 AUDIO_MC_WORD_Rx 1;
BA_ "U_U55X_MY2022_Rx" SG_ 697 AUDIO_MC_WORD_Rx 1;
BA_ "U_T6_MCA_MY2020_Tx" SG_ 697 AUDIO_MC_WORD_Rx 1;
BA_ "U_CD542_MY2021_Tx" SG_ 697 AUDIO_MC_WORD_Rx 1;
BA_ "U_U55X_MY2022_Tx" SG_ 697 AUDIO_MC_WORD_Rx 1;
BA_ "U_P702_MY2021_Rx" SG_ 700 AUDIO_RDISP_WORD_Rx 1;
BA_ "U_T6_MCA_MY2020_Rx" SG_ 700 AUDIO_RDISP_WORD_Rx 1;
BA_ "U_CD542_MY2021_Rx" SG_ 700 AUDIO_RDISP_WORD_Rx 1;
BA_ "U_U55X_MY2022_Rx" SG_ 700 AUDIO_RDISP_WORD_Rx 1;
BA_ "U_P702_MY2021_Tx" SG_ 700 AUDIO_RDISP_WORD_Rx 1;
BA_ "U_T6_MCA_MY2020_Tx" SG_ 700 AUDIO_RDISP_WORD_Rx 1;
BA_ "U_CD542_MY2021_Tx" SG_ 700 AUDIO_RDISP_WORD_Rx 1;
BA_ "U_U55X_MY2022_Tx" SG_ 700 AUDIO_RDISP_WORD_Rx 1;
BA_ "U_P702_MY2021_Rx" SG_ 676 MC_RDISP_WORD_Tx 1;
BA_ "U_T6_MCA_MY2020_Rx" SG_ 676 MC_RDISP_WORD_Tx 1;
BA_ "U_CD542_MY2021_Rx" SG_ 676 MC_RDISP_WORD_Tx 1;
BA_ "U_U55X_MY2022_Rx" SG_ 676 MC_RDISP_WORD_Tx 1;
BA_ "U_T6_MCA_MY2020_Tx" SG_ 676 MC_RDISP_WORD_Tx 1;
BA_ "U_CD542_MY2021_Tx" SG_ 676 MC_RDISP_WORD_Tx 1;
BA_ "U_U55X_MY2022_Tx" SG_ 676 MC_RDISP_WORD_Tx 1;
BA_ "GenSigSendType" SG_ 504 Mc_AudioSourceSel_Rq 3;
BA_ "U_T6_MCA_MY2020_Rx" SG_ 504 Mc_AudioSourceSel_Rq 1;
BA_ "U_U55X_MY2022_Rx" SG_ 504 Mc_AudioSourceSel_Rq 1;
BA_ "U_T6_MCA_MY2020_Tx" SG_ 504 Mc_AudioSourceSel_Rq 1;
BA_ "U_U55X_MY2022_Tx" SG_ 504 Mc_AudioSourceSel_Rq 1;
BA_ "U_T6_MCA_MY2020_Rx" SG_ 504 Mc_FolderNumber_Rq 1;
BA_ "U_U55X_MY2022_Rx" SG_ 504 Mc_FolderNumber_Rq 1;
BA_ "U_T6_MCA_MY2020_Tx" SG_ 504 Mc_FolderNumber_Rq 1;
BA_ "U_U55X_MY2022_Tx" SG_ 504 Mc_FolderNumber_Rq 1;
BA_ "U_T6_MCA_MY2020_Rx" SG_ 504 Mc_CutItem_Rq 1;
BA_ "U_U55X_MY2022_Rx" SG_ 504 Mc_CutItem_Rq 1;
BA_ "U_T6_MCA_MY2020_Tx" SG_ 504 Mc_CutItem_Rq 1;
BA_ "U_U55X_MY2022_Tx" SG_ 504 Mc_CutItem_Rq 1;
BA_ "U_T6_MCA_MY2020_Rx" SG_ 504 Mc_ItemNameLength_Rq 1;
BA_ "U_U55X_MY2022_Rx" SG_ 504 Mc_ItemNameLength_Rq 1;
BA_ "U_T6_MCA_MY2020_Tx" SG_ 504 Mc_ItemNameLength_Rq 1;
BA_ "U_U55X_MY2022_Tx" SG_ 504 Mc_ItemNameLength_Rq 1;
BA_ "U_T6_MCA_MY2020_Rx" SG_ 504 Mc_SourceSetTrack_Rq 1;
BA_ "U_U55X_MY2022_Rx" SG_ 504 Mc_SourceSetTrack_Rq 1;
BA_ "U_T6_MCA_MY2020_Tx" SG_ 504 Mc_SourceSetTrack_Rq 1;
BA_ "U_U55X_MY2022_Tx" SG_ 504 Mc_SourceSetTrack_Rq 1;
BA_ "GenSigSendType" SG_ 410 MyKey_e911Override_St 3;
BA_ "U_P702_MY2021_Rx" SG_ 410 MyKey_e911Override_St 1;
BA_ "U_T6_MCA_MY2020_Rx" SG_ 410 MyKey_e911Override_St 1;
BA_ "U_CD542_MY2021_Rx" SG_ 410 MyKey_e911Override_St 1;
BA_ "U_U55X_MY2022_Rx" SG_ 410 MyKey_e911Override_St 1;
BA_ "U_P702_MY2021_Tx" SG_ 410 MyKey_e911Override_St 1;
BA_ "U_T6_MCA_MY2020_Tx" SG_ 410 MyKey_e911Override_St 1;
BA_ "U_CD542_MY2021_Tx" SG_ 410 MyKey_e911Override_St 1;
BA_ "U_U55X_MY2022_Tx" SG_ 410 MyKey_e911Override_St 1;
BA_ "GenSigSendType" SG_ 410 DoNotDisturbOveride_St 3;
BA_ "U_P702_MY2021_Rx" SG_ 410 DoNotDisturbOveride_St 1;
BA_ "U_T6_MCA_MY2020_Rx" SG_ 410 DoNotDisturbOveride_St 1;
BA_ "U_CD542_MY2021_Rx" SG_ 410 DoNotDisturbOveride_St 1;
BA_ "U_U55X_MY2022_Rx" SG_ 410 DoNotDisturbOveride_St 1;
BA_ "U_P702_MY2021_Tx" SG_ 410 DoNotDisturbOveride_St 1;
BA_ "U_T6_MCA_MY2020_Tx" SG_ 410 DoNotDisturbOveride_St 1;
BA_ "U_CD542_MY2021_Tx" SG_ 410 DoNotDisturbOveride_St 1;
BA_ "U_U55X_MY2022_Tx" SG_ 410 DoNotDisturbOveride_St 1;
BA_ "GenSigSendType" SG_ 1124 GPS_Vdop 1;
BA_ "U_CD542_MY2021_Tx" SG_ 1124 GPS_Vdop 1;
BA_ "U_U55X_MY2022_Tx" SG_ 1124 GPS_Vdop 1;
BA_ "U_P702_MY2021_Tx" SG_ 1124 GPS_Vdop 1;
BA_ "U_T6_MCA_MY2020_Tx" SG_ 1124 GPS_Vdop 1;
BA_ "U_T6_MCA_MY2020_Rx" SG_ 1124 GPS_Speed 1;
BA_ "ECGUsedRxSignal" SG_ 1124 GPS_Speed 1;
BA_ "U_CD542_MY2021_Rx" SG_ 1124 GPS_Speed 1;
BA_ "U_U55X_MY2022_Rx" SG_ 1124 GPS_Speed 1;
BA_ "U_CD542_MY2021_Tx" SG_ 1124 GPS_Speed 1;
BA_ "U_U55X_MY2022_Tx" SG_ 1124 GPS_Speed 1;
BA_ "U_P702_MY2021_Tx" SG_ 1124 GPS_Speed 1;
BA_ "U_T6_MCA_MY2020_Tx" SG_ 1124 GPS_Speed 1;
BA_ "U_CD542_MY2021_Tx" SG_ 1124 GPS_Sat_num_in_view 1;
BA_ "U_U55X_MY2022_Tx" SG_ 1124 GPS_Sat_num_in_view 1;
BA_ "U_P702_MY2021_Tx" SG_ 1124 GPS_Sat_num_in_view 1;
BA_ "U_T6_MCA_MY2020_Tx" SG_ 1124 GPS_Sat_num_in_view 1;
BA_ "U_T6_MCA_MY2020_Rx" SG_ 1124 GPS_MSL_altitude 1;
BA_ "ECGUsedRxSignal" SG_ 1124 GPS_MSL_altitude 1;
BA_ "U_CD542_MY2021_Rx" SG_ 1124 GPS_MSL_altitude 1;
BA_ "U_U55X_MY2022_Rx" SG_ 1124 GPS_MSL_altitude 1;
BA_ "U_CD542_MY2021_Tx" SG_ 1124 GPS_MSL_altitude 1;
BA_ "U_U55X_MY2022_Tx" SG_ 1124 GPS_MSL_altitude 1;
BA_ "U_P702_MY2021_Tx" SG_ 1124 GPS_MSL_altitude 1;
BA_ "U_T6_MCA_MY2020_Tx" SG_ 1124 GPS_MSL_altitude 1;
BA_ "U_T6_MCA_MY2020_Rx" SG_ 1124 GPS_Heading 1;
BA_ "ECGUsedRxSignal" SG_ 1124 GPS_Heading 1;
BA_ "U_CD542_MY2021_Rx" SG_ 1124 GPS_Heading 1;
BA_ "U_U55X_MY2022_Rx" SG_ 1124 GPS_Heading 1;
BA_ "U_CD542_MY2021_Tx" SG_ 1124 GPS_Heading 1;
BA_ "U_U55X_MY2022_Tx" SG_ 1124 GPS_Heading 1;
BA_ "U_P702_MY2021_Tx" SG_ 1124 GPS_Heading 1;
BA_ "U_T6_MCA_MY2020_Tx" SG_ 1124 GPS_Heading 1;
BA_ "U_CD542_MY2021_Tx" SG_ 1124 GPS_Hdop 1;
BA_ "U_U55X_MY2022_Tx" SG_ 1124 GPS_Hdop 1;
BA_ "U_P702_MY2021_Tx" SG_ 1124 GPS_Hdop 1;
BA_ "U_T6_MCA_MY2020_Tx" SG_ 1124 GPS_Hdop 1;
BA_ "U_T6_MCA_MY2020_Rx" SG_ 1124 GPS_dimension 1;
BA_ "ECGUsedRxSignal" SG_ 1124 GPS_dimension 1;
BA_ "U_CD542_MY2021_Rx" SG_ 1124 GPS_dimension 1;
BA_ "U_U55X_MY2022_Rx" SG_ 1124 GPS_dimension 1;
BA_ "U_CD542_MY2021_Tx" SG_ 1124 GPS_dimension 1;
BA_ "U_U55X_MY2022_Tx" SG_ 1124 GPS_dimension 1;
BA_ "U_P702_MY2021_Tx" SG_ 1124 GPS_dimension 1;
BA_ "U_T6_MCA_MY2020_Tx" SG_ 1124 GPS_dimension 1;
BA_ "U_T6_MCA_MY2020_Rx" SG_ 1123 GpsUtcYr_No_Actl 1;
BA_ "ECGUsedRxSignal" SG_ 1123 GpsUtcYr_No_Actl 1;
BA_ "U_CD542_MY2021_Rx" SG_ 1123 GpsUtcYr_No_Actl 1;
BA_ "U_U55X_MY2022_Rx" SG_ 1123 GpsUtcYr_No_Actl 1;
BA_ "U_CD542_MY2021_Tx" SG_ 1123 GpsUtcYr_No_Actl 1;
BA_ "U_U55X_MY2022_Tx" SG_ 1123 GpsUtcYr_No_Actl 1;
BA_ "U_P702_MY2021_Tx" SG_ 1123 GpsUtcYr_No_Actl 1;
BA_ "U_T6_MCA_MY2020_Tx" SG_ 1123 GpsUtcYr_No_Actl 1;
BA_ "GenSigStartValueInteger" SG_ 1123 GpsUtcMnth_No_Actl 1;
BA_ "GenSigStartValue" SG_ 1123 GpsUtcMnth_No_Actl 1;
BA_ "U_T6_MCA_MY2020_Rx" SG_ 1123 GpsUtcMnth_No_Actl 1;
BA_ "ECGUsedRxSignal" SG_ 1123 GpsUtcMnth_No_Actl 1;
BA_ "U_CD542_MY2021_Rx" SG_ 1123 GpsUtcMnth_No_Actl 1;
BA_ "U_U55X_MY2022_Rx" SG_ 1123 GpsUtcMnth_No_Actl 1;
BA_ "U_CD542_MY2021_Tx" SG_ 1123 GpsUtcMnth_No_Actl 1;
BA_ "U_U55X_MY2022_Tx" SG_ 1123 GpsUtcMnth_No_Actl 1;
BA_ "U_P702_MY2021_Tx" SG_ 1123 GpsUtcMnth_No_Actl 1;
BA_ "U_T6_MCA_MY2020_Tx" SG_ 1123 GpsUtcMnth_No_Actl 1;
BA_ "GenSigStartValueInteger" SG_ 1123 GpsUtcDay_No_Actl 1;
BA_ "GenSigStartValue" SG_ 1123 GpsUtcDay_No_Actl 1;
BA_ "U_T6_MCA_MY2020_Rx" SG_ 1123 GpsUtcDay_No_Actl 1;
BA_ "ECGUsedRxSignal" SG_ 1123 GpsUtcDay_No_Actl 1;
BA_ "U_CD542_MY2021_Rx" SG_ 1123 GpsUtcDay_No_Actl 1;
BA_ "U_U55X_MY2022_Rx" SG_ 1123 GpsUtcDay_No_Actl 1;
BA_ "U_CD542_MY2021_Tx" SG_ 1123 GpsUtcDay_No_Actl 1;
BA_ "U_U55X_MY2022_Tx" SG_ 1123 GpsUtcDay_No_Actl 1;
BA_ "U_P702_MY2021_Tx" SG_ 1123 GpsUtcDay_No_Actl 1;
BA_ "U_T6_MCA_MY2020_Tx" SG_ 1123 GpsUtcDay_No_Actl 1;
BA_ "U_T6_MCA_MY2020_Rx" SG_ 1123 GPS_UTC_seconds 1;
BA_ "ECGUsedRxSignal" SG_ 1123 GPS_UTC_seconds 1;
BA_ "U_CD542_MY2021_Rx" SG_ 1123 GPS_UTC_seconds 1;
BA_ "U_U55X_MY2022_Rx" SG_ 1123 GPS_UTC_seconds 1;
BA_ "U_CD542_MY2021_Tx" SG_ 1123 GPS_UTC_seconds 1;
BA_ "U_U55X_MY2022_Tx" SG_ 1123 GPS_UTC_seconds 1;
BA_ "U_P702_MY2021_Tx" SG_ 1123 GPS_UTC_seconds 1;
BA_ "U_T6_MCA_MY2020_Tx" SG_ 1123 GPS_UTC_seconds 1;
BA_ "U_T6_MCA_MY2020_Rx" SG_ 1123 GPS_UTC_minutes 1;
BA_ "ECGUsedRxSignal" SG_ 1123 GPS_UTC_minutes 1;
BA_ "U_CD542_MY2021_Rx" SG_ 1123 GPS_UTC_minutes 1;
BA_ "U_U55X_MY2022_Rx" SG_ 1123 GPS_UTC_minutes 1;
BA_ "U_CD542_MY2021_Tx" SG_ 1123 GPS_UTC_minutes 1;
BA_ "U_U55X_MY2022_Tx" SG_ 1123 GPS_UTC_minutes 1;
BA_ "U_P702_MY2021_Tx" SG_ 1123 GPS_UTC_minutes 1;
BA_ "U_T6_MCA_MY2020_Tx" SG_ 1123 GPS_UTC_minutes 1;
BA_ "U_T6_MCA_MY2020_Rx" SG_ 1123 GPS_UTC_hours 1;
BA_ "ECGUsedRxSignal" SG_ 1123 GPS_UTC_hours 1;
BA_ "U_CD542_MY2021_Rx" SG_ 1123 GPS_UTC_hours 1;
BA_ "U_U55X_MY2022_Rx" SG_ 1123 GPS_UTC_hours 1;
BA_ "U_CD542_MY2021_Tx" SG_ 1123 GPS_UTC_hours 1;
BA_ "U_U55X_MY2022_Tx" SG_ 1123 GPS_UTC_hours 1;
BA_ "U_P702_MY2021_Tx" SG_ 1123 GPS_UTC_hours 1;
BA_ "U_T6_MCA_MY2020_Tx" SG_ 1123 GPS_UTC_hours 1;
BA_ "U_CD542_MY2021_Tx" SG_ 1123 GPS_Pdop 1;
BA_ "U_U55X_MY2022_Tx" SG_ 1123 GPS_Pdop 1;
BA_ "U_P702_MY2021_Tx" SG_ 1123 GPS_Pdop 1;
BA_ "U_T6_MCA_MY2020_Tx" SG_ 1123 GPS_Pdop 1;
BA_ "U_T6_MCA_MY2020_Rx" SG_ 1123 GPS_Compass_direction 1;
BA_ "U_CD542_MY2021_Rx" SG_ 1123 GPS_Compass_direction 1;
BA_ "U_U55X_MY2022_Rx" SG_ 1123 GPS_Compass_direction 1;
BA_ "ECGUsedRxSignal" SG_ 1123 GPS_Compass_direction 1;
BA_ "U_CD542_MY2021_Tx" SG_ 1123 GPS_Compass_direction 1;
BA_ "U_U55X_MY2022_Tx" SG_ 1123 GPS_Compass_direction 1;
BA_ "U_P702_MY2021_Tx" SG_ 1123 GPS_Compass_direction 1;
BA_ "U_T6_MCA_MY2020_Tx" SG_ 1123 GPS_Compass_direction 1;
BA_ "GenSigSendType" SG_ 1123 GPS_Actual_vs_Infer_pos 1;
BA_ "U_T6_MCA_MY2020_Rx" SG_ 1123 GPS_Actual_vs_Infer_pos 1;
BA_ "ECGUsedRxSignal" SG_ 1123 GPS_Actual_vs_Infer_pos 1;
BA_ "U_CD542_MY2021_Rx" SG_ 1123 GPS_Actual_vs_Infer_pos 1;
BA_ "U_U55X_MY2022_Rx" SG_ 1123 GPS_Actual_vs_Infer_pos 1;
BA_ "U_CD542_MY2021_Tx" SG_ 1123 GPS_Actual_vs_Infer_pos 1;
BA_ "U_U55X_MY2022_Tx" SG_ 1123 GPS_Actual_vs_Infer_pos 1;
BA_ "U_P702_MY2021_Tx" SG_ 1123 GPS_Actual_vs_Infer_pos 1;
BA_ "U_T6_MCA_MY2020_Tx" SG_ 1123 GPS_Actual_vs_Infer_pos 1;
BA_ "U_T6_MCA_MY2020_Rx" SG_ 1123 Gps_B_Falt 1;
BA_ "ECGUsedRxSignal" SG_ 1123 Gps_B_Falt 1;
BA_ "U_CD542_MY2021_Rx" SG_ 1123 Gps_B_Falt 1;
BA_ "U_U55X_MY2022_Rx" SG_ 1123 Gps_B_Falt 1;
BA_ "U_CD542_MY2021_Tx" SG_ 1123 Gps_B_Falt 1;
BA_ "U_U55X_MY2022_Tx" SG_ 1123 Gps_B_Falt 1;
BA_ "U_P702_MY2021_Tx" SG_ 1123 Gps_B_Falt 1;
BA_ "U_T6_MCA_MY2020_Tx" SG_ 1123 Gps_B_Falt 1;
BA_ "GenSigSendType" SG_ 1122 GpsHsphLongEast_D_Actl 1;
BA_ "U_T6_MCA_MY2020_Rx" SG_ 1122 GpsHsphLongEast_D_Actl 1;
BA_ "ECGUsedRxSignal" SG_ 1122 GpsHsphLongEast_D_Actl 1;
BA_ "U_CD542_MY2021_Rx" SG_ 1122 GpsHsphLongEast_D_Actl 1;
BA_ "U_U55X_MY2022_Rx" SG_ 1122 GpsHsphLongEast_D_Actl 1;
BA_ "U_CD542_MY2021_Tx" SG_ 1122 GpsHsphLongEast_D_Actl 1;
BA_ "U_U55X_MY2022_Tx" SG_ 1122 GpsHsphLongEast_D_Actl 1;
BA_ "U_P702_MY2021_Tx" SG_ 1122 GpsHsphLongEast_D_Actl 1;
BA_ "U_T6_MCA_MY2020_Tx" SG_ 1122 GpsHsphLongEast_D_Actl 1;
BA_ "U_T6_MCA_MY2020_Rx" SG_ 1122 GpsHsphLattSth_D_Actl 1;
BA_ "ECGUsedRxSignal" SG_ 1122 GpsHsphLattSth_D_Actl 1;
BA_ "U_CD542_MY2021_Rx" SG_ 1122 GpsHsphLattSth_D_Actl 1;
BA_ "U_U55X_MY2022_Rx" SG_ 1122 GpsHsphLattSth_D_Actl 1;
BA_ "U_CD542_MY2021_Tx" SG_ 1122 GpsHsphLattSth_D_Actl 1;
BA_ "U_U55X_MY2022_Tx" SG_ 1122 GpsHsphLattSth_D_Actl 1;
BA_ "U_P702_MY2021_Tx" SG_ 1122 GpsHsphLattSth_D_Actl 1;
BA_ "U_T6_MCA_MY2020_Tx" SG_ 1122 GpsHsphLattSth_D_Actl 1;
BA_ "U_T6_MCA_MY2020_Rx" SG_ 1122 GPS_Longitude_Minutes 1;
BA_ "ECGUsedRxSignal" SG_ 1122 GPS_Longitude_Minutes 1;
BA_ "U_CD542_MY2021_Rx" SG_ 1122 GPS_Longitude_Minutes 1;
BA_ "U_U55X_MY2022_Rx" SG_ 1122 GPS_Longitude_Minutes 1;
BA_ "U_CD542_MY2021_Tx" SG_ 1122 GPS_Longitude_Minutes 1;
BA_ "U_U55X_MY2022_Tx" SG_ 1122 GPS_Longitude_Minutes 1;
BA_ "U_P702_MY2021_Tx" SG_ 1122 GPS_Longitude_Minutes 1;
BA_ "U_T6_MCA_MY2020_Tx" SG_ 1122 GPS_Longitude_Minutes 1;
BA_ "U_T6_MCA_MY2020_Rx" SG_ 1122 GPS_Longitude_Min_dec 1;
BA_ "ECGUsedRxSignal" SG_ 1122 GPS_Longitude_Min_dec 1;
BA_ "U_CD542_MY2021_Rx" SG_ 1122 GPS_Longitude_Min_dec 1;
BA_ "U_U55X_MY2022_Rx" SG_ 1122 GPS_Longitude_Min_dec 1;
BA_ "U_CD542_MY2021_Tx" SG_ 1122 GPS_Longitude_Min_dec 1;
BA_ "U_U55X_MY2022_Tx" SG_ 1122 GPS_Longitude_Min_dec 1;
BA_ "U_P702_MY2021_Tx" SG_ 1122 GPS_Longitude_Min_dec 1;
BA_ "U_T6_MCA_MY2020_Tx" SG_ 1122 GPS_Longitude_Min_dec 1;
BA_ "GenSigStartValueInteger" SG_ 1122 GPS_Longitude_Degrees 179;
BA_ "U_T6_MCA_MY2020_Rx" SG_ 1122 GPS_Longitude_Degrees 1;
BA_ "ECGUsedRxSignal" SG_ 1122 GPS_Longitude_Degrees 1;
BA_ "U_CD542_MY2021_Rx" SG_ 1122 GPS_Longitude_Degrees 1;
BA_ "U_U55X_MY2022_Rx" SG_ 1122 GPS_Longitude_Degrees 1;
BA_ "U_CD542_MY2021_Tx" SG_ 1122 GPS_Longitude_Degrees 1;
BA_ "U_U55X_MY2022_Tx" SG_ 1122 GPS_Longitude_Degrees 1;
BA_ "U_P702_MY2021_Tx" SG_ 1122 GPS_Longitude_Degrees 1;
BA_ "U_T6_MCA_MY2020_Tx" SG_ 1122 GPS_Longitude_Degrees 1;
BA_ "U_T6_MCA_MY2020_Rx" SG_ 1122 GPS_Latitude_Minutes 1;
BA_ "ECGUsedRxSignal" SG_ 1122 GPS_Latitude_Minutes 1;
BA_ "U_CD542_MY2021_Rx" SG_ 1122 GPS_Latitude_Minutes 1;
BA_ "U_U55X_MY2022_Rx" SG_ 1122 GPS_Latitude_Minutes 1;
BA_ "U_CD542_MY2021_Tx" SG_ 1122 GPS_Latitude_Minutes 1;
BA_ "U_U55X_MY2022_Tx" SG_ 1122 GPS_Latitude_Minutes 1;
BA_ "U_P702_MY2021_Tx" SG_ 1122 GPS_Latitude_Minutes 1;
BA_ "U_T6_MCA_MY2020_Tx" SG_ 1122 GPS_Latitude_Minutes 1;
BA_ "U_T6_MCA_MY2020_Rx" SG_ 1122 GPS_Latitude_Min_dec 1;
BA_ "ECGUsedRxSignal" SG_ 1122 GPS_Latitude_Min_dec 1;
BA_ "U_CD542_MY2021_Rx" SG_ 1122 GPS_Latitude_Min_dec 1;
BA_ "U_U55X_MY2022_Rx" SG_ 1122 GPS_Latitude_Min_dec 1;
BA_ "U_CD542_MY2021_Tx" SG_ 1122 GPS_Latitude_Min_dec 1;
BA_ "U_U55X_MY2022_Tx" SG_ 1122 GPS_Latitude_Min_dec 1;
BA_ "U_P702_MY2021_Tx" SG_ 1122 GPS_Latitude_Min_dec 1;
BA_ "U_T6_MCA_MY2020_Tx" SG_ 1122 GPS_Latitude_Min_dec 1;
BA_ "U_T6_MCA_MY2020_Rx" SG_ 1122 GPS_Latitude_Degrees 1;
BA_ "ECGUsedRxSignal" SG_ 1122 GPS_Latitude_Degrees 1;
BA_ "U_CD542_MY2021_Rx" SG_ 1122 GPS_Latitude_Degrees 1;
BA_ "U_U55X_MY2022_Rx" SG_ 1122 GPS_Latitude_Degrees 1;
BA_ "U_CD542_MY2021_Tx" SG_ 1122 GPS_Latitude_Degrees 1;
BA_ "U_U55X_MY2022_Tx" SG_ 1122 GPS_Latitude_Degrees 1;
BA_ "U_P702_MY2021_Tx" SG_ 1122 GPS_Latitude_Degrees 1;
BA_ "U_T6_MCA_MY2020_Tx" SG_ 1122 GPS_Latitude_Degrees 1;
BA_ "U_P702_MY2021_Rx" SG_ 1131 EsaOn_B_Stat_UB 1;
BA_ "U_T6_MCA_MY2020_Rx" SG_ 1131 EsaOn_B_Stat_UB 1;
BA_ "U_CD542_MY2021_Rx" SG_ 1131 EsaOn_B_Stat_UB 1;
BA_ "U_U55X_MY2022_Rx" SG_ 1131 EsaOn_B_Stat_UB 1;
BA_ "GenSigStartValueInteger" SG_ 1131 EsaOn_B_Stat 1;
BA_ "GenSigStartValue" SG_ 1131 EsaOn_B_Stat 1;
BA_ "GenSigSendType" SG_ 1131 EsaOn_B_Stat 3;
BA_ "U_P702_MY2021_Rx" SG_ 1131 EsaOn_B_Stat 1;
BA_ "U_T6_MCA_MY2020_Rx" SG_ 1131 EsaOn_B_Stat 1;
BA_ "U_CD542_MY2021_Rx" SG_ 1131 EsaOn_B_Stat 1;
BA_ "U_U55X_MY2022_Rx" SG_ 1131 EsaOn_B_Stat 1;
BA_ "GenSigStartValueInteger" SG_ 1131 WiprFrontSwtch_D_Stat 9;
BA_ "GenSigStartValue" SG_ 1131 WiprFrontSwtch_D_Stat 9;
BA_ "GenSigSendType" SG_ 1131 WiprFrontSwtch_D_Stat 3;
BA_ "U_U55X_MY2022_Rx" SG_ 1131 WiprFrontSwtch_D_Stat 1;
BA_ "U_P702_MY2021_Rx" SG_ 1131 HeadLghtHiOn_B_StatAhb_UB 1;
BA_ "U_T6_MCA_MY2020_Rx" SG_ 1131 HeadLghtHiOn_B_StatAhb_UB 1;
BA_ "U_CD542_MY2021_Rx" SG_ 1131 HeadLghtHiOn_B_StatAhb_UB 1;
BA_ "U_U55X_MY2022_Rx" SG_ 1131 HeadLghtHiOn_B_StatAhb_UB 1;
BA_ "WakeupSignal" SG_ 1131 HeadLghtHiOn_B_StatAhb 1;
BA_ "GenSigSendType" SG_ 1131 HeadLghtHiOn_B_StatAhb 3;
BA_ "U_P702_MY2021_Rx" SG_ 1131 HeadLghtHiOn_B_StatAhb 1;
BA_ "U_T6_MCA_MY2020_Rx" SG_ 1131 HeadLghtHiOn_B_StatAhb 1;
BA_ "U_CD542_MY2021_Rx" SG_ 1131 HeadLghtHiOn_B_StatAhb 1;
BA_ "U_U55X_MY2022_Rx" SG_ 1131 HeadLghtHiOn_B_StatAhb 1;
BA_ "U_P702_MY2021_Rx" SG_ 1131 AhbStat_B_Dsply_UB 1;
BA_ "U_T6_MCA_MY2020_Rx" SG_ 1131 AhbStat_B_Dsply_UB 1;
BA_ "U_CD542_MY2021_Rx" SG_ 1131 AhbStat_B_Dsply_UB 1;
BA_ "U_U55X_MY2022_Rx" SG_ 1131 AhbStat_B_Dsply_UB 1;
BA_ "GenSigSendType" SG_ 1131 AhbStat_B_Dsply 3;
BA_ "U_P702_MY2021_Rx" SG_ 1131 AhbStat_B_Dsply 1;
BA_ "U_T6_MCA_MY2020_Rx" SG_ 1131 AhbStat_B_Dsply 1;
BA_ "U_CD542_MY2021_Rx" SG_ 1131 AhbStat_B_Dsply 1;
BA_ "U_U55X_MY2022_Rx" SG_ 1131 AhbStat_B_Dsply 1;
BA_ "U_U55X_MY2022_Rx" SG_ 1131 WiprFrontSwtch_D_Stat_UB 1;
BA_ "U_P702_MY2021_Rx" SG_ 1131 RearDiffSrvcRqd_B_Rq_UB 1;
BA_ "U_T6_MCA_MY2020_Rx" SG_ 1131 RearDiffSrvcRqd_B_Rq_UB 1;
BA_ "U_CD542_MY2021_Rx" SG_ 1131 RearDiffSrvcRqd_B_Rq_UB 1;
BA_ "U_U55X_MY2022_Rx" SG_ 1131 RearDiffSrvcRqd_B_Rq_UB 1;
BA_ "U_P702_MY2021_Rx" SG_ 1131 PtLatchActv_B_RqBcm_UB 1;
BA_ "U_T6_MCA_MY2020_Rx" SG_ 1131 PtLatchActv_B_RqBcm_UB 1;
BA_ "U_CD542_MY2021_Rx" SG_ 1131 PtLatchActv_B_RqBcm_UB 1;
BA_ "U_U55X_MY2022_Rx" SG_ 1131 PtLatchActv_B_RqBcm_UB 1;
BA_ "U_P702_MY2021_Rx" SG_ 1131 RearDiffSrvcRqd_B_Rq 1;
BA_ "U_T6_MCA_MY2020_Rx" SG_ 1131 RearDiffSrvcRqd_B_Rq 1;
BA_ "U_CD542_MY2021_Rx" SG_ 1131 RearDiffSrvcRqd_B_Rq 1;
BA_ "U_U55X_MY2022_Rx" SG_ 1131 RearDiffSrvcRqd_B_Rq 1;
BA_ "GenSigSendType" SG_ 1131 PtLatchActv_B_RqBcm 3;
BA_ "U_P702_MY2021_Rx" SG_ 1131 PtLatchActv_B_RqBcm 1;
BA_ "U_T6_MCA_MY2020_Rx" SG_ 1131 PtLatchActv_B_RqBcm 1;
BA_ "U_CD542_MY2021_Rx" SG_ 1131 PtLatchActv_B_RqBcm 1;
BA_ "U_U55X_MY2022_Rx" SG_ 1131 PtLatchActv_B_RqBcm 1;
BA_ "U_P702_MY2021_Rx" SG_ 1136 ActvFrontSteMsgTxt_D_Rq_UB 1;
BA_ "U_T6_MCA_MY2020_Rx" SG_ 1136 ActvFrontSteMsgTxt_D_Rq_UB 1;
BA_ "U_U55X_MY2022_Rx" SG_ 1136 ActvFrontSteMsgTxt_D_Rq_UB 1;
BA_ "U_P702_MY2021_Rx" SG_ 1136 ActvFrontSteMsgTxt_D_Rq 1;
BA_ "U_T6_MCA_MY2020_Rx" SG_ 1136 ActvFrontSteMsgTxt_D_Rq 1;
BA_ "U_U55X_MY2022_Rx" SG_ 1136 ActvFrontSteMsgTxt_D_Rq 1;
BA_ "U_T6_MCA_MY2020_Rx" SG_ 1136 GboxOil_Te_Actl_UB 1;
BA_ "U_CD542_MY2021_Rx" SG_ 1136 GboxOil_Te_Actl_UB 1;
BA_ "U_U55X_MY2022_Rx" SG_ 1136 GboxOil_Te_Actl_UB 1;
BA_ "U_P702_MY2021_Rx" SG_ 1136 GboxOil_Te_Actl_UB 1;
BA_ "GenSigStartValueInteger" SG_ 1136 GboxOil_Te_Actl 254;
BA_ "ContentDependant" SG_ 1136 GboxOil_Te_Actl 1;
BA_ "GenSigStartValue" SG_ 1136 GboxOil_Te_Actl 254;
BA_ "U_P702_MY2021_Rx" SG_ 1136 GboxOil_Te_Actl 1;
BA_ "U_T6_MCA_MY2020_Rx" SG_ 1136 GboxOil_Te_Actl 1;
BA_ "U_U55X_MY2022_Rx" SG_ 1136 GboxOil_Te_Actl 1;
BA_ "U_CD542_MY2021_Rx" SG_ 1136 GboxOil_Te_Actl 1;
BA_ "U_P702_MY2021_Rx" SG_ 1136 EngOff_T_Actl_UB 1;
BA_ "U_T6_MCA_MY2020_Rx" SG_ 1136 EngOff_T_Actl_UB 1;
BA_ "U_U55X_MY2022_Rx" SG_ 1136 EngOff_T_Actl_UB 1;
BA_ "U_P702_MY2021_Rx" SG_ 1136 EngOff_T_Actl 1;
BA_ "U_T6_MCA_MY2020_Rx" SG_ 1136 EngOff_T_Actl 1;
BA_ "U_U55X_MY2022_Rx" SG_ 1136 EngOff_T_Actl 1;
BA_ "GenSigStartValueInteger" SG_ 1136 BrkLineLck_D_Stat 4;
BA_ "GenSigStartValue" SG_ 1136 BrkLineLck_D_Stat 4;
BA_ "U_P702_MY2021_Rx" SG_ 1136 SnowPlowMde_B_Enbl 1;
BA_ "U_T6_MCA_MY2020_Rx" SG_ 1136 SnowPlowMde_B_Enbl 1;
BA_ "U_U55X_MY2022_Rx" SG_ 1136 SnowPlowMde_B_Enbl 1;
BA_ "U_P702_MY2021_Rx" SG_ 1136 SnowPlowMde_B_Enbl_UB 1;
BA_ "U_T6_MCA_MY2020_Rx" SG_ 1136 SnowPlowMde_B_Enbl_UB 1;
BA_ "U_U55X_MY2022_Rx" SG_ 1136 SnowPlowMde_B_Enbl_UB 1;
BA_ "U_T6_MCA_MY2020_Rx" SG_ 1106 TrlrSnsId_No_Actl 1;
BA_ "U_U55X_MY2022_Rx" SG_ 1106 TrlrSnsId_No_Actl 1;
BA_ "U_CD542_MY2021_Rx" SG_ 1106 TrlrSnsId_No_Actl 1;
BA_ "U_T6_MCA_MY2020_Rx" SG_ 1086 EngOil_P_Actl 1;
BA_ "U_P702_MY2021_Rx" SG_ 1086 EngOil_P_Actl 1;
BA_ "U_CD542_MY2021_Rx" SG_ 1086 EngOil_P_Actl 1;
BA_ "U_U55X_MY2022_Rx" SG_ 1086 EngOil_P_Actl 1;
BA_ "GenSigStartValueInteger" SG_ 1086 EngMnfld_P_Actl 2068;
BA_ "U_P702_MY2021_Rx" SG_ 1086 EngMnfld_P_Actl 1;
BA_ "U_T6_MCA_MY2020_Rx" SG_ 1086 EngMnfld_P_Actl 1;
BA_ "U_U55X_MY2022_Rx" SG_ 1086 EngMnfld_P_Actl 1;
BA_ "U_CD542_MY2021_Rx" SG_ 1086 EngMnfld_P_Actl 1;
BA_ "U_T6_MCA_MY2020_Rx" SG_ 1086 EngIpcDsplyAfr_Rt_Actl 1;
BA_ "GenSigStartValueInteger" SG_ 1086 EngIpcDsplyCht_Te_Actl 75;
BA_ "GenSigStartValue" SG_ 1086 EngIpcDsplyCht_Te_Actl 75;
BA_ "GenSigStartValueInteger" SG_ 1086 AwdPtu_Te_Actl 50;
BA_ "U_T6_MCA_MY2020_Rx" SG_ 1086 FuelPumpPwr_B_Rq 1;
BA_ "U_T6_MCA_MY2020_Rx" SG_ 1086 BattULoChrg_U_Cmd 1;
BA_ "ContentDependant" SG_ 1086 ElLoadCtl_D_Rq 1;
BA_ "U_T6_MCA_MY2020_Rx" SG_ 1086 ElLoadCtl_D_Rq 1;
BA_ "WakeupSignal" SG_ 817 DrTgateOpen_B_Rq 1;
BA_ "WakeupSignal" SG_ 817 DrTgateExtSwMde_B_Stat 1;
BA_ "WakeupSignal" SG_ 817 Remote_Device_Feedback 1;
BA_ "WakeupSignal" SG_ 817 Veh_Lock_Requestor 1;
BA_ "U_T6_MCA_MY2020_Rx" SG_ 817 Veh_Lock_Requestor 1;
BA_ "U_U55X_MY2022_Rx" SG_ 817 Veh_Lock_Requestor 1;
BA_ "U_CD542_MY2021_Rx" SG_ 817 Veh_Lock_Requestor 1;
BA_ "WakeupSignal" SG_ 817 R_Pwr_Sliding_Dr_Rqst 1;
BA_ "WakeupSignal" SG_ 817 Power_Liftgate_Rqst 1;
BA_ "WakeupSignal" SG_ 817 Veh_Lock_EvNum 1;
BA_ "U_T6_MCA_MY2020_Rx" SG_ 817 Veh_Lock_EvNum 1;
BA_ "U_CD542_MY2021_Rx" SG_ 817 Veh_Lock_EvNum 1;
BA_ "U_U55X_MY2022_Rx" SG_ 817 Veh_Lock_EvNum 1;
BA_ "WakeupSignal" SG_ 817 Power_Decklid_Rqst 1;
BA_ "WakeupSignal" SG_ 817 L_Pwr_Sliding_Dr_Rqst 1;
BA_ "WakeupSignal" SG_ 817 Keyfob_Pad_Msg_Count 1;
BA_ "WakeupSignal" SG_ 817 Veh_Lock_Status 1;
BA_ "GenSigStartValueInteger" SG_ 817 Veh_Lock_Status 1;
BA_ "GenSigStartValue" SG_ 817 Veh_Lock_Status 1;
BA_ "U_T6_MCA_MY2020_Rx" SG_ 817 Veh_Lock_Status 1;
BA_ "U_CD542_MY2021_Rx" SG_ 817 Veh_Lock_Status 1;
BA_ "U_U55X_MY2022_Rx" SG_ 817 Veh_Lock_Status 1;
BA_ "U_P702_MY2021_Rx" SG_ 817 Veh_Lock_Status 1;
BA_ "WakeupSignal" SG_ 817 ChildLck_D_Dsply 1;
BA_ "GenSigStartValueInteger" SG_ 817 ChildLck_D_Dsply 1;
BA_ "GenSigStartValue" SG_ 817 ChildLck_D_Dsply 1;
BA_ "U_U55X_MY2022_Rx" SG_ 817 WindowLockout_B_Stat 1;
BA_ "U_T6_MCA_MY2020_Rx" SG_ 817 RollCodeUnlock 1;
BA_ "U_CD542_MY2021_Rx" SG_ 817 RollCodeUnlock 1;
BA_ "WakeupSignal" SG_ 817 Lockmsgtxt_D_Rq 1;
BA_ "U_P702_MY2021_Rx" SG_ 817 Lockmsgtxt_D_Rq 1;
BA_ "U_T6_MCA_MY2020_Rx" SG_ 817 Lockmsgtxt_D_Rq 1;
BA_ "U_CD542_MY2021_Rx" SG_ 817 Lockmsgtxt_D_Rq 1;
BA_ "U_U55X_MY2022_Rx" SG_ 817 Lockmsgtxt_D_Rq 1;
BA_ "WakeupSignal" SG_ 817 LockInhibit 1;
BA_ "U_T6_MCA_MY2020_Rx" SG_ 817 LockInhibit 1;
BA_ "U_U55X_MY2022_Rx" SG_ 817 LockInhibit 1;
BA_ "U_T6_MCA_MY2020_Rx" SG_ 611 AwdTerrMdeChng_D_Rdy 1;
BA_ "U_T6_MCA_MY2020_Rx" SG_ 611 AwdTerrMde_D_Actl 1;
BA_ "U_T6_MCA_MY2020_Rx" SG_ 611 AwdSys_D_Stat 1;
BA_ "ContentDependant" SG_ 611 AwdStat_D_RqDsply 1;
BA_ "U_P702_MY2021_Rx" SG_ 611 AwdStat_D_RqDsply 1;
BA_ "U_T6_MCA_MY2020_Rx" SG_ 611 AwdStat_D_RqDsply 1;
BA_ "U_CD542_MY2021_Rx" SG_ 611 AwdStat_D_RqDsply 1;
BA_ "U_U55X_MY2022_Rx" SG_ 611 AwdStat_D_RqDsply 1;
BA_ "U_P702_MY2021_Rx" SG_ 611 AwdLck_D_Stat 1;
BA_ "U_T6_MCA_MY2020_Rx" SG_ 611 AwdLck_D_Stat 1;
BA_ "U_U55X_MY2022_Rx" SG_ 611 AwdLck_D_Stat 1;
BA_ "ContentDependant" SG_ 611 AwdSrvcRqd_B_Rq 1;
BA_ "U_P702_MY2021_Rx" SG_ 611 AwdSrvcRqd_B_Rq 1;
BA_ "U_T6_MCA_MY2020_Rx" SG_ 611 AwdSrvcRqd_B_Rq 1;
BA_ "U_CD542_MY2021_Rx" SG_ 611 AwdSrvcRqd_B_Rq 1;
BA_ "U_U55X_MY2022_Rx" SG_ 611 AwdSrvcRqd_B_Rq 1;
BA_ "ContentDependant" SG_ 611 AwdLck_Tq_Rq 1;
BA_ "U_P702_MY2021_Rx" SG_ 611 AwdLck_Tq_Rq 1;
BA_ "U_T6_MCA_MY2020_Rx" SG_ 611 AwdLck_Tq_Rq 1;
BA_ "U_U55X_MY2022_Rx" SG_ 611 AwdLck_Tq_Rq 1;
BA_ "GenSigStartValueInteger" SG_ 611 TrnAout_Tq_RqMx 8191;
BA_ "GenSigStartValue" SG_ 611 TrnAout_Tq_RqMx 8191;
BA_ "U_T6_MCA_MY2020_Rx" SG_ 611 TrnAout_Tq_RqMx 1;
BA_ "U_CD542_MY2021_Rx" SG_ 611 AwdOffRoadMode_D_Stats 1;
BA_ "U_P702_MY2021_Rx" SG_ 611 AwdOffRoadMode_D_Stats 1;
BA_ "U_T6_MCA_MY2020_Rx" SG_ 611 AwdOffRoadMode_D_Stats 1;
BA_ "U_U55X_MY2022_Rx" SG_ 611 AwdOffRoadMode_D_Stats 1;
BA_ "U_P702_MY2021_Rx" SG_ 611 AwdLoLamp_D_RqDsply 1;
BA_ "U_T6_MCA_MY2020_Rx" SG_ 611 AwdLoLamp_D_RqDsply 1;
BA_ "U_U55X_MY2022_Rx" SG_ 611 AwdLoLamp_D_RqDsply 1;
BA_ "U_P702_MY2021_Rx" SG_ 611 AwdHiLamp_D_RqDsply 1;
BA_ "U_T6_MCA_MY2020_Rx" SG_ 611 AwdHiLamp_D_RqDsply 1;
BA_ "U_U55X_MY2022_Rx" SG_ 611 AwdHiLamp_D_RqDsply 1;
BA_ "U_P702_MY2021_Rx" SG_ 611 AwdAutoLamp_D_RqDsply 1;
BA_ "U_T6_MCA_MY2020_Rx" SG_ 611 AwdAutoLamp_D_RqDsply 1;
BA_ "U_U55X_MY2022_Rx" SG_ 611 AwdAutoLamp_D_RqDsply 1;
BA_ "U_P702_MY2021_Rx" SG_ 611 Awd2wdLamp_D_RqDsply 1;
BA_ "U_T6_MCA_MY2020_Rx" SG_ 611 Awd2wdLamp_D_RqDsply 1;
BA_ "U_U55X_MY2022_Rx" SG_ 611 Awd2wdLamp_D_RqDsply 1;
BA_ "GenSigStartValueInteger" SG_ 611 AwdRnge_D_Actl 7;
BA_ "GenSigStartValue" SG_ 611 AwdRnge_D_Actl 7;
BA_ "U_P702_MY2021_Rx" SG_ 611 AwdRnge_D_Actl 1;
BA_ "U_T6_MCA_MY2020_Rx" SG_ 611 AwdRnge_D_Actl 1;
BA_ "U_U55X_MY2022_Rx" SG_ 611 AwdRnge_D_Actl 1;
BA_ "U_CD542_MY2021_Rx" SG_ 611 AwdRnge_D_Actl 1;
BA_ "U_P702_MY2021_Rx" SG_ 611 NtrlTowAvail_B_Stat 1;
BA_ "U_T6_MCA_MY2020_Rx" SG_ 611 NtrlTowAvail_B_Stat 1;
BA_ "U_U55X_MY2022_Rx" SG_ 611 NtrlTowAvail_B_Stat 1;
BA_ "U_T6_MCA_MY2020_Rx" SG_ 611 AwdDrvMde_D_Stat 1;
BA_ "U_T6_MCA_MY2020_Rx" SG_ 264 CabnAmb_Te_Actl_UB 1;
BA_ "U_U55X_MY2022_Rx" SG_ 264 CabnAmb_Te_Actl_UB 1;
BA_ "U_CD542_MY2021_Rx" SG_ 264 CabnAmb_Te_Actl_UB 1;
BA_ "GenSigStartValueInteger" SG_ 264 CabnAmb_Te_Actl 114;
BA_ "U_T6_MCA_MY2020_Rx" SG_ 264 CabnAmb_Te_Actl 1;
BA_ "U_CD542_MY2021_Rx" SG_ 264 CabnAmb_Te_Actl 1;
BA_ "U_U55X_MY2022_Rx" SG_ 264 CabnAmb_Te_Actl 1;
BA_ "U_P702_MY2021_Rx" SG_ 264 ChrgCordLck_D_Stat_UB 1;
BA_ "U_T6_MCA_MY2020_Rx" SG_ 264 ChrgCordLck_D_Stat_UB 1;
BA_ "U_U55X_MY2022_Rx" SG_ 264 ChrgCordLck_D_Stat_UB 1;
BA_ "U_CD542_MY2021_Rx" SG_ 264 ChrgCordLck_D_Stat_UB 1;
BA_ "U_P702_MY2021_Rx" SG_ 264 ChrgCordLck_D_Stat 1;
BA_ "U_T6_MCA_MY2020_Rx" SG_ 264 ChrgCordLck_D_Stat 1;
BA_ "U_U55X_MY2022_Rx" SG_ 264 ChrgCordLck_D_Stat 1;
BA_ "U_CD542_MY2021_Rx" SG_ 264 ChrgCordLck_D_Stat 1;
BA_ "U_P702_MY2021_Rx" SG_ 264 PwPckTqRdy_B_Dsply 1;
BA_ "U_T6_MCA_MY2020_Rx" SG_ 264 PwPckTqRdy_B_Dsply 1;
BA_ "U_CD542_MY2021_Rx" SG_ 264 PwPckTqRdy_B_Dsply 1;
BA_ "U_U55X_MY2022_Rx" SG_ 264 PwPckTqRdy_B_Dsply 1;
BA_ "U_P702_MY2021_Rx" SG_ 264 HtrnOvrTeLamp_B_Dsply_UB 1;
BA_ "U_T6_MCA_MY2020_Rx" SG_ 264 HtrnOvrTeLamp_B_Dsply_UB 1;
BA_ "U_CD542_MY2021_Rx" SG_ 264 HtrnOvrTeLamp_B_Dsply_UB 1;
BA_ "U_P702_MY2021_Rx" SG_ 264 HtrnOvrTeLamp_B_Dsply 1;
BA_ "U_T6_MCA_MY2020_Rx" SG_ 264 HtrnOvrTeLamp_B_Dsply 1;
BA_ "U_CD542_MY2021_Rx" SG_ 264 HtrnOvrTeLamp_B_Dsply 1;
BA_ "U_P702_MY2021_Rx" SG_ 264 PwPckTqRdy_B_Dsply_UB 1;
BA_ "U_T6_MCA_MY2020_Rx" SG_ 264 PwPckTqRdy_B_Dsply_UB 1;
BA_ "U_U55X_MY2022_Rx" SG_ 264 PwPckTqRdy_B_Dsply_UB 1;
BA_ "U_CD542_MY2021_Rx" SG_ 264 PwPckTqRdy_B_Dsply_UB 1;
BA_ "GenSigStartValueInteger" SG_ 264 BpedDrvAppl_D_Actl 1;
BA_ "GenSigStartValue" SG_ 264 BpedDrvAppl_D_Actl 1;
BA_ "GenSigSendType" SG_ 264 BpedDrvAppl_D_Actl 3;
BA_ "U_P702_MY2021_Rx" SG_ 264 BpedDrvAppl_D_Actl 1;
BA_ "U_T6_MCA_MY2020_Rx" SG_ 264 BpedDrvAppl_D_Actl 1;
BA_ "U_CD542_MY2021_Rx" SG_ 264 BpedDrvAppl_D_Actl 1;
BA_ "U_U55X_MY2022_Rx" SG_ 264 BpedDrvAppl_D_Actl 1;
BA_ "U_P702_MY2021_Rx" SG_ 264 BpedDrvAppl_D_Actl_UB 1;
BA_ "U_T6_MCA_MY2020_Rx" SG_ 264 BpedDrvAppl_D_Actl_UB 1;
BA_ "U_CD542_MY2021_Rx" SG_ 264 BpedDrvAppl_D_Actl_UB 1;
BA_ "U_U55X_MY2022_Rx" SG_ 264 BpedDrvAppl_D_Actl_UB 1;
BA_ "U_P702_MY2021_Rx" SG_ 264 BattTracSoc_Pc_Dsply_UB 1;
BA_ "U_T6_MCA_MY2020_Rx" SG_ 264 BattTracSoc_Pc_Dsply_UB 1;
BA_ "U_CD542_MY2021_Rx" SG_ 264 BattTracSoc_Pc_Dsply_UB 1;
BA_ "U_U55X_MY2022_Rx" SG_ 264 BattTracSoc_Pc_Dsply_UB 1;
BA_ "GenSigStartValueInteger" SG_ 264 BattTracSoc_Pc_Dsply 254;
BA_ "GenSigStartValue" SG_ 264 BattTracSoc_Pc_Dsply 254;
BA_ "U_P702_MY2021_Rx" SG_ 264 BattTracSoc_Pc_Dsply 1;
BA_ "U_T6_MCA_MY2020_Rx" SG_ 264 BattTracSoc_Pc_Dsply 1;
BA_ "U_CD542_MY2021_Rx" SG_ 264 BattTracSoc_Pc_Dsply 1;
BA_ "U_U55X_MY2022_Rx" SG_ 264 BattTracSoc_Pc_Dsply 1;
BA_ "GenSigSendType" SG_ 1114 TrailCtlSwtch_B_Stat2 3;
BA_ "U_P702_MY2021_Tx" SG_ 1114 TrailCtlSwtch_B_Stat2 1;
BA_ "U_U55X_MY2022_Tx" SG_ 1114 TrailCtlSwtch_B_Stat2 1;
BA_ "GenSigSendType" SG_ 1114 TrlBrkInitOut_D_Rq 3;
BA_ "U_P702_MY2021_Rx" SG_ 1114 TrlBrkInitOut_D_Rq 1;
BA_ "U_T6_MCA_MY2020_Rx" SG_ 1114 TrlBrkInitOut_D_Rq 1;
BA_ "U_U55X_MY2022_Rx" SG_ 1114 TrlBrkInitOut_D_Rq 1;
BA_ "U_U55X_MY2022_Tx" SG_ 1114 TrlBrkInitOut_D_Rq 1;
BA_ "GenSigSendType" SG_ 968 RvltnMatchAllw_D_Rq 3;
BA_ "U_T6_MCA_MY2020_Tx" SG_ 968 RvltnMatchAllw_D_Rq 1;
BA_ "U_CD542_MY2021_Tx" SG_ 968 RvltnMatchAllw_D_Rq 1;
BA_ "GenSigSendType" SG_ 968 BrkDrvMde_D_Rq 3;
BA_ "U_T6_MCA_MY2020_Tx" SG_ 968 BrkDrvMde_D_Rq 1;
BA_ "U_CD542_MY2021_Tx" SG_ 968 BrkDrvMde_D_Rq 1;
BA_ "GenSigSendType" SG_ 968 LnchCtl_N_Rq 3;
BA_ "GenSigSendType" SG_ 968 LnchCtl_D_Rq 3;
BA_ "GenSigStartValueInteger" SG_ 968 CurrentColor_CmdGage 8;
BA_ "GenSigStartValue" SG_ 968 CurrentColor_CmdGage 8;
BA_ "GenSigSendType" SG_ 968 CurrentColor_CmdGage 3;
BA_ "GenSigStartValueInteger" SG_ 968 BlendedColor_CmdGage 2;
BA_ "GenSigStartValue" SG_ 968 BlendedColor_CmdGage 2;
BA_ "GenSigSendType" SG_ 968 BlendedColor_CmdGage 3;
BA_ "GenSigSendType" SG_ 968 BlendColorRed_CmdGage 3;
BA_ "GenSigSendType" SG_ 968 BlendColorGrn_CmdGage 3;
BA_ "GenSigSendType" SG_ 968 BlendColorBlue_CmdGage 3;
BA_ "GenSigSendType" SG_ 968 Dimming_Level_Cmd 3;
BA_ "GenSigStartValueInteger" SG_ 968 Current_Color_Cmd 8;
BA_ "GenSigStartValue" SG_ 968 Current_Color_Cmd 8;
BA_ "GenSigSendType" SG_ 968 Current_Color_Cmd 3;
BA_ "GenSigSendType" SG_ 968 BlendedColorRed_Cmd 3;
BA_ "GenSigSendType" SG_ 968 BlendedColorGreen_Cmd 3;
BA_ "GenSigSendType" SG_ 968 BlendedColorBlue_Cmd 3;
BA_ "GenSigStartValueInteger" SG_ 968 BlendedColor_Cmd 2;
BA_ "GenSigStartValue" SG_ 968 BlendedColor_Cmd 2;
BA_ "GenSigSendType" SG_ 968 BlendedColor_Cmd 3;
BA_ "GenSigSendType" SG_ 968 SuspDrvMde_D_Rq 3;
BA_ "U_T6_MCA_MY2020_Tx" SG_ 968 SuspDrvMde_D_Rq 1;
BA_ "GenSigStartValueInteger" SG_ 968 SlMde_D_Rq 2;
BA_ "GenSigStartValue" SG_ 968 SlMde_D_Rq 2;
BA_ "GenSigSendType" SG_ 968 SlMde_D_Rq 3;
BA_ "U_P702_MY2021_Tx" SG_ 968 SlMde_D_Rq 1;
BA_ "U_T6_MCA_MY2020_Tx" SG_ 968 SlMde_D_Rq 1;
BA_ "U_CD542_MY2021_Tx" SG_ 968 SlMde_D_Rq 1;
BA_ "U_U55X_MY2022_Tx" SG_ 968 SlMde_D_Rq 1;
BA_ "GenSigStartValueInteger" SG_ 968 IsaOffst_D_Rq 14;
BA_ "GenSigStartValue" SG_ 968 IsaOffst_D_Rq 14;
BA_ "GenSigSendType" SG_ 968 IsaOffst_D_Rq 3;
BA_ "U_P702_MY2021_Tx" SG_ 968 IsaOffst_D_Rq 1;
BA_ "U_T6_MCA_MY2020_Tx" SG_ 968 IsaOffst_D_Rq 1;
BA_ "U_CD542_MY2021_Tx" SG_ 968 IsaOffst_D_Rq 1;
BA_ "U_U55X_MY2022_Tx" SG_ 968 IsaOffst_D_Rq 1;
BA_ "U_T6_MCA_MY2020_Rx" SG_ 969 Dimming_Level_Stat 1;
BA_ "GenSigStartValueInteger" SG_ 969 Current_Color_Stat 8;
BA_ "GenSigStartValue" SG_ 969 Current_Color_Stat 8;
BA_ "U_T6_MCA_MY2020_Rx" SG_ 969 Current_Color_Stat 1;
BA_ "U_T6_MCA_MY2020_Rx" SG_ 969 BlendedColorRed_Stat 1;
BA_ "U_T6_MCA_MY2020_Rx" SG_ 969 BlendedColorGreen_Stat 1;
BA_ "U_T6_MCA_MY2020_Rx" SG_ 969 BlendedColorBlue_Stat 1;
BA_ "GenSigStartValueInteger" SG_ 969 BlendedColor_Stat 2;
BA_ "GenSigStartValue" SG_ 969 BlendedColor_Stat 2;
BA_ "U_T6_MCA_MY2020_Rx" SG_ 969 BlendedColor_Stat 1;
BA_ "WakeupSignal" SG_ 969 TurnLampRrOut_B_Stat 1;
BA_ "ContentDependant" SG_ 969 TurnLampRrOut_B_Stat 1;
BA_ "U_T6_MCA_MY2020_Rx" SG_ 969 TurnLampRrOut_B_Stat 1;
BA_ "WakeupSignal" SG_ 969 TurnLampRlOut_B_Stat 1;
BA_ "ContentDependant" SG_ 969 TurnLampRlOut_B_Stat 1;
BA_ "U_T6_MCA_MY2020_Rx" SG_ 969 TurnLampRlOut_B_Stat 1;
BA_ "GenSigStartValueInteger" SG_ 1006 PersIndexIpmb_D_Actl 4;
BA_ "GenSigStartValue" SG_ 1006 PersIndexIpmb_D_Actl 4;
BA_ "U_T6_MCA_MY2020_Rx" SG_ 1006 PersIndexIpmb_D_Actl 1;
BA_ "U_CD542_MY2021_Rx" SG_ 1006 PersIndexIpmb_D_Actl 1;
BA_ "U_T6_MCA_MY2020_Rx" SG_ 1006 FeatNoIpmbActl 1;
BA_ "U_U55X_MY2022_Rx" SG_ 1006 FeatNoIpmbActl 1;
BA_ "U_P702_MY2021_Rx" SG_ 1006 FeatNoIpmbActl 1;
BA_ "U_CD542_MY2021_Rx" SG_ 1006 FeatNoIpmbActl 1;
BA_ "U_T6_MCA_MY2020_Rx" SG_ 1006 FeatConfigIpmbActl 1;
BA_ "U_U55X_MY2022_Rx" SG_ 1006 FeatConfigIpmbActl 1;
BA_ "U_P702_MY2021_Rx" SG_ 1006 FeatConfigIpmbActl 1;
BA_ "U_CD542_MY2021_Rx" SG_ 1006 FeatConfigIpmbActl 1;
BA_ "U_P702_MY2021_Rx" SG_ 130 SteWhlSwtchHome_B_Stat 1;
BA_ "U_T6_MCA_MY2020_Rx" SG_ 130 SteWhlSwtchHome_B_Stat 1;
BA_ "U_CD542_MY2021_Rx" SG_ 130 SteWhlSwtchHome_B_Stat 1;
BA_ "U_U55X_MY2022_Rx" SG_ 130 SteWhlSwtchHome_B_Stat 1;
BA_ "U_T6_MCA_MY2020_Rx" SG_ 130 SteWhlSwtchInfo_B_Stat 1;
BA_ "U_CD542_MY2021_Rx" SG_ 130 SteWhlSwtchInfo_B_Stat 1;
BA_ "ContentDependant" SG_ 130 SelDrvMdeSwtch3_D_Stat4 1;
BA_ "WakeupSignal" SG_ 130 SteWhlSwtchView_B_Stat 1;
BA_ "U_T6_MCA_MY2020_Rx" SG_ 130 SteWhlSwtchView_B_Stat 1;
BA_ "U_CD542_MY2021_Rx" SG_ 130 SteWhlSwtchView_B_Stat 1;
BA_ "WakeupSignal" SG_ 130 SteWhlSwtchSet_B_Stat 1;
BA_ "U_T6_MCA_MY2020_Rx" SG_ 130 SteWhlSwtchSet_B_Stat 1;
BA_ "U_CD542_MY2021_Rx" SG_ 130 SteWhlSwtchSet_B_Stat 1;
BA_ "WakeupSignal" SG_ 130 SteWhlSwtchPhon_B_Stat 1;
BA_ "U_T6_MCA_MY2020_Rx" SG_ 130 SteWhlSwtchPhon_B_Stat 1;
BA_ "U_U55X_MY2022_Rx" SG_ 130 SteWhlSwtchPhon_B_Stat 1;
BA_ "U_CD542_MY2021_Rx" SG_ 130 SteWhlSwtchPhon_B_Stat 1;
BA_ "WakeupSignal" SG_ 130 SteWhlSwtchNav_B_Stat 1;
BA_ "U_T6_MCA_MY2020_Rx" SG_ 130 SteWhlSwtchNav_B_Stat 1;
BA_ "U_CD542_MY2021_Rx" SG_ 130 SteWhlSwtchNav_B_Stat 1;
BA_ "WakeupSignal" SG_ 130 SteWhlSwtchMed_B_Stat 1;
BA_ "U_T6_MCA_MY2020_Rx" SG_ 130 SteWhlSwtchMed_B_Stat 1;
BA_ "U_U55X_MY2022_Rx" SG_ 130 SteWhlSwtchMed_B_Stat 1;
BA_ "U_CD542_MY2021_Rx" SG_ 130 SteWhlSwtchMed_B_Stat 1;
BA_ "WakeupSignal" SG_ 130 SteWhlSwtchIod_B_Stat 1;
BA_ "U_T6_MCA_MY2020_Rx" SG_ 130 SteWhlSwtchIod_B_Stat 1;
BA_ "U_CD542_MY2021_Rx" SG_ 130 SteWhlSwtchIod_B_Stat 1;
BA_ "WakeupSignal" SG_ 130 SteWhlSwtchHud_B_Stat 1;
BA_ "U_T6_MCA_MY2020_Rx" SG_ 130 SteWhlSwtchHud_B_Stat 1;
BA_ "U_U55X_MY2022_Rx" SG_ 130 SteWhlSwtchHud_B_Stat 1;
BA_ "U_CD542_MY2021_Rx" SG_ 130 SteWhlSwtchHud_B_Stat 1;
BA_ "WakeupSignal" SG_ 130 SteWhlSwtchBack_B_Stat 1;
BA_ "U_T6_MCA_MY2020_Rx" SG_ 130 SteWhlSwtchBack_B_Stat 1;
BA_ "U_U55X_MY2022_Rx" SG_ 130 SteWhlSwtchBack_B_Stat 1;
BA_ "U_P702_MY2021_Rx" SG_ 130 SteWhlSwtchBack_B_Stat 1;
BA_ "U_CD542_MY2021_Rx" SG_ 130 SteWhlSwtchBack_B_Stat 1;
BA_ "WakeupSignal" SG_ 130 SteWhlSwtchMenu_B_Stat 1;
BA_ "U_P702_MY2021_Rx" SG_ 130 SteWhlSwtchMenu_B_Stat 1;
BA_ "U_T6_MCA_MY2020_Rx" SG_ 130 SteWhlSwtchMenu_B_Stat 1;
BA_ "U_CD542_MY2021_Rx" SG_ 130 SteWhlSwtchMenu_B_Stat 1;
BA_ "U_U55X_MY2022_Rx" SG_ 130 SteWhlSwtchMenu_B_Stat 1;
BA_ "U_T6_MCA_MY2020_Rx" SG_ 130 SteEffortInc_B_RqDrv 1;
BA_ "U_CD542_MY2021_Rx" SG_ 130 SteEffortInc_B_RqDrv 1;
BA_ "U_T6_MCA_MY2020_Rx" SG_ 130 SelDrvMdeInc_B_RqDrv 1;
BA_ "U_CD542_MY2021_Rx" SG_ 130 SelDrvMdeInc_B_RqDrv 1;
BA_ "U_T6_MCA_MY2020_Rx" SG_ 130 SelDrvMdeDec_B_RqDrv 1;
BA_ "U_CD542_MY2021_Rx" SG_ 130 SelDrvMdeDec_B_RqDrv 1;
BA_ "U_T6_MCA_MY2020_Rx" SG_ 130 SuspDampInc_B_RqDrv 1;
BA_ "U_CD542_MY2021_Rx" SG_ 130 SuspDampInc_B_RqDrv 1;
BA_ "WakeupSignal" SG_ 130 SteWhlSwtchUp_B_Stat 1;
BA_ "U_P702_MY2021_Rx" SG_ 130 SteWhlSwtchUp_B_Stat 1;
BA_ "U_T6_MCA_MY2020_Rx" SG_ 130 SteWhlSwtchUp_B_Stat 1;
BA_ "U_CD542_MY2021_Rx" SG_ 130 SteWhlSwtchUp_B_Stat 1;
BA_ "U_U55X_MY2022_Rx" SG_ 130 SteWhlSwtchUp_B_Stat 1;
BA_ "WakeupSignal" SG_ 130 SteWhlSwtchRght_B_Stat 1;
BA_ "U_T6_MCA_MY2020_Rx" SG_ 130 SteWhlSwtchRght_B_Stat 1;
BA_ "U_CD542_MY2021_Rx" SG_ 130 SteWhlSwtchRght_B_Stat 1;
BA_ "U_U55X_MY2022_Rx" SG_ 130 SteWhlSwtchRght_B_Stat 1;
BA_ "WakeupSignal" SG_ 130 SteWhlSwtchOk_B_Stat 1;
BA_ "U_P702_MY2021_Rx" SG_ 130 SteWhlSwtchOk_B_Stat 1;
BA_ "U_T6_MCA_MY2020_Rx" SG_ 130 SteWhlSwtchOk_B_Stat 1;
BA_ "U_CD542_MY2021_Rx" SG_ 130 SteWhlSwtchOk_B_Stat 1;
BA_ "U_U55X_MY2022_Rx" SG_ 130 SteWhlSwtchOk_B_Stat 1;
BA_ "WakeupSignal" SG_ 130 SteWhlSwtchLeft_B_Stat 1;
BA_ "U_T6_MCA_MY2020_Rx" SG_ 130 SteWhlSwtchLeft_B_Stat 1;
BA_ "U_CD542_MY2021_Rx" SG_ 130 SteWhlSwtchLeft_B_Stat 1;
BA_ "U_U55X_MY2022_Rx" SG_ 130 SteWhlSwtchLeft_B_Stat 1;
BA_ "WakeupSignal" SG_ 130 SteWhlSwtchDown_B_Stat 1;
BA_ "U_P702_MY2021_Rx" SG_ 130 SteWhlSwtchDown_B_Stat 1;
BA_ "U_T6_MCA_MY2020_Rx" SG_ 130 SteWhlSwtchDown_B_Stat 1;
BA_ "U_CD542_MY2021_Rx" SG_ 130 SteWhlSwtchDown_B_Stat 1;
BA_ "U_U55X_MY2022_Rx" SG_ 130 SteWhlSwtchDown_B_Stat 1;
BA_ "U_T6_MCA_MY2020_Tx" SG_ 1244 Con_InfotainmentVer_St 1;
BA_ "U_U55X_MY2022_Tx" SG_ 1244 Con_InfotainmentVer_St 1;
BA_ "U_T6_MCA_MY2020_Tx" SG_ 1244 Con_Profiles_St 1;
BA_ "U_U55X_MY2022_Tx" SG_ 1244 Con_Profiles_St 1;
BA_ "U_T6_MCA_MY2020_Tx" SG_ 1244 Con_Configuration 1;
BA_ "U_U55X_MY2022_Tx" SG_ 1244 Con_Configuration 1;
BA_ "U_T6_MCA_MY2020_Tx" SG_ 1243 Con_BTAud_InfotainmVer_St 1;
BA_ "U_T6_MCA_MY2020_Tx" SG_ 1243 Con_BTAud_Profiles_St 1;
BA_ "U_T6_MCA_MY2020_Tx" SG_ 1243 Con_BTAudConfiguration 1;
BA_ "GenSigSendType" SG_ 681 Con_DB1temIndex_St 1;
BA_ "U_T6_MCA_MY2020_Tx" SG_ 681 Con_DB1temIndex_St 1;
BA_ "U_T6_MCA_MY2020_Tx" SG_ 681 Con_DB1FilterConfig_St 1;
BA_ "U_T6_MCA_MY2020_Tx" SG_ 681 Con_DB1Filter3_St 1;
BA_ "U_T6_MCA_MY2020_Tx" SG_ 681 Con_DB1Filter2_St 1;
BA_ "U_T6_MCA_MY2020_Tx" SG_ 681 Con_DB1Filter1_St 1;
BA_ "GenSigSendType" SG_ 744 Con_USB_ActTrNum1_St 3;
BA_ "U_T6_MCA_MY2020_Rx" SG_ 744 Con_USB_ActTrNum1_St 1;
BA_ "U_CD542_MY2021_Rx" SG_ 744 Con_USB_ActTrNum1_St 1;
BA_ "U_T6_MCA_MY2020_Tx" SG_ 744 Con_USB_ActTrNum1_St 1;
BA_ "GenSigSendType" SG_ 744 Con_iPod_NumberOfTracks 3;
BA_ "U_T6_MCA_MY2020_Rx" SG_ 744 Con_iPod_NumberOfTracks 1;
BA_ "U_CD542_MY2021_Rx" SG_ 744 Con_iPod_NumberOfTracks 1;
BA_ "U_T6_MCA_MY2020_Tx" SG_ 744 Con_iPod_NumberOfTracks 1;
BA_ "GenSigSendType" SG_ 744 Con_USB_NumberOfTracks 3;
BA_ "U_T6_MCA_MY2020_Rx" SG_ 744 Con_USB_NumberOfTracks 1;
BA_ "U_CD542_MY2021_Rx" SG_ 744 Con_USB_NumberOfTracks 1;
BA_ "U_T6_MCA_MY2020_Tx" SG_ 744 Con_USB_NumberOfTracks 1;
BA_ "GenSigSendType" SG_ 741 Con_USB_Playtype_St 3;
BA_ "U_T6_MCA_MY2020_Rx" SG_ 741 Con_USB_Playtype_St 1;
BA_ "U_CD542_MY2021_Rx" SG_ 741 Con_USB_Playtype_St 1;
BA_ "U_U55X_MY2022_Rx" SG_ 741 Con_USB_Playtype_St 1;
BA_ "U_T6_MCA_MY2020_Tx" SG_ 741 Con_USB_Playtype_St 1;
BA_ "U_T6_MCA_MY2020_Rx" SG_ 741 Con_ShowSWDLBargr_St 1;
BA_ "U_CD542_MY2021_Rx" SG_ 741 Con_ShowSWDLBargr_St 1;
BA_ "U_U55X_MY2022_Rx" SG_ 741 Con_ShowSWDLBargr_St 1;
BA_ "U_T6_MCA_MY2020_Tx" SG_ 741 Con_ShowSWDLBargr_St 1;
BA_ "GenSigSendType" SG_ 741 Con_ShowSWDLprogress_St 3;
BA_ "U_T6_MCA_MY2020_Rx" SG_ 741 Con_ShowSWDLprogress_St 1;
BA_ "U_CD542_MY2021_Rx" SG_ 741 Con_ShowSWDLprogress_St 1;
BA_ "U_U55X_MY2022_Rx" SG_ 741 Con_ShowSWDLprogress_St 1;
BA_ "U_T6_MCA_MY2020_Tx" SG_ 741 Con_ShowSWDLprogress_St 1;
BA_ "GenSigSendType" SG_ 741 Con_iPod_IntroScan_St 3;
BA_ "U_T6_MCA_MY2020_Rx" SG_ 741 Con_iPod_IntroScan_St 1;
BA_ "U_CD542_MY2021_Rx" SG_ 741 Con_iPod_IntroScan_St 1;
BA_ "U_U55X_MY2022_Rx" SG_ 741 Con_iPod_IntroScan_St 1;
BA_ "U_T6_MCA_MY2020_Tx" SG_ 741 Con_iPod_IntroScan_St 1;
BA_ "GenSigSendType" SG_ 741 Con_iPod_Shuffle_St 3;
BA_ "U_T6_MCA_MY2020_Rx" SG_ 741 Con_iPod_Shuffle_St 1;
BA_ "U_CD542_MY2021_Rx" SG_ 741 Con_iPod_Shuffle_St 1;
BA_ "U_U55X_MY2022_Rx" SG_ 741 Con_iPod_Shuffle_St 1;
BA_ "U_T6_MCA_MY2020_Tx" SG_ 741 Con_iPod_Shuffle_St 1;
BA_ "GenSigSendType" SG_ 741 Con_iPod_Repeat_St 3;
BA_ "U_T6_MCA_MY2020_Rx" SG_ 741 Con_iPod_Repeat_St 1;
BA_ "U_CD542_MY2021_Rx" SG_ 741 Con_iPod_Repeat_St 1;
BA_ "U_U55X_MY2022_Rx" SG_ 741 Con_iPod_Repeat_St 1;
BA_ "U_T6_MCA_MY2020_Tx" SG_ 741 Con_iPod_Repeat_St 1;
BA_ "GenSigSendType" SG_ 741 Con_USB_Repeat_St 3;
BA_ "U_T6_MCA_MY2020_Rx" SG_ 741 Con_USB_Repeat_St 1;
BA_ "U_CD542_MY2021_Rx" SG_ 741 Con_USB_Repeat_St 1;
BA_ "U_U55X_MY2022_Rx" SG_ 741 Con_USB_Repeat_St 1;
BA_ "U_T6_MCA_MY2020_Tx" SG_ 741 Con_USB_Repeat_St 1;
BA_ "GenSigSendType" SG_ 741 Con_USB_IntroScan_St 3;
BA_ "U_T6_MCA_MY2020_Rx" SG_ 741 Con_USB_IntroScan_St 1;
BA_ "U_CD542_MY2021_Rx" SG_ 741 Con_USB_IntroScan_St 1;
BA_ "U_U55X_MY2022_Rx" SG_ 741 Con_USB_IntroScan_St 1;
BA_ "U_T6_MCA_MY2020_Tx" SG_ 741 Con_USB_IntroScan_St 1;
BA_ "GenSigSendType" SG_ 741 Con_USB_Shuffle_St 3;
BA_ "U_T6_MCA_MY2020_Rx" SG_ 741 Con_USB_Shuffle_St 1;
BA_ "U_CD542_MY2021_Rx" SG_ 741 Con_USB_Shuffle_St 1;
BA_ "U_U55X_MY2022_Rx" SG_ 741 Con_USB_Shuffle_St 1;
BA_ "U_T6_MCA_MY2020_Tx" SG_ 741 Con_USB_Shuffle_St 1;
BA_ "GenSigSendType" SG_ 741 Con_iPod_Error_St 3;
BA_ "U_T6_MCA_MY2020_Rx" SG_ 741 Con_iPod_Error_St 1;
BA_ "U_CD542_MY2021_Rx" SG_ 741 Con_iPod_Error_St 1;
BA_ "U_U55X_MY2022_Rx" SG_ 741 Con_iPod_Error_St 1;
BA_ "U_T6_MCA_MY2020_Tx" SG_ 741 Con_iPod_Error_St 1;
BA_ "GenSigSendType" SG_ 741 Con_USB_Error_St 3;
BA_ "U_T6_MCA_MY2020_Rx" SG_ 741 Con_USB_Error_St 1;
BA_ "U_CD542_MY2021_Rx" SG_ 741 Con_USB_Error_St 1;
BA_ "U_U55X_MY2022_Rx" SG_ 741 Con_USB_Error_St 1;
BA_ "U_T6_MCA_MY2020_Tx" SG_ 741 Con_USB_Error_St 1;
BA_ "GenSigSendType" SG_ 741 Con_iPod_FunctStatus_St 3;
BA_ "U_T6_MCA_MY2020_Rx" SG_ 741 Con_iPod_FunctStatus_St 1;
BA_ "U_CD542_MY2021_Rx" SG_ 741 Con_iPod_FunctStatus_St 1;
BA_ "U_U55X_MY2022_Rx" SG_ 741 Con_iPod_FunctStatus_St 1;
BA_ "U_T6_MCA_MY2020_Tx" SG_ 741 Con_iPod_FunctStatus_St 1;
BA_ "GenSigSendType" SG_ 741 Con_USB_FunctStatus_St 3;
BA_ "U_T6_MCA_MY2020_Rx" SG_ 741 Con_USB_FunctStatus_St 1;
BA_ "U_CD542_MY2021_Rx" SG_ 741 Con_USB_FunctStatus_St 1;
BA_ "U_U55X_MY2022_Rx" SG_ 741 Con_USB_FunctStatus_St 1;
BA_ "U_T6_MCA_MY2020_Tx" SG_ 741 Con_USB_FunctStatus_St 1;
BA_ "GenSigSendType" SG_ 741 Con_USB_OpMode_St 3;
BA_ "U_T6_MCA_MY2020_Rx" SG_ 741 Con_USB_OpMode_St 1;
BA_ "U_CD542_MY2021_Rx" SG_ 741 Con_USB_OpMode_St 1;
BA_ "U_U55X_MY2022_Rx" SG_ 741 Con_USB_OpMode_St 1;
BA_ "U_T6_MCA_MY2020_Tx" SG_ 741 Con_USB_OpMode_St 1;
BA_ "GenSigSendType" SG_ 741 Con_iPod_OpMode_St 3;
BA_ "U_T6_MCA_MY2020_Rx" SG_ 741 Con_iPod_OpMode_St 1;
BA_ "U_CD542_MY2021_Rx" SG_ 741 Con_iPod_OpMode_St 1;
BA_ "U_U55X_MY2022_Rx" SG_ 741 Con_iPod_OpMode_St 1;
BA_ "U_T6_MCA_MY2020_Tx" SG_ 741 Con_iPod_OpMode_St 1;
BA_ "U_T6_MCA_MY2020_Rx" SG_ 954 CargoLght_D_Stat 1;
BA_ "U_U55X_MY2022_Rx" SG_ 954 CargoLght_D_Stat 1;
BA_ "U_T6_MCA_MY2020_Rx" SG_ 954 TlghtTestLght_D_Stat 1;
BA_ "U_CD542_MY2021_Rx" SG_ 954 TlghtTestLght_D_Stat 1;
BA_ "U_U55X_MY2022_Rx" SG_ 954 TlghtTestLght_D_Stat 1;
BA_ "WakeupSignal" SG_ 954 LghtAmbDrvMde_B_Stat 1;
BA_ "U_U55X_MY2022_Rx" SG_ 954 LghtAmbDrvMde_B_Stat 1;
BA_ "U_T6_MCA_MY2020_Rx" SG_ 954 KeylessIdl_B_Stat 1;
BA_ "U_CD542_MY2021_Rx" SG_ 954 KeylessIdl_B_Stat 1;
BA_ "U_U55X_MY2022_Rx" SG_ 954 KeylessIdl_B_Stat 1;
BA_ "WakeupSignal" SG_ 954 PwRnngBoardPoll_D_Stat 1;
BA_ "U_T6_MCA_MY2020_Rx" SG_ 954 PoliceDmngLvl_D_Stat 1;
BA_ "U_CD542_MY2021_Rx" SG_ 954 PoliceDmngLvl_D_Stat 1;
BA_ "U_U55X_MY2022_Rx" SG_ 954 PoliceDmngLvl_D_Stat 1;
BA_ "WakeupSignal" SG_ 954 TrlrHitchLamp_D_Stat 1;
BA_ "U_T6_MCA_MY2020_Rx" SG_ 954 TrlrHitchLamp_D_Stat 1;
BA_ "U_CD542_MY2021_Rx" SG_ 954 TrlrHitchLamp_D_Stat 1;
BA_ "U_U55X_MY2022_Rx" SG_ 954 TrlrHitchLamp_D_Stat 1;
BA_ "U_T6_MCA_MY2020_Rx" SG_ 954 LicPlateLght_B_Stat 1;
BA_ "U_CD542_MY2021_Rx" SG_ 954 LicPlateLght_B_Stat 1;
BA_ "U_U55X_MY2022_Rx" SG_ 954 LicPlateLght_B_Stat 1;
BA_ "WakeupSignal" SG_ 954 TrukBedLght_B_Stat 1;
BA_ "U_T6_MCA_MY2020_Rx" SG_ 954 TrukBedLght_B_Stat 1;
BA_ "U_CD542_MY2021_Rx" SG_ 954 TrukBedLght_B_Stat 1;
BA_ "U_U55X_MY2022_Rx" SG_ 954 TrukBedLght_B_Stat 1;
BA_ "WakeupSignal" SG_ 954 VehWlcmFrwlMde_D_Stat 1;
BA_ "U_T6_MCA_MY2020_Rx" SG_ 954 VehWlcmFrwlMde_D_Stat 1;
BA_ "U_CD542_MY2021_Rx" SG_ 954 VehWlcmFrwlMde_D_Stat 1;
BA_ "U_U55X_MY2022_Rx" SG_ 954 VehWlcmFrwlMde_D_Stat 1;
BA_ "ContentDependant" SG_ 954 GenericSwtch2_No_Actl 1;
BA_ "WakeupSignal" SG_ 954 PudSptLghtRight_D_Rq 1;
BA_ "WakeupSignal" SG_ 954 PudSptLghtLeft_D_Rq 1;
BA_ "WakeupSignal" SG_ 954 ExtLghtRight_D_Stat 1;
BA_ "U_T6_MCA_MY2020_Rx" SG_ 954 ExtLghtRight_D_Stat 1;
BA_ "U_CD542_MY2021_Rx" SG_ 954 ExtLghtRight_D_Stat 1;
BA_ "U_U55X_MY2022_Rx" SG_ 954 ExtLghtRight_D_Stat 1;
BA_ "WakeupSignal" SG_ 954 VehWlcmFrwl_D_Stat 1;
BA_ "U_T6_MCA_MY2020_Rx" SG_ 954 VehWlcmFrwl_D_Stat 1;
BA_ "U_CD542_MY2021_Rx" SG_ 954 VehWlcmFrwl_D_Stat 1;
BA_ "U_U55X_MY2022_Rx" SG_ 954 VehWlcmFrwl_D_Stat 1;
BA_ "WakeupSignal" SG_ 954 ExtLghtRear_D_Stat 1;
BA_ "U_T6_MCA_MY2020_Rx" SG_ 954 ExtLghtRear_D_Stat 1;
BA_ "U_CD542_MY2021_Rx" SG_ 954 ExtLghtRear_D_Stat 1;
BA_ "U_U55X_MY2022_Rx" SG_ 954 ExtLghtRear_D_Stat 1;
BA_ "WakeupSignal" SG_ 954 ExtLghtLeft_D_Stat 1;
BA_ "U_T6_MCA_MY2020_Rx" SG_ 954 ExtLghtLeft_D_Stat 1;
BA_ "U_CD542_MY2021_Rx" SG_ 954 ExtLghtLeft_D_Stat 1;
BA_ "U_U55X_MY2022_Rx" SG_ 954 ExtLghtLeft_D_Stat 1;
BA_ "WakeupSignal" SG_ 954 ExtLghtAlrt_B_Rq 1;
BA_ "U_T6_MCA_MY2020_Rx" SG_ 954 ExtLghtAlrt_B_Rq 1;
BA_ "U_CD542_MY2021_Rx" SG_ 954 ExtLghtAlrt_B_Rq 1;
BA_ "U_U55X_MY2022_Rx" SG_ 954 ExtLghtAlrt_B_Rq 1;
BA_ "WakeupSignal" SG_ 954 ExtLght_D_Falt 1;
BA_ "U_T6_MCA_MY2020_Rx" SG_ 954 ExtLght_D_Falt 1;
BA_ "U_CD542_MY2021_Rx" SG_ 954 ExtLght_D_Falt 1;
BA_ "U_U55X_MY2022_Rx" SG_ 954 ExtLght_D_Falt 1;
BA_ "WakeupSignal" SG_ 954 ExtLghtFront_D_Stat 1;
BA_ "U_T6_MCA_MY2020_Rx" SG_ 954 ExtLghtFront_D_Stat 1;
BA_ "U_CD542_MY2021_Rx" SG_ 954 ExtLghtFront_D_Stat 1;
BA_ "U_U55X_MY2022_Rx" SG_ 954 ExtLghtFront_D_Stat 1;
BA_ "U_T6_MCA_MY2020_Rx" SG_ 954 TlghtTestPrecnd_D_Stat 1;
BA_ "U_CD542_MY2021_Rx" SG_ 954 TlghtTestPrecnd_D_Stat 1;
BA_ "U_U55X_MY2022_Rx" SG_ 954 TlghtTestPrecnd_D_Stat 1;
BA_ "U_T6_MCA_MY2020_Rx" SG_ 954 TlghtTest_D_Stat 1;
BA_ "U_CD542_MY2021_Rx" SG_ 954 TlghtTest_D_Stat 1;
BA_ "U_U55X_MY2022_Rx" SG_ 954 TlghtTest_D_Stat 1;
BA_ "GenSigStartValueInteger" SG_ 125 VehRolComp_W_Actl 4094;
BA_ "GenSigStartValue" SG_ 125 VehRolComp_W_Actl 4094;
BA_ "U_P702_MY2021_Rx" SG_ 125 VehRolComp_W_Actl 1;
BA_ "U_T6_MCA_MY2020_Rx" SG_ 125 VehRolComp_W_Actl 1;
BA_ "U_CD542_MY2021_Rx" SG_ 125 VehRolComp_W_Actl 1;
BA_ "U_U55X_MY2022_Rx" SG_ 125 VehRolComp_W_Actl 1;
BA_ "GenSigStartValueInteger" SG_ 125 VehVertComp_A_Actl 1022;
BA_ "GenSigStartValue" SG_ 125 VehVertComp_A_Actl 1022;
BA_ "U_P702_MY2021_Rx" SG_ 125 VehVertComp_A_Actl 1;
BA_ "U_T6_MCA_MY2020_Rx" SG_ 125 VehVertComp_A_Actl 1;
BA_ "U_CD542_MY2021_Rx" SG_ 125 VehVertComp_A_Actl 1;
BA_ "U_U55X_MY2022_Rx" SG_ 125 VehVertComp_A_Actl 1;
BA_ "MetaData" SG_ 125 BrkTotTqRqArb_No_Cs 1;
BA_ "U_P702_MY2021_Rx" SG_ 125 BrkTotTqRqArb_No_Cs 1;
BA_ "U_T6_MCA_MY2020_Rx" SG_ 125 BrkTotTqRqArb_No_Cs 1;
BA_ "U_U55X_MY2022_Rx" SG_ 125 BrkTotTqRqArb_No_Cs 1;
BA_ "MetaData" SG_ 125 BrkTotTqRqArb_No_Cnt 1;
BA_ "U_P702_MY2021_Rx" SG_ 125 BrkTotTqRqArb_No_Cnt 1;
BA_ "U_T6_MCA_MY2020_Rx" SG_ 125 BrkTotTqRqArb_No_Cnt 1;
BA_ "U_U55X_MY2022_Rx" SG_ 125 BrkTotTqRqArb_No_Cnt 1;
BA_ "U_P702_MY2021_Rx" SG_ 125 BrkTot_Tq_RqArb 1;
BA_ "U_T6_MCA_MY2020_Rx" SG_ 125 BrkTot_Tq_RqArb 1;
BA_ "U_U55X_MY2022_Rx" SG_ 125 BrkTot_Tq_RqArb 1;
BA_ "U_CD542_MY2021_Rx" SG_ 125 BrkTot_Tq_RqArb 1;
BA_ "U_T6_MCA_MY2020_Rx" SG_ 125 BrkTot_Tq_Actl 1;
BA_ "U_U55X_MY2022_Rx" SG_ 125 BrkTot_Tq_Actl 1;
BA_ "U_P702_MY2021_Rx" SG_ 125 BrkTot_Tq_Actl 1;
BA_ "U_CD542_MY2021_Rx" SG_ 125 BrkTot_Tq_Actl 1;
BA_ "U_P702_MY2021_Rx" SG_ 125 HsaStat_D_Actl 1;
BA_ "U_T6_MCA_MY2020_Rx" SG_ 125 HsaStat_D_Actl 1;
BA_ "U_CD542_MY2021_Rx" SG_ 125 HsaStat_D_Actl 1;
BA_ "GenSigSendType" SG_ 2612224096 PARSEDPushIPCtoGWM_ECG 3;
BA_ "U_T6_MCA_MY2020_Rx" SG_ 2612224096 PARSEDPushIPCtoGWM_ECG 1;
BA_ "ECGUsedRxSignal" SG_ 2612224096 PARSEDPushIPCtoGWM_ECG 1;
BA_ "U_CD542_MY2021_Rx" SG_ 2612224096 PARSEDPushIPCtoGWM_ECG 1;
BA_ "U_U55X_MY2022_Rx" SG_ 2612224096 PARSEDPushIPCtoGWM_ECG 1;
BA_ "U_P702_MY2021_Tx" SG_ 2612224096 PARSEDPushIPCtoGWM_ECG 1;
BA_ "U_T6_MCA_MY2020_Tx" SG_ 2612224096 PARSEDPushIPCtoGWM_ECG 1;
BA_ "U_CD542_MY2021_Tx" SG_ 2612224096 PARSEDPushIPCtoGWM_ECG 1;
BA_ "U_U55X_MY2022_Tx" SG_ 2612224096 PARSEDPushIPCtoGWM_ECG 1;
BA_ "GenSigSendType" SG_ 2611052760 PARSEDPhysGWM_ECGtoIPC 3;
BA_ "U_P702_MY2021_Rx" SG_ 2611052760 PARSEDPhysGWM_ECGtoIPC 1;
BA_ "U_T6_MCA_MY2020_Rx" SG_ 2611052760 PARSEDPhysGWM_ECGtoIPC 1;
BA_ "U_CD542_MY2021_Rx" SG_ 2611052760 PARSEDPhysGWM_ECGtoIPC 1;
BA_ "U_U55X_MY2022_Rx" SG_ 2611052760 PARSEDPhysGWM_ECGtoIPC 1;
BA_ "U_T6_MCA_MY2020_Tx" SG_ 2611052760 PARSEDPhysGWM_ECGtoIPC 1;
BA_ "ECGUsedTxSignal" SG_ 2611052760 PARSEDPhysGWM_ECGtoIPC 1;
BA_ "U_CD542_MY2021_Tx" SG_ 2611052760 PARSEDPhysGWM_ECGtoIPC 1;
BA_ "U_U55X_MY2022_Tx" SG_ 2611052760 PARSEDPhysGWM_ECGtoIPC 1;
BA_ "GenSigSendType" SG_ 2611175520 PARSEDPhysIPCtoGWM_ECG 3;
BA_ "U_T6_MCA_MY2020_Rx" SG_ 2611175520 PARSEDPhysIPCtoGWM_ECG 1;
BA_ "ECGUsedRxSignal" SG_ 2611175520 PARSEDPhysIPCtoGWM_ECG 1;
BA_ "U_CD542_MY2021_Rx" SG_ 2611175520 PARSEDPhysIPCtoGWM_ECG 1;
BA_ "U_U55X_MY2022_Rx" SG_ 2611175520 PARSEDPhysIPCtoGWM_ECG 1;
BA_ "U_P702_MY2021_Tx" SG_ 2611175520 PARSEDPhysIPCtoGWM_ECG 1;
BA_ "U_T6_MCA_MY2020_Tx" SG_ 2611175520 PARSEDPhysIPCtoGWM_ECG 1;
BA_ "U_CD542_MY2021_Tx" SG_ 2611175520 PARSEDPhysIPCtoGWM_ECG 1;
BA_ "U_U55X_MY2022_Tx" SG_ 2611175520 PARSEDPhysIPCtoGWM_ECG 1;
BA_ "GenSigSendType" SG_ 2610126944 OTAPhysIPCtoGWM_ECG 3;
BA_ "U_T6_MCA_MY2020_Rx" SG_ 2610126944 OTAPhysIPCtoGWM_ECG 1;
BA_ "ECGUsedRxSignal" SG_ 2610126944 OTAPhysIPCtoGWM_ECG 1;
BA_ "U_CD542_MY2021_Rx" SG_ 2610126944 OTAPhysIPCtoGWM_ECG 1;
BA_ "U_U55X_MY2022_Rx" SG_ 2610126944 OTAPhysIPCtoGWM_ECG 1;
BA_ "U_P702_MY2021_Tx" SG_ 2610126944 OTAPhysIPCtoGWM_ECG 1;
BA_ "U_T6_MCA_MY2020_Tx" SG_ 2610126944 OTAPhysIPCtoGWM_ECG 1;
BA_ "U_CD542_MY2021_Tx" SG_ 2610126944 OTAPhysIPCtoGWM_ECG 1;
BA_ "U_U55X_MY2022_Tx" SG_ 2610126944 OTAPhysIPCtoGWM_ECG 1;
BA_ "GenSigSendType" SG_ 2610004184 OTAPhysGWM_ECGtoIPC 3;
BA_ "U_P702_MY2021_Rx" SG_ 2610004184 OTAPhysGWM_ECGtoIPC 1;
BA_ "U_T6_MCA_MY2020_Rx" SG_ 2610004184 OTAPhysGWM_ECGtoIPC 1;
BA_ "U_CD542_MY2021_Rx" SG_ 2610004184 OTAPhysGWM_ECGtoIPC 1;
BA_ "U_U55X_MY2022_Rx" SG_ 2610004184 OTAPhysGWM_ECGtoIPC 1;
BA_ "U_T6_MCA_MY2020_Tx" SG_ 2610004184 OTAPhysGWM_ECGtoIPC 1;
BA_ "ECGUsedTxSignal" SG_ 2610004184 OTAPhysGWM_ECGtoIPC 1;
BA_ "U_CD542_MY2021_Tx" SG_ 2610004184 OTAPhysGWM_ECGtoIPC 1;
BA_ "U_U55X_MY2022_Tx" SG_ 2610004184 OTAPhysGWM_ECGtoIPC 1;
BA_ "GenSigSendType" SG_ 2005 TesterPhysicalReqDACMC 3;
BA_ "GenSigSendType" SG_ 2013 TesterPhysicalResDACMC 3;
BA_ "GenSigStartValueInteger" SG_ 1519 DACMC_GWOnBoardTester 255;
BA_ "ContentDependant" SG_ 1519 DACMC_GWOnBoardTester 1;
BA_ "GenSigStartValue" SG_ 1519 DACMC_GWOnBoardTester 255;
BA_ "U_U55X_MY2022_Rx" SG_ 1519 DACMC_GWOnBoardTester 1;
BA_ "GenSigStartValueInteger" SG_ 1519 DACMC_GWNMProxy 255;
BA_ "ContentDependant" SG_ 1519 DACMC_GWNMProxy 1;
BA_ "GenSigStartValue" SG_ 1519 DACMC_GWNMProxy 255;
BA_ "U_U55X_MY2022_Rx" SG_ 1519 DACMC_GWNMProxy 1;
BA_ "GenSigStartValueInteger" SG_ 1519 DACMC_AutoSarNMReserved4 255;
BA_ "ContentDependant" SG_ 1519 DACMC_AutoSarNMReserved4 1;
BA_ "GenSigStartValue" SG_ 1519 DACMC_AutoSarNMReserved4 255;
BA_ "U_U55X_MY2022_Rx" SG_ 1519 DACMC_AutoSarNMReserved4 1;
BA_ "GenSigStartValueInteger" SG_ 1519 DACMC_AutoSarNMReserved3 255;
BA_ "ContentDependant" SG_ 1519 DACMC_AutoSarNMReserved3 1;
BA_ "GenSigStartValue" SG_ 1519 DACMC_AutoSarNMReserved3 255;
BA_ "U_U55X_MY2022_Rx" SG_ 1519 DACMC_AutoSarNMReserved3 1;
BA_ "GenSigStartValueInteger" SG_ 1519 DACMC_AutoSarNMReserved2 255;
BA_ "ContentDependant" SG_ 1519 DACMC_AutoSarNMReserved2 1;
BA_ "GenSigStartValue" SG_ 1519 DACMC_AutoSarNMReserved2 255;
BA_ "U_U55X_MY2022_Rx" SG_ 1519 DACMC_AutoSarNMReserved2 1;
BA_ "GenSigStartValueInteger" SG_ 1519 DACMC_AutoSarNMReserved1 255;
BA_ "ContentDependant" SG_ 1519 DACMC_AutoSarNMReserved1 1;
BA_ "GenSigStartValue" SG_ 1519 DACMC_AutoSarNMReserved1 255;
BA_ "U_U55X_MY2022_Rx" SG_ 1519 DACMC_AutoSarNMReserved1 1;
BA_ "GenSigStartValueInteger" SG_ 1519 DACMC_AutoSarNMNodeId 150;
BA_ "ContentDependant" SG_ 1519 DACMC_AutoSarNMNodeId 1;
BA_ "GenSigStartValue" SG_ 1519 DACMC_AutoSarNMNodeId 239;
BA_ "U_U55X_MY2022_Rx" SG_ 1519 DACMC_AutoSarNMNodeId 1;
BA_ "ContentDependant" SG_ 1519 DACMC_AutoSarNMControl 1;
BA_ "U_U55X_MY2022_Rx" SG_ 1519 DACMC_AutoSarNMControl 1;
BA_ "GenSigSendType" SG_ 2612002008 PARSEDFuncGWM_ECG 3;
BA_ "U_P702_MY2021_Rx" SG_ 2612002008 PARSEDFuncGWM_ECG 1;
BA_ "U_T6_MCA_MY2020_Rx" SG_ 2612002008 PARSEDFuncGWM_ECG 1;
BA_ "U_CD542_MY2021_Rx" SG_ 2612002008 PARSEDFuncGWM_ECG 1;
BA_ "U_U55X_MY2022_Rx" SG_ 2612002008 PARSEDFuncGWM_ECG 1;
BA_ "U_T6_MCA_MY2020_Tx" SG_ 2612002008 PARSEDFuncGWM_ECG 1;
BA_ "ECGUsedTxSignal" SG_ 2612002008 PARSEDFuncGWM_ECG 1;
BA_ "U_CD542_MY2021_Tx" SG_ 2612002008 PARSEDFuncGWM_ECG 1;
BA_ "U_U55X_MY2022_Tx" SG_ 2612002008 PARSEDFuncGWM_ECG 1;
BA_ "GenSigSendType" SG_ 2610953432 OTAFuncGWM_ECG 3;
BA_ "U_P702_MY2021_Rx" SG_ 2610953432 OTAFuncGWM_ECG 1;
BA_ "U_T6_MCA_MY2020_Rx" SG_ 2610953432 OTAFuncGWM_ECG 1;
BA_ "U_CD542_MY2021_Rx" SG_ 2610953432 OTAFuncGWM_ECG 1;
BA_ "U_U55X_MY2022_Rx" SG_ 2610953432 OTAFuncGWM_ECG 1;
BA_ "U_T6_MCA_MY2020_Tx" SG_ 2610953432 OTAFuncGWM_ECG 1;
BA_ "ECGUsedTxSignal" SG_ 2610953432 OTAFuncGWM_ECG 1;
BA_ "U_CD542_MY2021_Tx" SG_ 2610953432 OTAFuncGWM_ECG 1;
BA_ "U_U55X_MY2022_Tx" SG_ 2610953432 OTAFuncGWM_ECG 1;
BA_ "GenSigSendType" SG_ 1082 SldrrStat_B_Actl 3;
BA_ "GenSigSendType" SG_ 1082 SldrlStat_B_Actl 3;
BA_ "U_T6_MCA_MY2020_Rx" SG_ 1082 StabBarFaltMsgTxt_D_Rq_UB 1;
BA_ "U_T6_MCA_MY2020_Rx" SG_ 1082 StabBarCnnctLamp_D_Rq_UB 1;
BA_ "U_U55X_MY2022_Rx" SG_ 1082 StabBarCnnctLamp_D_Rq_UB 1;
BA_ "U_T6_MCA_MY2020_Rx" SG_ 1082 StabBarCnncMsgTxt_D_Rq_UB 1;
BA_ "GenSigSendType" SG_ 1082 StabBarFaltMsgTxt_D_Rq 3;
BA_ "U_T6_MCA_MY2020_Rx" SG_ 1082 StabBarFaltMsgTxt_D_Rq 1;
BA_ "GenSigSendType" SG_ 1082 StabBarCnnctLamp_D_Rq 3;
BA_ "U_T6_MCA_MY2020_Rx" SG_ 1082 StabBarCnnctLamp_D_Rq 1;
BA_ "U_U55X_MY2022_Rx" SG_ 1082 StabBarCnnctLamp_D_Rq 1;
BA_ "GenSigSendType" SG_ 1082 StabBarCnncMsgTxt_D_Rq 3;
BA_ "U_T6_MCA_MY2020_Rx" SG_ 1082 StabBarCnncMsgTxt_D_Rq 1;
BA_ "U_T6_MCA_MY2020_Rx" SG_ 576 AUDIO_RDISP2_WORD_Tx 1;
BA_ "U_U55X_MY2022_Rx" SG_ 576 AUDIO_RDISP2_WORD_Tx 1;
BA_ "U_T6_MCA_MY2020_Tx" SG_ 576 AUDIO_RDISP2_WORD_Tx 1;
BA_ "U_U55X_MY2022_Tx" SG_ 576 AUDIO_RDISP2_WORD_Tx 1;
BA_ "GenSigSendType" SG_ 1115 HUD_TextMessage_Rq 3;
BA_ "U_CD542_MY2021_Rx" SG_ 1115 HUD_TextMessage_Rq 1;
BA_ "U_U55X_MY2022_Rx" SG_ 1115 HUD_TextMessage_Rq 1;
BA_ "U_T6_MCA_MY2020_Tx" SG_ 1115 HUD_TextMessage_Rq 1;
BA_ "U_U55X_MY2022_Tx" SG_ 1115 HUD_TextMessage_Rq 1;
BA_ "GenSigSendType" SG_ 1115 HUD_BTIncomingCall_Rq 3;
BA_ "U_CD542_MY2021_Rx" SG_ 1115 HUD_BTIncomingCall_Rq 1;
BA_ "U_U55X_MY2022_Rx" SG_ 1115 HUD_BTIncomingCall_Rq 1;
BA_ "U_T6_MCA_MY2020_Tx" SG_ 1115 HUD_BTIncomingCall_Rq 1;
BA_ "U_U55X_MY2022_Tx" SG_ 1115 HUD_BTIncomingCall_Rq 1;
BA_ "GenSigSendType" SG_ 1115 HUD_BTInCallOptions_Rq 3;
BA_ "U_CD542_MY2021_Rx" SG_ 1115 HUD_BTInCallOptions_Rq 1;
BA_ "U_U55X_MY2022_Rx" SG_ 1115 HUD_BTInCallOptions_Rq 1;
BA_ "U_T6_MCA_MY2020_Tx" SG_ 1115 HUD_BTInCallOptions_Rq 1;
BA_ "U_U55X_MY2022_Tx" SG_ 1115 HUD_BTInCallOptions_Rq 1;
BA_ "GenSigSendType" SG_ 1115 HUD_BTEndTelService_Rq 3;
BA_ "U_CD542_MY2021_Rx" SG_ 1115 HUD_BTEndTelService_Rq 1;
BA_ "U_U55X_MY2022_Rx" SG_ 1115 HUD_BTEndTelService_Rq 1;
BA_ "U_T6_MCA_MY2020_Tx" SG_ 1115 HUD_BTEndTelService_Rq 1;
BA_ "U_U55X_MY2022_Tx" SG_ 1115 HUD_BTEndTelService_Rq 1;
BA_ "GenSigSendType" SG_ 996 PersIndexHud_D_Actl 3;
BA_ "U_T6_MCA_MY2020_Rx" SG_ 996 PersIndexHud_D_Actl 1;
BA_ "U_U55X_MY2022_Rx" SG_ 996 PersIndexHud_D_Actl 1;
BA_ "U_T6_MCA_MY2020_Tx" SG_ 996 PersIndexHud_D_Actl 1;
BA_ "U_U55X_MY2022_Tx" SG_ 996 PersIndexHud_D_Actl 1;
BA_ "GenSigSendType" SG_ 996 FeatNoHudActl 3;
BA_ "U_T6_MCA_MY2020_Rx" SG_ 996 FeatNoHudActl 1;
BA_ "U_U55X_MY2022_Rx" SG_ 996 FeatNoHudActl 1;
BA_ "U_T6_MCA_MY2020_Tx" SG_ 996 FeatNoHudActl 1;
BA_ "U_U55X_MY2022_Tx" SG_ 996 FeatNoHudActl 1;
BA_ "GenSigSendType" SG_ 996 FeatConfigHudActl 3;
BA_ "U_T6_MCA_MY2020_Rx" SG_ 996 FeatConfigHudActl 1;
BA_ "U_U55X_MY2022_Rx" SG_ 996 FeatConfigHudActl 1;
BA_ "U_T6_MCA_MY2020_Tx" SG_ 996 FeatConfigHudActl 1;
BA_ "U_U55X_MY2022_Tx" SG_ 996 FeatConfigHudActl 1;
BA_ "U_T6_MCA_MY2020_Tx" SG_ 588 RDRV_RDISP2_WORD_Rx 1;
BA_ "U_U55X_MY2022_Tx" SG_ 588 RDRV_RDISP2_WORD_Rx 1;
BA_ "GenSigSendType" SG_ 811 ExtLghtDsply_D_Stat 3;
BA_ "U_T6_MCA_MY2020_Rx" SG_ 811 ExtLghtDsply_D_Stat 1;
BA_ "ECGUsedRxSignal" SG_ 811 ExtLghtDsply_D_Stat 1;
BA_ "U_CD542_MY2021_Rx" SG_ 811 ExtLghtDsply_D_Stat 1;
BA_ "U_U55X_MY2022_Rx" SG_ 811 ExtLghtDsply_D_Stat 1;
BA_ "U_T6_MCA_MY2020_Tx" SG_ 811 ExtLghtDsply_D_Stat 1;
BA_ "U_CD542_MY2021_Tx" SG_ 811 ExtLghtDsply_D_Stat 1;
BA_ "U_U55X_MY2022_Tx" SG_ 811 ExtLghtDsply_D_Stat 1;
BA_ "GenSigSendType" SG_ 811 SpeedoMajorUnit_D_Confg 3;
BA_ "U_T6_MCA_MY2020_Tx" SG_ 811 SpeedoMajorUnit_D_Confg 1;
BA_ "U_CD542_MY2021_Tx" SG_ 811 SpeedoMajorUnit_D_Confg 1;
BA_ "U_U55X_MY2022_Tx" SG_ 811 SpeedoMajorUnit_D_Confg 1;
BA_ "GenSigStartValue" SG_ 811 ScMnSoc_Pc_RqMnu 126;
BA_ "U_T6_MCA_MY2020_Tx" SG_ 811 ScMnSoc_Pc_RqMnu 1;
BA_ "U_CD542_MY2021_Tx" SG_ 811 ScMnSoc_Pc_RqMnu 1;
BA_ "U_U55X_MY2022_Tx" SG_ 811 ScMnSoc_Pc_RqMnu 1;
BA_ "GenSigSendType" SG_ 811 ScEnbl_D_RqMnu 3;
BA_ "U_T6_MCA_MY2020_Tx" SG_ 811 ScEnbl_D_RqMnu 1;
BA_ "U_CD542_MY2021_Tx" SG_ 811 ScEnbl_D_RqMnu 1;
BA_ "U_U55X_MY2022_Tx" SG_ 811 ScEnbl_D_RqMnu 1;
BA_ "GenSigSendType" SG_ 811 OnePdlDrvButtn_B_Falt 3;
BA_ "U_T6_MCA_MY2020_Tx" SG_ 811 OnePdlDrvButtn_B_Falt 1;
BA_ "U_CD542_MY2021_Tx" SG_ 811 OnePdlDrvButtn_B_Falt 1;
BA_ "U_U55X_MY2022_Tx" SG_ 811 OnePdlDrvButtn_B_Falt 1;
BA_ "GenSigSendType" SG_ 811 OnePdlDrvButtn_B_Stat 3;
BA_ "U_T6_MCA_MY2020_Tx" SG_ 811 OnePdlDrvButtn_B_Stat 1;
BA_ "U_CD542_MY2021_Tx" SG_ 811 OnePdlDrvButtn_B_Stat 1;
BA_ "U_U55X_MY2022_Tx" SG_ 811 OnePdlDrvButtn_B_Stat 1;
BA_ "GenSigSendType" SG_ 811 LongTermReset_B_RqMnu 3;
BA_ "U_T6_MCA_MY2020_Tx" SG_ 811 LongTermReset_B_RqMnu 1;
BA_ "U_CD542_MY2021_Tx" SG_ 811 LongTermReset_B_RqMnu 1;
BA_ "U_U55X_MY2022_Tx" SG_ 811 LongTermReset_B_RqMnu 1;
BA_ "GenSigStartValue" SG_ 811 DistToStopover_L_Actl 65535;
BA_ "U_T6_MCA_MY2020_Rx" SG_ 811 DistToStopover_L_Actl 1;
BA_ "ECGUsedRxSignal" SG_ 811 DistToStopover_L_Actl 1;
BA_ "U_CD542_MY2021_Rx" SG_ 811 DistToStopover_L_Actl 1;
BA_ "U_U55X_MY2022_Rx" SG_ 811 DistToStopover_L_Actl 1;
BA_ "U_T6_MCA_MY2020_Tx" SG_ 811 DistToStopover_L_Actl 1;
BA_ "U_CD542_MY2021_Tx" SG_ 811 DistToStopover_L_Actl 1;
BA_ "U_U55X_MY2022_Tx" SG_ 811 DistToStopover_L_Actl 1;
BA_ "GenSigSendType" SG_ 811 StopoverType_D_Stat 3;
BA_ "U_T6_MCA_MY2020_Rx" SG_ 811 StopoverType_D_Stat 1;
BA_ "ECGUsedRxSignal" SG_ 811 StopoverType_D_Stat 1;
BA_ "U_CD542_MY2021_Rx" SG_ 811 StopoverType_D_Stat 1;
BA_ "U_U55X_MY2022_Rx" SG_ 811 StopoverType_D_Stat 1;
BA_ "U_T6_MCA_MY2020_Tx" SG_ 811 StopoverType_D_Stat 1;
BA_ "U_CD542_MY2021_Tx" SG_ 811 StopoverType_D_Stat 1;
BA_ "U_U55X_MY2022_Tx" SG_ 811 StopoverType_D_Stat 1;
BA_ "WakeupSignal" SG_ 811 ExtLghtRight_D_RqMnu 1;
BA_ "GenSigSendType" SG_ 811 ExtLghtRight_D_RqMnu 3;
BA_ "U_T6_MCA_MY2020_Tx" SG_ 811 ExtLghtRight_D_RqMnu 1;
BA_ "U_CD542_MY2021_Tx" SG_ 811 ExtLghtRight_D_RqMnu 1;
BA_ "U_U55X_MY2022_Tx" SG_ 811 ExtLghtRight_D_RqMnu 1;
BA_ "WakeupSignal" SG_ 811 AutoLghtOvrrd_B_RqDrv 1;
BA_ "GenSigSendType" SG_ 811 AutoLghtOvrrd_B_RqDrv 3;
BA_ "U_T6_MCA_MY2020_Tx" SG_ 811 AutoLghtOvrrd_B_RqDrv 1;
BA_ "U_CD542_MY2021_Tx" SG_ 811 AutoLghtOvrrd_B_RqDrv 1;
BA_ "U_U55X_MY2022_Tx" SG_ 811 AutoLghtOvrrd_B_RqDrv 1;
BA_ "WakeupSignal" SG_ 811 ExtLghtRear_D_RqMnu 1;
BA_ "GenSigSendType" SG_ 811 ExtLghtRear_D_RqMnu 3;
BA_ "U_T6_MCA_MY2020_Tx" SG_ 811 ExtLghtRear_D_RqMnu 1;
BA_ "U_CD542_MY2021_Tx" SG_ 811 ExtLghtRear_D_RqMnu 1;
BA_ "U_U55X_MY2022_Tx" SG_ 811 ExtLghtRear_D_RqMnu 1;
BA_ "WakeupSignal" SG_ 811 ExtLghtLeft_D_RqMnu 1;
BA_ "GenSigSendType" SG_ 811 ExtLghtLeft_D_RqMnu 3;
BA_ "U_T6_MCA_MY2020_Tx" SG_ 811 ExtLghtLeft_D_RqMnu 1;
BA_ "U_CD542_MY2021_Tx" SG_ 811 ExtLghtLeft_D_RqMnu 1;
BA_ "U_U55X_MY2022_Tx" SG_ 811 ExtLghtLeft_D_RqMnu 1;
BA_ "WakeupSignal" SG_ 811 ExtLghtFront_D_RqMnu 1;
BA_ "GenSigSendType" SG_ 811 ExtLghtFront_D_RqMnu 3;
BA_ "U_T6_MCA_MY2020_Tx" SG_ 811 ExtLghtFront_D_RqMnu 1;
BA_ "U_CD542_MY2021_Tx" SG_ 811 ExtLghtFront_D_RqMnu 1;
BA_ "U_U55X_MY2022_Tx" SG_ 811 ExtLghtFront_D_RqMnu 1;
BA_ "WakeupSignal" SG_ 811 BecRleas_No_RqMnu 1;
BA_ "GenSigSendType" SG_ 811 BecRleas_No_RqMnu 3;
BA_ "U_T6_MCA_MY2020_Tx" SG_ 811 BecRleas_No_RqMnu 1;
BA_ "U_CD542_MY2021_Tx" SG_ 811 BecRleas_No_RqMnu 1;
BA_ "U_U55X_MY2022_Tx" SG_ 811 BecRleas_No_RqMnu 1;
BA_ "WakeupSignal" SG_ 811 TrnkFrontRleas_No_RqMnu 1;
BA_ "GenSigSendType" SG_ 811 TrnkFrontRleas_No_RqMnu 3;
BA_ "U_T6_MCA_MY2020_Tx" SG_ 811 TrnkFrontRleas_No_RqMnu 1;
BA_ "U_CD542_MY2021_Tx" SG_ 811 TrnkFrontRleas_No_RqMnu 1;
BA_ "U_U55X_MY2022_Tx" SG_ 811 TrnkFrontRleas_No_RqMnu 1;
BA_ "GenSigStartValue" SG_ 811 GoTEditMnte_T_RqMnu 14;
BA_ "GenSigSendType" SG_ 811 GoTEditMnte_T_RqMnu 3;
BA_ "U_T6_MCA_MY2020_Rx" SG_ 811 GoTEditMnte_T_RqMnu 1;
BA_ "ECGUsedRxSignal" SG_ 811 GoTEditMnte_T_RqMnu 1;
BA_ "U_CD542_MY2021_Rx" SG_ 811 GoTEditMnte_T_RqMnu 1;
BA_ "U_U55X_MY2022_Rx" SG_ 811 GoTEditMnte_T_RqMnu 1;
BA_ "U_T6_MCA_MY2020_Tx" SG_ 811 GoTEditMnte_T_RqMnu 1;
BA_ "U_CD542_MY2021_Tx" SG_ 811 GoTEditMnte_T_RqMnu 1;
BA_ "U_U55X_MY2022_Tx" SG_ 811 GoTEditMnte_T_RqMnu 1;
BA_ "GenSigStartValue" SG_ 811 GoTEditHr_T_RqMnu 30;
BA_ "GenSigSendType" SG_ 811 GoTEditHr_T_RqMnu 3;
BA_ "U_T6_MCA_MY2020_Rx" SG_ 811 GoTEditHr_T_RqMnu 1;
BA_ "ECGUsedRxSignal" SG_ 811 GoTEditHr_T_RqMnu 1;
BA_ "U_CD542_MY2021_Rx" SG_ 811 GoTEditHr_T_RqMnu 1;
BA_ "U_U55X_MY2022_Rx" SG_ 811 GoTEditHr_T_RqMnu 1;
BA_ "U_T6_MCA_MY2020_Tx" SG_ 811 GoTEditHr_T_RqMnu 1;
BA_ "U_CD542_MY2021_Tx" SG_ 811 GoTEditHr_T_RqMnu 1;
BA_ "U_U55X_MY2022_Tx" SG_ 811 GoTEditHr_T_RqMnu 1;
BA_ "U_T6_MCA_MY2020_Rx" SG_ 543 TeltalWarnData_No_Actl 1;
BA_ "ECGUsedRxSignal" SG_ 543 TeltalWarnData_No_Actl 1;
BA_ "U_CD542_MY2021_Rx" SG_ 543 TeltalWarnData_No_Actl 1;
BA_ "U_U55X_MY2022_Rx" SG_ 543 TeltalWarnData_No_Actl 1;
BA_ "U_T6_MCA_MY2020_Tx" SG_ 543 TeltalWarnData_No_Actl 1;
BA_ "U_CD542_MY2021_Tx" SG_ 543 TeltalWarnData_No_Actl 1;
BA_ "U_U55X_MY2022_Tx" SG_ 543 TeltalWarnData_No_Actl 1;
BA_ "WakeupSignal" SG_ 563 NtfyDrvTrgtDist_L2_Rq 1;
BA_ "GenSigStartValueInteger" SG_ 563 NtfyDrvTrgtDist_L2_Rq 1;
BA_ "GenSigStartValue" SG_ 563 NtfyDrvTrgtDist_L2_Rq 8190;
BA_ "GenSigSendType" SG_ 563 NtfyDrvTrgtDist_L2_Rq 3;
BA_ "ECGUsedTxSignal" SG_ 563 NtfyDrvTrgtDist_L2_Rq 1;
BA_ "U_CD542_MY2021_Tx" SG_ 563 NtfyDrvTrgtDist_L2_Rq 1;
BA_ "GenSigSendType" SG_ 563 BattChrgStrtStop_D_Rq 3;
BA_ "U_T6_MCA_MY2020_Tx" SG_ 563 BattChrgStrtStop_D_Rq 1;
BA_ "ECGUsedTxSignal" SG_ 563 BattChrgStrtStop_D_Rq 1;
BA_ "U_CD542_MY2021_Tx" SG_ 563 BattChrgStrtStop_D_Rq 1;
BA_ "U_U55X_MY2022_Tx" SG_ 563 BattChrgStrtStop_D_Rq 1;
BA_ "GenSigSendType" SG_ 563 DrvBhavWarn_B_Rq 3;
BA_ "U_T6_MCA_MY2020_Rx" SG_ 563 DrvBhavWarn_B_Rq 1;
BA_ "U_U55X_MY2022_Rx" SG_ 563 DrvBhavWarn_B_Rq 1;
BA_ "U_T6_MCA_MY2020_Tx" SG_ 563 DrvBhavWarn_B_Rq 1;
BA_ "ECGUsedTxSignal" SG_ 563 DrvBhavWarn_B_Rq 1;
BA_ "U_CD542_MY2021_Tx" SG_ 563 DrvBhavWarn_B_Rq 1;
BA_ "U_U55X_MY2022_Tx" SG_ 563 DrvBhavWarn_B_Rq 1;
BA_ "GenSigSendType" SG_ 563 OfbChrgSetSync_D_Rq 3;
BA_ "U_CD542_MY2021_Rx" SG_ 563 OfbChrgSetSync_D_Rq 1;
BA_ "U_U55X_MY2022_Rx" SG_ 563 OfbChrgSetSync_D_Rq 1;
BA_ "ECGUsedTxSignal" SG_ 563 OfbChrgSetSync_D_Rq 1;
BA_ "U_CD542_MY2021_Tx" SG_ 563 OfbChrgSetSync_D_Rq 1;
BA_ "U_U55X_MY2022_Tx" SG_ 563 OfbChrgSetSync_D_Rq 1;
BA_ "GenSigSendType" SG_ 563 KeyOffPwMde_D_Stat 3;
BA_ "U_T6_MCA_MY2020_Rx" SG_ 563 KeyOffPwMde_D_Stat 1;
BA_ "U_U55X_MY2022_Rx" SG_ 563 KeyOffPwMde_D_Stat 1;
BA_ "U_CD542_MY2021_Rx" SG_ 563 KeyOffPwMde_D_Stat 1;
BA_ "U_T6_MCA_MY2020_Tx" SG_ 563 KeyOffPwMde_D_Stat 1;
BA_ "ECGUsedTxSignal" SG_ 563 KeyOffPwMde_D_Stat 1;
BA_ "U_CD542_MY2021_Tx" SG_ 563 KeyOffPwMde_D_Stat 1;
BA_ "U_U55X_MY2022_Tx" SG_ 563 KeyOffPwMde_D_Stat 1;
BA_ "GenSigSendType" SG_ 563 ModemReset_D_Stat 3;
BA_ "U_CD542_MY2021_Rx" SG_ 563 ModemReset_D_Stat 1;
BA_ "U_T6_MCA_MY2020_Rx" SG_ 563 ModemReset_D_Stat 1;
BA_ "U_T6_MCA_MY2020_Tx" SG_ 563 ModemReset_D_Stat 1;
BA_ "ECGUsedTxSignal" SG_ 563 ModemReset_D_Stat 1;
BA_ "U_CD542_MY2021_Tx" SG_ 563 ModemReset_D_Stat 1;
BA_ "U_U55X_MY2022_Tx" SG_ 563 ModemReset_D_Stat 1;
BA_ "GenSigSendType" SG_ 563 FactoryReset_St 3;
BA_ "U_CD542_MY2021_Rx" SG_ 563 FactoryReset_St 1;
BA_ "U_T6_MCA_MY2020_Rx" SG_ 563 FactoryReset_St 1;
BA_ "U_T6_MCA_MY2020_Tx" SG_ 563 FactoryReset_St 1;
BA_ "ECGUsedTxSignal" SG_ 563 FactoryReset_St 1;
BA_ "U_CD542_MY2021_Tx" SG_ 563 FactoryReset_St 1;
BA_ "U_U55X_MY2022_Tx" SG_ 563 FactoryReset_St 1;
BA_ "GenSigStartValueInteger" SG_ 794 DcacFaltMsgTxt_D2_Rq 1;
BA_ "GenSigSendType" SG_ 794 DcacFaltMsgTxt_D2_Rq 3;
BA_ "U_T6_MCA_MY2020_Rx" SG_ 794 HvacBlwrRear_D_Stat_UB 1;
BA_ "U_U55X_MY2022_Rx" SG_ 794 HvacBlwrRear_D_Stat_UB 1;
BA_ "U_T6_MCA_MY2020_Rx" SG_ 794 HvacBlwrFront_D_Stat_UB 1;
BA_ "U_U55X_MY2022_Rx" SG_ 794 HvacBlwrFront_D_Stat_UB 1;
BA_ "GenSigSendType" SG_ 794 HvacBlwrRear_D_Stat 3;
BA_ "U_T6_MCA_MY2020_Rx" SG_ 794 HvacBlwrRear_D_Stat 1;
BA_ "U_U55X_MY2022_Rx" SG_ 794 HvacBlwrRear_D_Stat 1;
BA_ "GenSigSendType" SG_ 794 HvacBlwrFront_D_Stat 3;
BA_ "U_T6_MCA_MY2020_Rx" SG_ 794 HvacBlwrFront_D_Stat 1;
BA_ "U_U55X_MY2022_Rx" SG_ 794 HvacBlwrFront_D_Stat 1;
BA_ "U_T6_MCA_MY2020_Rx" SG_ 794 SpotLghtLeft_D_Stat_UB 1;
BA_ "U_CD542_MY2021_Rx" SG_ 794 SpotLghtLeft_D_Stat_UB 1;
BA_ "U_U55X_MY2022_Rx" SG_ 794 SpotLghtLeft_D_Stat_UB 1;
BA_ "U_T6_MCA_MY2020_Rx" SG_ 794 SpotLghtRight_D_Stat_UB 1;
BA_ "U_CD542_MY2021_Rx" SG_ 794 SpotLghtRight_D_Stat_UB 1;
BA_ "U_U55X_MY2022_Rx" SG_ 794 SpotLghtRight_D_Stat_UB 1;
BA_ "GenSigSendType" SG_ 794 SpotLghtRight_D_Stat 3;
BA_ "U_T6_MCA_MY2020_Rx" SG_ 794 SpotLghtRight_D_Stat 1;
BA_ "U_CD542_MY2021_Rx" SG_ 794 SpotLghtRight_D_Stat 1;
BA_ "U_U55X_MY2022_Rx" SG_ 794 SpotLghtRight_D_Stat 1;
BA_ "GenSigSendType" SG_ 794 SpotLghtLeft_D_Stat 3;
BA_ "U_T6_MCA_MY2020_Rx" SG_ 794 SpotLghtLeft_D_Stat 1;
BA_ "U_CD542_MY2021_Rx" SG_ 794 SpotLghtLeft_D_Stat 1;
BA_ "U_U55X_MY2022_Rx" SG_ 794 SpotLghtLeft_D_Stat 1;
BA_ "U_CD542_MY2021_Rx" SG_ 587 PHONE_RDISP2_WORD_Rx 1;
BA_ "U_U55X_MY2022_Rx" SG_ 587 PHONE_RDISP2_WORD_Rx 1;
BA_ "U_T6_MCA_MY2020_Tx" SG_ 587 PHONE_RDISP2_WORD_Rx 1;
BA_ "U_U55X_MY2022_Tx" SG_ 587 PHONE_RDISP2_WORD_Rx 1;
BA_ "U_T6_MCA_MY2020_Rx" SG_ 579 PHONE_RDISP2_WORD_Tx 1;
BA_ "U_U55X_MY2022_Rx" SG_ 579 PHONE_RDISP2_WORD_Tx 1;
BA_ "U_T6_MCA_MY2020_Tx" SG_ 579 PHONE_RDISP2_WORD_Tx 1;
BA_ "U_CD542_MY2021_Tx" SG_ 579 PHONE_RDISP2_WORD_Tx 1;
BA_ "U_CD542_MY2021_Rx" SG_ 585 NAV_RDISP2_WORD_Rx 1;
BA_ "U_U55X_MY2022_Rx" SG_ 585 NAV_RDISP2_WORD_Rx 1;
BA_ "U_T6_MCA_MY2020_Tx" SG_ 585 NAV_RDISP2_WORD_Rx 1;
BA_ "U_U55X_MY2022_Tx" SG_ 585 NAV_RDISP2_WORD_Rx 1;
VAL_ 547 Audio_Amp_St 3 "On" 2 "Partial_Amp" 1 "Off" 0 "NoDataExists" ;
VAL_ 547 Chime_Alert_Chan2 2 "Reserved" 1 "Mute" 0 "Inactive" ;
VAL_ 547 AHU_Chime2_Active 63 "Chime_62" 4 "Chime_3" 3 "Chime_2" 2 "Chime_1" 1 "NoChime" 0 "Inactive" ;
VAL_ 547 AHU_Chime2_Not_Recognized 0 "Inactive" 1 "Chime_Not_Recognized" ;
VAL_ 547 Chime_Alert_Chan 2 "Reserved" 1 "Mute" 0 "Inactive" ;
VAL_ 547 AHU_Alert_Channel1 3 "Reserved" 2 "Muted" 1 "Initialize_for_prompt" 0 "Inactive" ;
VAL_ 547 AHU_Chime_Supported 3 "Not_Used" 2 "Not_Supported" 1 "Supported" 0 "Inactive" ;
VAL_ 547 AHU_Chime_Active 63 "Chime_62" 4 "Chime_3" 3 "Chime_2" 2 "Chime_1" 1 "NoChime" 0 "Inactive" ;
VAL_ 547 AHU_Chime_Not_Recognized 0 "Inactive" 1 "Chime_Not_Recognized" ;
VAL_ 547 ChimeId_No_Stat 255 "Id255" 254 "Id254" 253 "Id253" 252 "Id252" 251 "Id251" 250 "Id250" 249 "Id249" 248 "Id248" 247 "Id247" 246 "Id246" 245 "Id245" 244 "Id244" 243 "Id243" 242 "Id242" 241 "Id241" 240 "Id240" 239 "Id239" 238 "Id238" 237 "Id237" 236 "Id236" 235 "Id235" 234 "Id234" 233 "Id233" 232 "Id232" 231 "Id231" 230 "Id230" 229 "Id229" 228 "Id228" 227 "Id227" 226 "Id226" 225 "Id225" 224 "Id224" 223 "Id223" 222 "Id222" 221 "Id221" 220 "Id220" 219 "Id219" 218 "Id218" 217 "Id217" 216 "Id216" 215 "Id215" 214 "Id214" 213 "Id213" 212 "Id212" 211 "Id211" 210 "Id210" 209 "Id209" 208 "Id208" 207 "Id207" 206 "Id206" 205 "Id205" 204 "Id204" 203 "Id203" 202 "Id202" 201 "Id201" 200 "Id200" 199 "Id199" 198 "Id198" 197 "Id197" 196 "Id196" 195 "Id195" 194 "Id194" 193 "Id193" 192 "Id192" 191 "Id191" 190 "Id190" 189 "Id189" 188 "Id188" 187 "Id187" 186 "Id186" 185 "Id185" 184 "Id184" 183 "Id183" 182 "Id182" 181 "Id181" 180 "Id180" 179 "Id179" 178 "Id178" 177 "Id177" 176 "Id176" 175 "Id175" 174 "Id174" 173 "Id173" 172 "Id172" 171 "Id171" 170 "Id170" 169 "Id169" 168 "Id168" 167 "Id167" 166 "Id166" 165 "Id165" 164 "Id164" 163 "Id163" 162 "Id162" 161 "Id161" 160 "Id160" 159 "Id159" 158 "Id158" 157 "Id157" 156 "Id156" 155 "Id155" 154 "Id154" 153 "Id153" 152 "Id152" 151 "Id151" 150 "Id150" 149 "Id149" 148 "Id148" 147 "Id147" 146 "Id146" 145 "Id145" 144 "Id144" 143 "Id143" 142 "Id142" 141 "Id141" 140 "Id140" 139 "Id139" 138 "Id138" 137 "Id137" 136 "Id136" 135 "Id135" 134 "Id134" 133 "Id133" 132 "Id132" 131 "Id131" 130 "Id130" 129 "Id129" 128 "Id128" 127 "Id127" 126 "Id126" 125 "Id125" 124 "Id124" 123 "Id123" 122 "Id122" 121 "Id121" 120 "Id120" 119 "Id119" 118 "Id118" 117 "Id117" 116 "Id116" 115 "Id115" 114 "Id114" 113 "Id113" 112 "Id112" 111 "Id111" 110 "Id110" 109 "Id109" 108 "Id108" 107 "Id107" 106 "Id106" 105 "Id105" 104 "Id104" 103 "Id103" 102 "Id102" 101 "Id101" 100 "Id100" 99 "Id99" 98 "Id98" 97 "Id97" 96 "Id96" 95 "Id95" 94 "Id94" 93 "Id93" 92 "Id92" 91 "Id91" 90 "Id90" 89 "Id89" 88 "Id88" 87 "Id87" 86 "Id86" 85 "Id85" 84 "Id84" 83 "Id83" 82 "Id82" 81 "Id81" 80 "Id80" 79 "Id79" 78 "Id78" 77 "Id77" 76 "Id76" 75 "Id75" 74 "Id74" 73 "Id73" 72 "Id72" 71 "Id71" 70 "Id70" 69 "Id69" 68 "Id68" 67 "Id67" 66 "Id66" 65 "Id65" 64 "Id64" 63 "Id63" 62 "Id62" 61 "Id61" 60 "Id60" 59 "Id59" 58 "Id58" 57 "Id57" 56 "Id56" 55 "Id55" 54 "Id54" 53 "Id53" 52 "Id52" 51 "Id51" 50 "Id50" 49 "Id49" 48 "Id48" 47 "Id47" 46 "Id46" 45 "Id45" 44 "Id44" 43 "Id43" 42 "Id42" 41 "Id41" 40 "Id40" 39 "Id39" 38 "Id38" 37 "Id37" 36 "Id36" 35 "Id35" 34 "Id34" 33 "Id33" 32 "Id32" 31 "Id31" 30 "Id30" 29 "Id29" 28 "Id28" 27 "Id27" 26 "Id26" 25 "Id25" 24 "Id24" 23 "Id23" 22 "Id22" 21 "Id21" 20 "Id20" 19 "Id19" 18 "Id18" 17 "Id17" 16 "Id16" 15 "Id15" 14 "Id14" 13 "Id13" 12 "Id12" 11 "Id11" 10 "Id10" 9 "Id9" 8 "Id8" 7 "Id7" 6 "Id6" 5 "Id5" 4 "Id4" 3 "Id3" 2 "Id2" 1 "Id1" 0 "Inactive" ;
VAL_ 547 Chime2Id_No_Stat 255 "Id255" 254 "Id254" 253 "Id253" 252 "Id252" 251 "Id251" 250 "Id250" 249 "Id249" 248 "Id248" 247 "Id247" 246 "Id246" 245 "Id245" 244 "Id244" 243 "Id243" 242 "Id242" 241 "Id241" 240 "Id240" 239 "Id239" 238 "Id238" 237 "Id237" 236 "Id236" 235 "Id235" 234 "Id234" 233 "Id233" 232 "Id232" 231 "Id231" 230 "Id230" 229 "Id229" 228 "Id228" 227 "Id227" 226 "Id226" 225 "Id225" 224 "Id224" 223 "Id223" 222 "Id222" 221 "Id221" 220 "Id220" 219 "Id219" 218 "Id218" 217 "Id217" 216 "Id216" 215 "Id215" 214 "Id214" 213 "Id213" 212 "Id212" 211 "Id211" 210 "Id210" 209 "Id209" 208 "Id208" 207 "Id207" 206 "Id206" 205 "Id205" 204 "Id204" 203 "Id203" 202 "Id202" 201 "Id201" 200 "Id200" 199 "Id199" 198 "Id198" 197 "Id197" 196 "Id196" 195 "Id195" 194 "Id194" 193 "Id193" 192 "Id192" 191 "Id191" 190 "Id190" 189 "Id189" 188 "Id188" 187 "Id187" 186 "Id186" 185 "Id185" 184 "Id184" 183 "Id183" 182 "Id182" 181 "Id181" 180 "Id180" 179 "Id179" 178 "Id178" 177 "Id177" 176 "Id176" 175 "Id175" 174 "Id174" 173 "Id173" 172 "Id172" 171 "Id171" 170 "Id170" 169 "Id169" 168 "Id168" 167 "Id167" 166 "Id166" 165 "Id165" 164 "Id164" 163 "Id163" 162 "Id162" 161 "Id161" 160 "Id160" 159 "Id159" 158 "Id158" 157 "Id157" 156 "Id156" 155 "Id155" 154 "Id154" 153 "Id153" 152 "Id152" 151 "Id151" 150 "Id150" 149 "Id149" 148 "Id148" 147 "Id147" 146 "Id146" 145 "Id145" 144 "Id144" 143 "Id143" 142 "Id142" 141 "Id141" 140 "Id140" 139 "Id139" 138 "Id138" 137 "Id137" 136 "Id136" 135 "Id135" 134 "Id134" 133 "Id133" 132 "Id132" 131 "Id131" 130 "Id130" 129 "Id129" 128 "Id128" 127 "Id127" 126 "Id126" 125 "Id125" 124 "Id124" 123 "Id123" 122 "Id122" 121 "Id121" 120 "Id120" 119 "Id119" 118 "Id118" 117 "Id117" 116 "Id116" 115 "Id115" 114 "Id114" 113 "Id113" 112 "Id112" 111 "Id111" 110 "Id110" 109 "Id109" 108 "Id108" 107 "Id107" 106 "Id106" 105 "Id105" 104 "Id104" 103 "Id103" 102 "Id102" 101 "Id101" 100 "Id100" 99 "Id99" 98 "Id98" 97 "Id97" 96 "Id96" 95 "Id95" 94 "Id94" 93 "Id93" 92 "Id92" 91 "Id91" 90 "Id90" 89 "Id89" 88 "Id88" 87 "Id87" 86 "Id86" 85 "Id85" 84 "Id84" 83 "Id83" 82 "Id82" 81 "Id81" 80 "Id80" 79 "Id79" 78 "Id78" 77 "Id77" 76 "Id76" 75 "Id75" 74 "Id74" 73 "Id73" 72 "Id72" 71 "Id71" 70 "Id70" 69 "Id69" 68 "Id68" 67 "Id67" 66 "Id66" 65 "Id65" 64 "Id64" 63 "Id63" 62 "Id62" 61 "Id61" 60 "Id60" 59 "Id59" 58 "Id58" 57 "Id57" 56 "Id56" 55 "Id55" 54 "Id54" 53 "Id53" 52 "Id52" 51 "Id51" 50 "Id50" 49 "Id49" 48 "Id48" 47 "Id47" 46 "Id46" 45 "Id45" 44 "Id44" 43 "Id43" 42 "Id42" 41 "Id41" 40 "Id40" 39 "Id39" 38 "Id38" 37 "Id37" 36 "Id36" 35 "Id35" 34 "Id34" 33 "Id33" 32 "Id32" 31 "Id31" 30 "Id30" 29 "Id29" 28 "Id28" 27 "Id27" 26 "Id26" 25 "Id25" 24 "Id24" 23 "Id23" 22 "Id22" 21 "Id21" 20 "Id20" 19 "Id19" 18 "Id18" 17 "Id17" 16 "Id16" 15 "Id15" 14 "Id14" 13 "Id13" 12 "Id12" 11 "Id11" 10 "Id10" 9 "Id9" 8 "Id8" 7 "Id7" 6 "Id6" 5 "Id5" 4 "Id4" 3 "Id3" 2 "Id2" 1 "Id1" 0 "Inactive" ;
VAL_ 547 AHU_AdjChimVolSupp2_St 3 "NotUsed_1" 2 "Supported" 1 "NotSupported" 0 "Inactive" ;
VAL_ 547 AHU_AdjChimeVolSupp_St 3 "NotUsed_1" 2 "Supported" 1 "NotSupported" 0 "Inactive" ;
VAL_ 547 AhuDgtlChime_D_Stat 3 "NotUsed" 2 "Supported" 1 "NotSupported" 0 "Inactive" ;
VAL_ 732 ACU_CurrItemsInFMSL_St 255 "NoValidPreset" 0 "Invalid" ;
VAL_ 732 ACU_FunctionStatus_St 7 "RemoveDisc" 0 "Invalid" 1 "Reading" 2 "Loading" 3 "Loaded" 4 "Insert" 5 "PreparingToEject" 6 "Ejecting" ;
VAL_ 732 ACU_CurrFMSLPreset_St 255 "NoValidPreset" 0 "Invalid" ;
VAL_ 732 ACU_CurrPreset2_St 31 "NoActivePreset" 0 "Invalid" ;
VAL_ 732 ACU_StorePreset_St 31 "NotStoring" 0 "Invalid" ;
VAL_ 732 ACU_VoiceCommand_St 2 "NotOk" 1 "Ok" 0 "Invalid" ;
VAL_ 732 ACU_CurrMixPreset_St 31 "NoActivePreset" 0 "Invalid" ;
VAL_ 728 PrplSnd_D_Stat 3 "Faulty" 2 "Enabled" 1 "Disabled" 0 "Null" ;
VAL_ 728 ACU_AuxVolume_Up 1 "Update" 0 "NoUpdate" ;
VAL_ 728 ACU_RadioSeekMode_St 14 "PISeek" 0 "Invalid" 1 "SeekOff" 2 "AutoUp" 3 "AutoDown" 4 "ManSingleStepUp" 5 "ManSingleStepDown" 6 "ContManualUp" 7 "ContManualDown" 8 "ScanUp" 9 "ScanDown" 10 "PtySeekUp" 11 "PtySeekDown" 12 "Autostore" 13 "TpSeek" ;
VAL_ 728 ACU_Volume_Up 1 "Update" 0 "NoUpdate" ;
VAL_ 757 SdarsAudioRtng_D_Stat 3 "NotUsed" 2 "APIMStereoOut" 1 "X40l2SStereoOut" 0 "NotDetermined" ;
VAL_ 757 SpkrStdRight_D_Stat 3 "Faulty" 2 "Normal" 1 "NotPresent" 0 "Null" ;
VAL_ 757 SpkrStdLeft_D_Stat 3 "Faulty" 2 "Normal" 1 "NotPresent" 0 "Null" ;
VAL_ 757 SpkrStdCntr_D_Stat 3 "Faulty" 2 "Normal" 1 "NotPresent" 0 "Null" ;
VAL_ 757 SDARS_ChipControl_St 7 "NotUsed_2" 6 "NotUsed_1" 5 "Ready" 4 "ResetInProgress" 3 "PowerDownInProgress" 2 "PowerUpInProgress" 1 "Off" 0 "Null" ;
VAL_ 757 ACU_AutoStoreResult_St 2 "No_Station_Found" 1 "Inactive" 0 "Invalid" ;
VAL_ 757 ACU_DirectTune_St 2 "Valid_Station" 1 "Invalid_Station" 0 "Invalid" ;
VAL_ 757 ACU_RadioSeekMode2_St 16 "ContAutoDown" 15 "ContAutoUp" 14 "PISeek" 13 "TpSeek" 12 "Autostore" 11 "PtySeekDown" 10 "PtySeekUp" 9 "ScanDown" 8 "ScanUp" 7 "ContManualDown" 6 "ContManualUp" 5 "ManSingleStepDown" 4 "ManSingleStepUp" 3 "AutoDown" 2 "AutoUp" 1 "SeekOff" 0 "Invalid" ;
VAL_ 757 ACU_CurrTUBand_St 10 "SAT2" 9 "SAT1" 8 "DAB2" 7 "DAB1" 6 "Fm3" 5 "AmAst" 4 "Am" 3 "FmAst" 2 "Fm2" 1 "Fm1" 0 "Invalid" 13 "reserved1" 15 "reserved_last" 12 "DAB3" 11 "SAT3" ;
VAL_ 734 ACU_ActServiceLink_St 3 "reserved" 2 "FM2DAB" 1 "DAB2FM" 0 "Invalid" ;
VAL_ 734 ACU_CurrTUDRService2_St 7 "last_reserved" 5 "reserved" 4 "DabNotAvailable" 3 "ServiceAvailable" 2 "ServiceNotAvailable" 1 "SyncEnsemble" 0 "Invalid" ;
VAL_ 734 ACU_ComTUSIDValid_St 1 "Validation" 0 "Invalid" ;
VAL_ 734 ACU_CurrTUDRService_St 3 "ServiceAvailable" 2 "ServiceNotAvailable" 1 "SyncEnsemble" 0 "Invalid" ;
VAL_ 734 ACU_CurrTURadioBand_St 12 "reserved" 11 "SAT3" 10 "SAT2" 15 "reserved_last" 9 "SAT1" 8 "DAB2" 7 "DAB1" 6 "Fm3" 5 "AmAst" 4 "Am" 3 "FmAst" 2 "Fm2" 1 "Fm1" 0 "Invalid" ;
VAL_ 734 ACU_CurrTUServiceLink_St 3 "reserved" 2 "Inactive" 1 "Active" 0 "Invalid" ;
VAL_ 759 Avail_HD_Chan_Valid 1 "Valid" 0 "Invalid" ;
VAL_ 759 Avail_HD_Chan_St_7 1 "Available" 0 "NotAvailable" ;
VAL_ 759 Avail_HD_Chan_St_6 1 "Available" 0 "NotAvailable" ;
VAL_ 759 Avail_HD_Chan_St_5 1 "Available" 0 "NotAvailable" ;
VAL_ 759 Avail_HD_Chan_St_4 1 "Available" 0 "NotAvailable" ;
VAL_ 759 Avail_HD_Chan_St_3 1 "Available" 0 "NotAvailable" ;
VAL_ 759 Avail_HD_Chan_St_2 1 "Available" 0 "NotAvailable" ;
VAL_ 759 Avail_HD_Chan_St_1 1 "Available" 0 "NotAvailable" ;
VAL_ 759 ACM_StationListScanSt 1 "Scan_Cancelled" ;
VAL_ 759 ACM_TagMode 2 "On" 1 "Off" 0 "Inactive" ;
VAL_ 759 ACM_RBDSMode 2 "On" 1 "Off" 0 "Inactive" ;
VAL_ 759 NumofHDMulticastChans_St 7 "Multicast_Available_7" 6 "Multicast_Available_6" 5 "Multicast_Available_5" 4 "Multicast_Available_4" 3 "Multicast_Available_3" 2 "Multicast_Available_2" 1 "Multicast_Available_1" 0 "zero" ;
VAL_ 759 ACM_HDModeStatus 2 "On" 1 "Off" 0 "Inactive" ;
VAL_ 759 ACM_HDChanStatus 4 "Not_Found" 3 "Not_Multicast" 2 "Acquired" 1 "Acquiring" ;
VAL_ 759 ACM_CurrentHDMulticast_St 7 "7" 6 "6" 5 "5" 4 "4" 3 "3" 2 "2" 1 "1" 0 "0" ;
VAL_ 144 SetTimeFormat 3 "NotUsed" 2 "_24h_mode" 1 "_12h_mode" 0 "Inactive" ;
VAL_ 144 TimeAdjustRequest 0 "NoTimeAdjustRequest" 1 "TimeAdjustRequest" ;
VAL_ 144 DateAdjustRequest 0 "NoDateAdjustRequest" 1 "DateAdjustRequest" ;
VAL_ 851 ConsLongTerm_No_Dsply 4095 "Faulty" 4094 "No_Data_Exists" ;
VAL_ 851 ConsUnitIPC_D_Dsply 15 "Reserved_15" 14 "Reserved_14" 13 "Reserved_13" 12 "Reserved_12" 11 "MPG_Hi-Res" 10 "miles_gallon__UK_" 9 "km_L_" 8 "Liters___100_km" 7 "Miles___Gallon" 6 "Whr___km_" 5 "Whr___mi_" 4 "miles_gallon__UK_" 2 "Liters___100_km" 1 "Miles___Gallon__US_" 0 "Invalid" 3 "km_L" ;
VAL_ 851 ConsAvgTrip_No_Dsply 4095 "Faulty" 4094 "No_Data_Exists" ;
VAL_ 792 ElTrip_L_Dsply 65535 "Fault" 65534 "No_Data_Exists" ;
VAL_ 792 ElLongTerm_L_Dsply 16777215 "Fault" 16777214 "No_Data_Exists" ;
VAL_ 787 VehElSurpStat_L_Dsply 8191 "Faulty" 8190 "Data_Not_Available" ;
VAL_ 787 TripSum_E_Dsply 511 "_Faulty" 510 "Data_Not_Available" ;
VAL_ 787 TripSum_L_Dsply 65535 "Faulty" 65534 "Data_Not_Available__" ;
VAL_ 504 Mc_AudioSourceSel_Rq 4 "Reserved" 5 "SDcard" 3 "USB" 2 "BTAudio" 1 "CD" 0 "Inactive" ;
VAL_ 504 Mc_CutItem_Rq 3 "Inactive" 2 "ThreeQuarterFromBeginOneQ" 1 "End" 0 "Beginning" ;
VAL_ 410 MyKey_e911Override_St 2 "On" 1 "Off" 0 "No_Data_Exists" ;
VAL_ 410 DoNotDisturbOveride_St 2 "On" 1 "Off" 0 "No_Data_Exists" ;
VAL_ 1124 GPS_Vdop 31 "Invalid" 30 "Unknown" ;
VAL_ 1124 GPS_Speed 255 "Invalid" 254 "Unknown" ;
VAL_ 1124 GPS_Sat_num_in_view 31 "Invalid" 30 "Unknown" ;
VAL_ 1124 GPS_MSL_altitude 4095 "Fault" 4094 "Unknown" ;
VAL_ 1124 GPS_Heading 65535 "Fault" 65534 "Unknown" ;
VAL_ 1124 GPS_Hdop 31 "Invalid" 30 "Unknown" ;
VAL_ 1124 GPS_dimension 2 "_3D" 1 "_2D" 0 "No_Fix" ;
VAL_ 1123 GpsUtcYr_No_Actl 31 "Fault" ;
VAL_ 1123 GpsUtcMnth_No_Actl 15 "Fault" ;
VAL_ 1123 GPS_UTC_seconds 63 "Fault" 62 "Unknown" ;
VAL_ 1123 GPS_UTC_minutes 63 "Fault" 62 "Unknown" ;
VAL_ 1123 GPS_UTC_hours 31 "Invalid" 30 "Unknown" ;
VAL_ 1123 GPS_Pdop 31 "Invalid" 30 "Unknown" ;
VAL_ 1123 GPS_Compass_direction 7 "NorthWest" 6 "West" 5 "SouthWest" 4 "South" 3 "SouthEast" 2 "East" 1 "NorthEast" 0 "North" ;
VAL_ 1123 GPS_Actual_vs_Infer_pos 1 "Inferred_Position" 0 "Actual_Postition" ;
VAL_ 1123 Gps_B_Falt 1 "Yes" 0 "No" ;
VAL_ 1122 GpsHsphLongEast_D_Actl 0 "Invalid" 1 "Eastern" 2 "Western" 3 "Fault" ;
VAL_ 1122 GpsHsphLattSth_D_Actl 3 "Fault" 2 "Northern" 1 "Southern" 0 "Invalid" ;
VAL_ 1122 GPS_Longitude_Minutes 63 "Fault" 62 "Unknown" ;
VAL_ 1122 GPS_Longitude_Min_dec 16383 "Invalid" 16382 "Unknown" ;
VAL_ 1122 GPS_Longitude_Degrees 511 "Fault" 510 "Unknown" ;
VAL_ 1122 GPS_Latitude_Minutes 63 "Fault" 62 "Unknown" ;
VAL_ 1122 GPS_Latitude_Min_dec 16383 "Invalid" 16382 "Unknown" ;
VAL_ 1122 GPS_Latitude_Degrees 255 "Invalid" 254 "Unknown" ;
VAL_ 1131 EsaOn_B_Stat_UB 1 "Fresh_data" 0 "Unchanged_data" ;
VAL_ 1131 EsaOn_B_Stat 1 "On" 0 "Off" ;
VAL_ 1131 WiprFrontSwtch_D_Stat 15 "NotUsed6" 14 "NotUsed5" 13 "NotUsed4" 12 "NotUsed3" 11 "NotUsed2" 10 "NotUsed1" 9 "PositionNotDetermined" 8 "High" 7 "Low" 6 "Position6" 5 "Position5" 4 "Position4" 3 "Position3" 2 "Position2" 1 "Position1" 0 "Off" ;
VAL_ 1131 HeadLghtHiOn_B_StatAhb_UB 1 "Fresh_data" 0 "Unchanged_data" ;
VAL_ 1131 HeadLghtHiOn_B_StatAhb 1 "On" 0 "Off" ;
VAL_ 1131 AhbStat_B_Dsply_UB 1 "Fresh_data" 0 "Unchanged_data" ;
VAL_ 1131 AhbStat_B_Dsply 1 "On" 0 "Off" ;
VAL_ 1131 WiprFrontSwtch_D_Stat_UB 1 "Fresh_data" 0 "Unchanged_data" ;
VAL_ 1131 RearDiffSrvcRqd_B_Rq_UB 1 "Fresh_data" 0 "Unchanged_data" ;
VAL_ 1131 PtLatchActv_B_RqBcm_UB 1 "Fresh_data" 0 "Unchanged_data" ;
VAL_ 1131 RearDiffSrvcRqd_B_Rq 1 "On" 0 "Off" ;
VAL_ 1131 PtLatchActv_B_RqBcm 1 "On" 0 "Off" ;
VAL_ 1136 ActvFrontSteMsgTxt_D_Rq_UB 1 "Fresh_data" 0 "Unchanged_data" ;
VAL_ 1136 ActvFrontSteMsgTxt_D_Rq 7 "Message7" 6 "Message6" 5 "Message5" 4 "Message4" 3 "Message3" 2 "Message2" 1 "Message1" 0 "NoMessage" ;
VAL_ 1136 GboxOil_Te_Actl_UB 1 "Fresh_data" 0 "Unchanged_data" ;
VAL_ 1136 GboxOil_Te_Actl 255 "Faulty" 254 "NoDataExists" ;
VAL_ 1136 EngOff_T_Actl_UB 1 "Fresh_data" 0 "Unchanged_data" ;
VAL_ 1136 EngOff_T_Actl 65535 "Invalid" ;
VAL_ 1136 AirSuspMsgTxt_D_Rq_UB 1 "Fresh_data" 0 "Unchanged_data" ;
VAL_ 1136 AirSusp_D_Stat_UB 1 "Fresh_data" 0 "Unchanged_data" ;
VAL_ 1136 AirSusp_D_Stat 3 "NotUsed" 2 "On" 1 "Off" 0 "Null" ;
VAL_ 1136 AirSuspMsgTxt_D_Rq 3 "NotUsed" 2 "Faulty" 1 "Override" 0 "NoMessage" ;
VAL_ 1136 BrkLineLck_D_Stat_UB 1 "Fresh_data" 0 "Unchanged_data" ;
VAL_ 1136 BrkLineLck_D_Stat 7 "NotUsed_3" 6 "NotUsed_2" 5 "NotUsed_1" 4 "NotAvailable" 3 "Off" 2 "Engaged" 1 "Initiated" 0 "Available" ;
VAL_ 1136 SnowPlowMde_B_Enbl 1 "Enable" 0 "Disable" ;
VAL_ 1136 SnowPlowMde_B_Enbl_UB 1 "Fresh_data" 0 "Unchanged_data" ;
VAL_ 1106 TrlrSnsId_No_Actl -1 "Faulty_FFFFFFFFFFFF" -2 "NoDataExists_FFFFFFFFFFFE" ;
VAL_ 1086 AwdPtu_Te_Actl 255 "Faulty" ;
VAL_ 1086 FuelPumpPwr_B_Rq 1 "On" 0 "Off" ;
VAL_ 1086 ElLoadCtl_D_Rq 7 "Unused3" 6 "Unused2" 5 "Unused1" 4 "HoldAllDrvrInvisibleLoads" 3 "StdDriverInvisibleLoadsOn" 2 "AllDriverInvisibleLoadsOn" 1 "All_Possible_Loads_Off" 0 "No_Request" ;
VAL_ 817 ChildLckMde_B_Stat 1 "Enable" 0 "Disable" ;
VAL_ 817 VehLckInd_D_Rq 3 "NotUsed" 2 "On_Day" 1 "On_Night" 0 "Off" ;
VAL_ 817 DrTgateOpen_B_Rq 1 "Open" 0 "Null" ;
VAL_ 817 DrTgateExtSwMde_B_Stat 1 "Enable" 0 "Disable" ;
VAL_ 817 Remote_Device_Feedback 7 "Unused3" 6 "Unused2" 5 "Unused1" 4 "Shutdown" 3 "Running" 2 "Starting" 1 "Acknowledge" 0 "Null" ;
VAL_ 817 Veh_Lock_Requestor 31 "Walk_Away_Locking" 30 "Remote_Park_Assist" 29 "DoorsOffToOn_Smart_Unlock" 28 "Rgtm_Shutlock_Switch" 27 "Boundary_Alert" 26 "Transit_Vehicle_Relock" 25 "Transit_Cargo_Relock" 24 "Transit_Ajar_Lock" 23 "Diagnostics" 22 "Console_Lock" 21 "Child_Lock" 20 "Double_Lock" 19 "Passive_Pasenger" 18 "Passive_Driver" 17 "Slam_Lock_Protect" 16 "SYNC" 15 "Passport" 14 "Passive_Smart_Unlock" 13 "Autorelock" 12 "RemoteStart" 0 "Null" 1 "Autolock" 11 "Smart_Unlock" 10 "Sliding_Door" 9 "Passive" 8 "Remote" 7 "Programming" 6 "Powerslide" 5 "Keypad" 4 "Key_Cylinder" 3 "Interior" 2 "Auto_Unlock" ;
VAL_ 817 R_Pwr_Sliding_Dr_Rqst 1 "Active" 0 "Null" ;
VAL_ 817 Power_Liftgate_Rqst 1 "Active" 0 "Null" ;
VAL_ 817 Power_Decklid_Rqst 1 "Active" 0 "Null" ;
VAL_ 817 L_Pwr_Sliding_Dr_Rqst 1 "Active" 0 "Null" ;
VAL_ 817 Veh_Lock_Sub_Id 15 "Unused7" 14 "Unused6" 13 "Unused5" 12 "Unused4" 11 "Unused3" 10 "Unused2" 9 "Unused1" 8 "Customer_8" 7 "Customer_7" 6 "Customer_6" 5 "Customer_5" 4 "Customer_4" 3 "Customer_3" 2 "Customer_2" 1 "Customer_1" 0 "Null" ;
VAL_ 817 Veh_Lock_Status 3 "UNLOCK_DRV" 2 "UNLOCK_ALL" 1 "LOCK_ALL" 0 "LOCK_DBL" ;
VAL_ 817 ChildLck_D_Dsply 3 "NOT_SUPPORTED" 2 "ERROR" 1 "CHILD_UNLOCK" 0 "CHILD_LOCK" ;
VAL_ 817 WindowLockout_B_Stat 1 "Locked" 0 "Unlock" ;
VAL_ 817 Lockmsgtxt_D_Rq 7 "MSG7" 6 "MSG6" 5 "MSG5" 4 "MSG4" 3 "MSG3" 2 "MSG2" 1 "MSG1" 0 "NO_WARNING" ;
VAL_ 817 FobComm_D_Stat 3 "NotUsed" 2 "RemEngStartOK" 1 "RemEngStartFail" 0 "Null" ;
VAL_ 817 LockInhibit 1 "Inhibit" 0 "No_Inhibit" ;
VAL_ 611 AwdTerrMdeChng_D_Rdy 7 "Fault" 6 "Undefined_2" 5 "Undefined_1" 4 "ModeUnavailDrInputRqd" 3 "SpOpModes_NotSupported" 2 "ModeUnavailDynamicCond" 1 "Module_In_Initialization" 0 "Mode_Change_Available" ;
VAL_ 611 AwdTerrMde_D_Actl 7 "Fail_Safe_Default" 6 "Dynamic_Mode" 5 "Rock_Crawl_Mode" 4 "Mud_Ruts_Mode" 3 "Sand_Mode" 2 "Undefined" 1 "Low_Mu_Mode" 0 "Special_Operating_Mode_Off" ;
VAL_ 611 AwdSys_D_Stat 3 "Faulty" 2 "NotUsed" 1 "_4x4_L_H_Active" 0 "_4x4_L_H_Inactive" ;
VAL_ 611 AwdStat_D_RqDsply 31 "Rear_Diff_Lock_Not_Avail" 30 "_4wd_Lock_Required" 29 "Cfg_Perf_Redc_See_Manual" 28 "To_Engage_4x4_Release_Aped" 27 "To_Engage_4x4_Slow_To_3MPH" 26 "Shift_To_Neutral" 25 "Lkr_Mode_Unavail_TMS" 24 " _4x4_Mode_Unavail_TMS" 23 "Out_of_4Low_Crawl" 22 "AWD_PTU_Oil_Changed" 21 "Change_AWD_PTU_Oil" 20 "Neutral_Tow_Disabled" 19 "Neutral_Tow_Enabled" 18 "AWD_OFF" 17 "_4x4_Off_Road_Speed" 16 "_4x4_Extreme_Off_Road_Mode" 15 "_4x4_Exiting_Off_Road" 14 "_4x4_Off_Road_Mode" 10 "_4x4_Locked_Temporarily" 9 "Shift_In_Progress" 13 "Blocked_Shift_Assist" 12 "_4x4_Auto_Restored" 11 "_4x4_Disabled_Temporarily" 7 "Out_of_4Low__Neutral" 6 "Out_of_4Low__Brake" 5 "Out_of_4Low__Speed" 4 "Into_4Low__Clutch" 3 "Into_4Low__Neutral" 2 "Into_4Low__Brake" 1 "Into_4Low__Speed" 0 "Normal__No_Message" 8 "Out_of_4Low__Clutch" ;
VAL_ 611 AwdLck_D_Stat 9 "Undefined" 8 "Under_External_Torque_Ctrl" 7 "Torque_Limited_by_Cmd" 6 "Fully_Locked_by_Cmd" 5 "Disabled" 4 "Warning" 3 "Fault" 2 "Inactive" 1 "Completely_Opened_by_Cmd" 0 "OK" ;
VAL_ 611 AwdSrvcRqd_B_Rq 1 "On" 0 "Off" ;
VAL_ 611 AwdLck_Tq_Rq 4095 "Fault" 4094 "Unknown" ;
VAL_ 611 AwdOffRoadMode_D_Stats 3 "Invalid" 2 "Extreme_Off_Road" 1 "Off_Road" 0 "Normal_Mode" ;
VAL_ 611 AwdLoLamp_D_RqDsply 3 "Not_Used" 2 "Flash" 1 "On" 0 "Off" ;
VAL_ 611 AwdHiLamp_D_RqDsply 3 "Not_Used" 2 "Flash" 1 "On" 0 "Off" ;
VAL_ 611 AwdAutoLamp_D_RqDsply 3 "Not_Used" 2 "Flash" 1 "On" 0 "Off" ;
VAL_ 611 Awd2wdLamp_D_RqDsply 3 "Not_Used" 2 "Flash" 1 "On" 0 "Off" ;
VAL_ 611 AwdRnge_D_Actl 7 "Unknown" 6 "High_Range_2wd" 5 "High_Range_Auto" 4 "High_Range_Locked" 3 "Neutral" 2 "Low_Range_2wd" 1 "Low_Range_Auto" 0 "Low_Range_Locked" ;
VAL_ 611 NtrlTowAvail_B_Stat 1 "Available" 0 "NotAvailable" ;
VAL_ 611 AwdDrvMde_D_Stat 7 "Faulty" 6 "NotAvailable" 5 "RockCrawl" 4 "Baja" 3 "MudAndSand" 2 "Weather" 1 "Sport" 0 "Normal" ;
VAL_ 611 SelDrvMdeAwd_D_Stat 0 "NotAvailable" 1 "Available" 2 "TemporarilyNotAvailable" 3 "Faulty" ;
VAL_ 264 CabnAmb_Te_Actl_UB 1 "Fresh_data" 0 "Unchanged_data" ;
VAL_ 264 CabnAmb_Te_Actl 255 "Fault" ;
VAL_ 264 ChrgCordLck_D_Stat_UB 1 "Fresh_data" 0 "Unchanged_data" ;
VAL_ 264 ChrgCordLck_D_Stat 7 "Faulty" 6 "LockFail" 5 "UnlockFail" 4 "LockInProgress" 3 "UnlockInProgress" 2 "Lock" 1 "Unlock" 0 "Retain" ;
VAL_ 264 PwPckTqRdy_B_Dsply 1 "On" 0 "Off" ;
VAL_ 264 HtrnOvrTeLamp_B_Dsply_UB 1 "Fresh_data" 0 "Unchanged_data" ;
VAL_ 264 HtrnOvrTeLamp_B_Dsply 1 "On" 0 "Off" ;
VAL_ 264 PwPckTqRdy_B_Dsply_UB 1 "Fresh_data" 0 "Unchanged_data" ;
VAL_ 264 BpedDrvAppl_D_Actl 3 "_Not_Allowed" 2 "Driver_Braking" 1 "Driver_Not_Braking" 0 "Not_Allowed" ;
VAL_ 264 BpedDrvAppl_D_Actl_UB 1 "Fresh_data" 0 "Unchanged_data" ;
VAL_ 264 BattTracSoc_Pc_Dsply_UB 1 "Fresh_data" 0 "Unchanged_data" ;
VAL_ 264 BattTracSoc_Pc_Dsply 255 "Faulty" 254 "NoDataExists" ;
VAL_ 1114 TrailCtlSwtch_B_Stat2 1 "Pressed" 0 "Not_Pressed" ;
VAL_ 1114 TrlBrkInitOut_D_Rq 3 "Heavy" 2 "Medium" 1 "Light" 0 "Null" ;
VAL_ 968 RvltnMatchAllw_D_Rq 3 "RevolutionMatchDisabled" 2 "RevolutionMatchEnabled" 1 "ChangeWithDriveMode" 0 "NoSelection" ;
VAL_ 968 BrkDrvMde_D_Rq 7 "Faulty" 6 "RockCrawl" 5 "Baja" 4 "DragOrMudAndSand" 3 "Track" 2 "Snow_Wet" 1 "Sport" 0 "Normal" ;
VAL_ 968 LnchCtl_D_Rq 3 "NotUsed2" 2 "NotUsed1" 1 "LC_On" 0 "LC_Off" ;
VAL_ 968 CurrentColor_CmdGage 15 "NotUsed7" 14 "NotUsed6" 13 "NotUsed5" 12 "NotUsed4" 11 "NotUsed3" 10 "NotUsed2" 9 "NotUsed1" 8 "Null" 7 "Color7" 6 "Color6" 5 "Color5" 4 "Color4" 3 "Color3" 2 "Color2" 1 "Color1" 0 "Off" ;
VAL_ 968 BlendedColor_CmdGage 3 "NotUsed" 2 "Null" 1 "On" 0 "Off" ;
VAL_ 968 BlendColorRed_CmdGage 15 "NotUsed10" 14 "NotUsed9" 13 "NotUsed8" 12 "NotUsed7" 11 "NotUsed6" 10 "NotUsed5" 9 "NotUsed4" 8 "NotUsed3" 7 "NotUsed2" 6 "NotUsed1" 5 "_5" 4 "_4" 3 "_3" 2 "_2" 1 "_1" 0 "Null" ;
VAL_ 968 BlendColorGrn_CmdGage 15 "NotUsed10" 14 "NotUsed9" 13 "NotUsed8" 12 "NotUsed7" 11 "NotUsed6" 10 "NotUsed5" 9 "NotUsed4" 8 "NotUsed3" 7 "NotUsed2" 6 "NotUsed1" 5 "_5" 4 "_4" 3 "_3" 2 "_2" 1 "_1" 0 "Null" ;
VAL_ 968 BlendColorBlue_CmdGage 15 "NotUsed10" 14 "NotUsed9" 13 "NotUsed8" 12 "NotUsed7" 11 "NotUsed6" 10 "NotUsed5" 9 "NotUsed4" 8 "NotUsed3" 7 "NotUsed2" 6 "NotUsed1" 5 "_5" 4 "_4" 3 "_3" 2 "_2" 1 "_1" 0 "Null" ;
VAL_ 968 Dimming_Level_Cmd 3 "Low" 2 "Not_Used" 1 "High" 0 "Null" ;
VAL_ 968 Current_Color_Cmd 15 "NotUsed7" 14 "NotUsed6" 13 "NotUsed5" 12 "NotUsed4" 11 "NotUsed3" 10 "NotUsed2" 9 "NotUsed1" 8 "Null" 7 "Color7" 6 "Color6" 5 "Color5" 4 "Color4" 3 "Color3" 2 "Color2" 1 "Color1" 0 "Off" ;
VAL_ 968 BlendedColorRed_Cmd 15 "NotUsed10" 14 "NotUsed9" 13 "NotUsed8" 12 "NotUsed7" 11 "NotUsed6" 10 "NotUsed5" 9 "NotUsed4" 8 "NotUsed3" 7 "NotUsed2" 6 "NotUsed1" 5 "_5" 4 "_4" 3 "_3" 2 "_2" 1 "_1" 0 "Null" ;
VAL_ 968 BlendedColorGreen_Cmd 15 "NotUsed10" 14 "NotUsed9" 13 "NotUsed8" 12 "NotUsed7" 11 "NotUsed6" 10 "NotUsed5" 9 "NotUsed4" 8 "NotUsed3" 7 "NotUsed2" 6 "NotUsed1" 5 "_5" 4 "_4" 3 "_3" 2 "_2" 1 "_1" 0 "Null" ;
VAL_ 968 BlendedColorBlue_Cmd 15 "NotUsed10" 14 "NotUsed9" 13 "NotUsed8" 12 "NotUsed7" 11 "NotUsed6" 10 "NotUsed5" 9 "NotUsed4" 8 "NotUsed3" 7 "NotUsed2" 6 "NotUsed1" 5 "_5" 4 "_4" 3 "_3" 2 "_2" 1 "_1" 0 "Null" ;
VAL_ 968 BlendedColor_Cmd 3 "NotUsed" 2 "Null" 1 "On" 0 "Off" ;
VAL_ 968 SuspDrvMde_D_Rq 7 "Faulty" 6 "NotUsed2" 5 "NotUsed1" 4 "Drag" 3 "Track" 2 "Snow_Wet" 1 "Sport" 0 "Normal" ;
VAL_ 968 SlMde_D_Rq 3 "IsaNotConfigured" 2 "Manual_Mode" 1 "Auto_Mode" 0 "Null" ;
VAL_ 968 IsaOffst_D_Rq 15 "Faulty" 14 "Null" 13 "Thirteen" 12 "Twelve" 11 "Eleven" 10 "Ten" 9 "Nine" 8 "Eight" 7 "Seven" 6 "Six" 5 "Five" 4 "Four" 3 "Three" 2 "Two" 1 "One" 0 "Zero" ;
VAL_ 969 Dimming_Level_Stat 3 "Low" 2 "Not_Used" 1 "High" 0 "Null" ;
VAL_ 969 Current_Color_Stat 15 "NotUsed7" 14 "NotUsed6" 13 "NotUsed5" 12 "NotUsed4" 11 "NotUsed3" 10 "NotUsed2" 9 "NotUsed1" 8 "Null" 7 "Color7" 6 "Color6" 5 "Color5" 4 "Color4" 3 "Color3" 2 "Color2" 1 "Color1" 0 "Off" ;
VAL_ 969 BlendedColorRed_Stat 15 "NotUsed10" 14 "NotUsed9" 13 "NotUsed8" 12 "NotUsed7" 11 "NotUsed6" 10 "NotUsed5" 9 "NotUsed4" 8 "NotUsed3" 7 "NotUsed2" 6 "NotUsed1" 5 "_5" 4 "_4" 3 "_3" 2 "_2" 1 "_1" 0 "Null" ;
VAL_ 969 BlendedColorGreen_Stat 15 "NotUsed10" 14 "NotUsed9" 13 "NotUsed8" 12 "NotUsed7" 11 "NotUsed6" 10 "NotUsed5" 9 "NotUsed4" 8 "NotUsed3" 7 "NotUsed2" 6 "NotUsed1" 5 "_5" 4 "_4" 3 "_3" 2 "_2" 1 "_1" 0 "Null" ;
VAL_ 969 BlendedColorBlue_Stat 15 "NotUsed10" 14 "NotUsed9" 13 "NotUsed8" 12 "NotUsed7" 11 "NotUsed6" 10 "NotUsed5" 9 "NotUsed4" 8 "NotUsed3" 7 "NotUsed2" 6 "NotUsed1" 5 "_5" 4 "_4" 3 "_3" 2 "_2" 1 "_1" 0 "Null" ;
VAL_ 969 BlendedColor_Stat 3 "NotUsed" 2 "Null" 1 "On" 0 "Off" ;
VAL_ 969 TurnLampRrOut_B_Stat 1 "Out" 0 "Null" ;
VAL_ 969 TurnLampRlOut_B_Stat 1 "Out" 0 "Null" ;
VAL_ 1006 PersIndexIpmb_D_Actl 7 "Unused_3" 6 "Unused_2" 5 "Unused_1" 4 "Vehicle" 3 "PERS_4" 2 "PERS_3" 1 "PERS_2" 0 "PERS_1" ;
VAL_ 130 EngExhMdeQuiet_B_RqDrv2 1 "Pressed" 0 "Not_Pressed" ;
VAL_ 130 SteWhlSwtchHome_B_Stat 1 "Pressed" 0 "Not_Pressed" ;
VAL_ 130 SteWhlSwtchInfo_B_Stat 1 "Pressed" 0 "Not_Pressed" ;
VAL_ 130 SelDrvMdeSwtch_D_Stat4 3 "Faulty" 2 "SwitchState2" 1 "SwitchState1" 0 "NotPressed" ;
VAL_ 130 SelDrvMdeSwtch3_D_Stat4 3 "Faulty" 2 "Pressed" 1 "NotPressed" 0 "Null" ;
VAL_ 130 SelDrvMdeSwtch2_D_Stat4 3 "Faulty" 2 "Pressed" 1 "NotPressed" 0 "Null" ;
VAL_ 130 SelDrvMdeSwtch1_D_Stat4 3 "Faulty" 2 "Pressed" 1 "NotPressed" 0 "Null" ;
VAL_ 130 PoliceAux4Swtch_B_Stat 1 "Switch_Active" 0 "Switch_Not_Active" ;
VAL_ 130 PoliceAux3Swtch_B_Stat 1 "Switch_Active" 0 "Switch_Not_Active" ;
VAL_ 130 PoliceAux2Swtch_B_Stat 1 "Switch_Active" 0 "Switch_Not_Active" ;
VAL_ 130 PoliceAux1Swtch_B_Stat 1 "Switch_Active" 0 "Switch_Not_Active" ;
VAL_ 130 SteWhlSwtchView_B_Stat 1 "Pressed" 0 "Not_Pressed" ;
VAL_ 130 SteWhlSwtchSet_B_Stat 1 "Pressed" 0 "Not_Pressed" ;
VAL_ 130 SteWhlSwtchPhon_B_Stat 1 "Pressed" 0 "Not_Pressed" ;
VAL_ 130 SteWhlSwtchNav_B_Stat 1 "Pressed" 0 "Not_Pressed" ;
VAL_ 130 SteWhlSwtchMed_B_Stat 1 "Pressed" 0 "Not_Pressed" ;
VAL_ 130 SteWhlSwtchIod_B_Stat 1 "Pressed" 0 "Not_Pressed" ;
VAL_ 130 SteWhlSwtchHud_B_Stat 1 "Pressed" 0 "Not_Pressed" ;
VAL_ 130 SteWhlSwtchBack_B_Stat 1 "Pressed" 0 "Not_Pressed" ;
VAL_ 130 SteWhlSwtchMenu_B_Stat 1 "Pressed" 0 "Not_Pressed" ;
VAL_ 130 SteEffortInc_B_RqDrv 1 "Pressed" 0 "Not_Pressed" ;
VAL_ 130 SelDrvMdeInc_B_RqDrv 1 "Pressed" 0 "Not_Pressed" ;
VAL_ 130 SelDrvMdeDec_B_RqDrv 1 "Pressed" 0 "Not_Pressed" ;
VAL_ 130 SuspDampInc_B_RqDrv 1 "Pressed" 0 "Not_Pressed" ;
VAL_ 130 SteWhlSwtchUp_B_Stat 1 "Pressed" 0 "Not_Pressed" ;
VAL_ 130 SteWhlSwtchRght_B_Stat 1 "Pressed" 0 "Not_Pressed" ;
VAL_ 130 SteWhlSwtchOk_B_Stat 1 "Pressed" 0 "Not_Pressed" ;
VAL_ 130 SteWhlSwtchLeft_B_Stat 1 "Pressed" 0 "Not_Pressed" ;
VAL_ 130 SteWhlSwtchDown_B_Stat 1 "Pressed" 0 "Not_Pressed" ;
VAL_ 1244 Con_InfotainmentVer_St 1 "B299" 0 "invalid" ;
VAL_ 1243 Con_BTAud_InfotainmVer_St 1 "B299" 0 "invalid" ;
VAL_ 681 Con_DB1FilterConfig_St 31 "UnknownActive" 9 "Reserved" 8 "Podcast" 7 "Audiobook" 6 "Composer" 5 "Track" 4 "Genre" 3 "Album" 2 "Artist" 1 "Playlist" 0 "Root" ;
VAL_ 681 Con_DB1Filter3_St 1023 "All" 1022 "SIIndex_1022" 1 "SIIndex_1" 0 "NotEngaged" ;
VAL_ 681 Con_DB1Filter2_St 65535 "All" 65534 "SIIndex_65534" 1 "SIIndex_1" 0 "NotEngaged" ;
VAL_ 681 Con_DB1Filter1_St 65535 "All" 65534 "SIIndex_65534" 1 "SIIndex_1" 0 "NotEngaged" ;
VAL_ 741 Con_USB_Playtype_St 2 "Playlist" 1 "Folder" 0 "Invalid" ;
VAL_ 741 Con_ShowSWDLprogress_St 5 "ConSWUpdateSuccess" 4 "ConSWUpdateNotNecessary" 3 "ConSWUpdateFailed" 2 "ConSWUpdateInProgress" 1 "ConSWUpdateNotRunning" 0 "Invalid" ;
VAL_ 741 Con_iPod_IntroScan_St 3 "OnTheFolderSelGroup" 2 "OnTheDevice" 1 "Off" 0 "Invalid" ;
VAL_ 741 Con_iPod_Shuffle_St 3 "OnTheFolderSelGroup" 2 "OnTheDevice" 1 "Off" 0 "Invalid" ;
VAL_ 741 Con_iPod_Repeat_St 7 "Reserved2" 6 "Reserved1" 5 "Reserved" 4 "RepeatOnDevice" 3 "RepeatOnFolder" 2 "RepeatOnTrack" 1 "Off" 0 "Invalid" ;
VAL_ 741 Con_USB_Repeat_St 7 "Reserved2" 6 "Reserved1" 5 "Reserved" 4 "RepeatOnDevice" 3 "RepeatOnFolder" 2 "RepeatOnTrack" 1 "Off" 0 "Invalid" ;
VAL_ 741 Con_USB_IntroScan_St 3 "OnTheFolderSelGroup" 2 "OnTheDevice" 1 "Off" 0 "Invalid" ;
VAL_ 741 Con_USB_Shuffle_St 3 "OnTheFolderSelGroup" 2 "OnTheDevice" 1 "Off" 0 "Invalid" ;
VAL_ 741 Con_iPod_Error_St 8 "NoDataInFolder" 7 "NoRespFromDevice" 6 "UnableToRead" 5 "NoDataOnDevice" 4 "FileSysNotSupported" 3 "DeviceNotSupported" 2 "InvalidFile" 1 "NoError" 0 "Invalid" ;
VAL_ 741 Con_USB_Error_St 9 "USBHubNotSupported" 8 "NoDataInFolder" 7 "NoRespFromDevice" 6 "UnableToRead" 5 "NoDataOnDevice" 4 "FileSysNotSupported" 3 "DeviceNotSupported" 2 "InvalidFile" 1 "NoError" 0 "Invalid" ;
VAL_ 741 Con_iPod_FunctStatus_St 7 "Reserved2" 6 "Reserved1" 5 "Reserved" 4 "Reading" 3 "Ready" 2 "Initilization" 1 "Free" 0 "Invalid" ;
VAL_ 741 Con_USB_FunctStatus_St 7 "Reserved2" 6 "Reserved1" 5 "Reserved" 4 "Reading" 3 "Ready" 2 "Initilization" 1 "Free" 0 "Invalid" ;
VAL_ 741 Con_USB_OpMode_St 7 "FastRewind20" 6 "FastRewind10" 5 "FastForward20" 4 "FastForward10" 3 "Pause" 2 "Play" 1 "Stop" 0 "Invalid" ;
VAL_ 741 Con_iPod_OpMode_St 7 "FastRewind20" 6 "FastRewind10" 5 "FastForward20" 4 "FastForward10" 3 "Pause" 2 "Play" 1 "Stop" 0 "Invalid" ;
VAL_ 954 PosLghtFl_D_Stat 3 "Faulty" 2 "Outage" 1 "On" 0 "Off" ;
VAL_ 954 PosLghtFr_D_Stat 3 "Faulty" 2 "Outage" 1 "On" 0 "Off" ;
VAL_ 954 CargoLght_D_Stat 3 "NotUsed" 2 "Automatic" 1 "Manual" 0 "Null" ;
VAL_ 954 TlghtTestLght_D_Stat 7 "Error" 6 "AllOff" 5 "TestingReverseLights" 4 "TestingBrakeLights" 3 "TestingLeftTurnSignal" 2 "TestingRightTurnSignal" 1 "ParkingLightsIlluminated" 0 "Null" ;
VAL_ 954 LghtAmbDrvMde_B_Stat 1 "Automatic" 0 "Manual" ;
VAL_ 954 KeylessIdl_B_Stat 1 "Pressed" 0 "Not_Pressed" ;
VAL_ 954 PwRnngBoardPoll_D_Stat 3 "NotUsed" 2 "PkPresent" 1 "PkNotPresent" 0 "NotPolling" ;
VAL_ 954 PoliceDmngLvl_D_Stat 7 "NotUsed" 6 "Off_Night" 5 "Off_Day" 4 "Low1Night" 3 "Low1Day" 2 "Inactive" 1 "Decommissioned" 0 "Null" ;
VAL_ 954 TrlrHitchLamp_D_Stat 1 "On" 0 "Off" ;
VAL_ 954 LicPlateLght_B_Stat 1 "On" 0 "Off" ;
VAL_ 954 TrukBedLght_B_Stat 1 "On" 0 "Off" ;
VAL_ 954 VehWlcmFrwlMde_D_Stat 7 "IlluminatedExit" 6 "CourtesyLightingDelayExt" 5 "CourtesyLightingExtended" 4 "CourtesyLightingDelayAll" 3 "CourtesyLightingAll" 2 "IlluminatedEntry" 1 "Approach" 0 "Null" ;
VAL_ 954 PudSptLghtRight_D_Rq 3 "NotUsed" 2 "On" 1 "Off" 0 "Null" ;
VAL_ 954 PudSptLghtLeft_D_Rq 3 "NotUsed" 2 "On" 1 "Off" 0 "Null" ;
VAL_ 954 ExtLghtRight_D_Stat 3 "NotUsed" 2 "On" 1 "Off" 0 "Null" ;
VAL_ 954 VehWlcmFrwl_D_Stat 3 "RunStart" 2 "Farewell" 1 "Welcome" 0 "Null" ;
VAL_ 954 ExtLghtRear_D_Stat 3 "NotUsed" 2 "On" 1 "Off" 0 "Null" ;
VAL_ 954 ExtLghtLeft_D_Stat 3 "NotUsed" 2 "On" 1 "Off" 0 "Null" ;
VAL_ 954 ExtLghtAlrt_B_Rq 1 "Yes" 0 "No" ;
VAL_ 954 ExtLght_D_Falt 3 "Error" 2 "NoStationary" 1 "StartEngine" 0 "Null" ;
VAL_ 954 ExtLghtFront_D_Stat 3 "NotUsed" 2 "On" 1 "Off" 0 "Null" ;
VAL_ 954 TlghtTestPrecnd_D_Stat 7 "Error" 6 "NotStationary" 5 "InteractionPresent" 4 "PreconditionsPassed" 3 "BattSocLessThan75Percent" 2 "TailLightsOn" 1 "IgnitionNotOn" 0 "Null" ;
VAL_ 954 TlghtTest_D_Stat 3 "InProgress" 2 "Ended" 1 "Completed" 0 "Null" ;
VAL_ 125 VehRolComp_W_Actl 4094 "NoDataExists" 4095 "Fault" ;
VAL_ 125 VehVertComp_A_Actl 1022 "NoDataExists" 1023 "Fault" ;
VAL_ 125 BrkTot_Tq_RqArb 8191 "Fault" 8190 "Unknown" ;
VAL_ 125 BrkTot_Tq_Actl 8191 "Fault" 8190 "Unknown" ;
VAL_ 125 HsaStat_D_Actl 7 "Faulty" 6 "FaultyWithDriverIndication" 5 "SlowRelease" 4 "FastRelease" 3 "ActiveBrakePedalReleased" 2 "ActiveBrakePedalPressed" 1 "FindingGradient" 0 "Inactive" ;
VAL_ 1082 SldrrStat_B_Actl_UB 1 "Fresh_data" 0 "Unchanged_data" ;
VAL_ 1082 SldrrStat_B_Actl 1 "Ajar" 0 "Closed" ;
VAL_ 1082 SldrlStat_B_Actl_UB 1 "Fresh_data" 0 "Unchanged_data" ;
VAL_ 1082 SldrlStat_B_Actl 1 "Ajar" 0 "Closed" ;
VAL_ 1082 StabBarFaltMsgTxt_D_Rq_UB 1 "Fresh_data" 0 "Unchanged_data" ;
VAL_ 1082 StabBarCnnctLamp_D_Rq_UB 1 "Fresh_data" 0 "Unchanged_data" ;
VAL_ 1082 StabBarCnncMsgTxt_D_Rq_UB 1 "Fresh_data" 0 "Unchanged_data" ;
VAL_ 1082 StabBarFaltMsgTxt_D_Rq 3 "Message3" 2 "Message2" 1 "Message1" 0 "NoMessage" ;
VAL_ 1082 StabBarCnnctLamp_D_Rq 3 "Fast_Flash" 2 "Slow_Flash" 1 "On" 0 "Off" ;
VAL_ 1082 StabBarCnncMsgTxt_D_Rq 15 "Message15" 14 "Message14" 13 "Message13" 12 "Message12" 11 "Message11" 10 "Message10" 9 "Message9" 8 "Message8" 7 "Message7" 6 "Message6" 5 "Message5" 4 "Message4" 3 "Message3" 2 "Message2" 1 "Message1" 0 "NoMessage" ;
VAL_ 1115 HUD_TextMessage_Rq 3 "Cancel" 2 "Ignore" 1 "Listen" 0 "Invalid" ;
VAL_ 1115 HUD_BTIncomingCall_Rq 2 "DeclineIncomingCall" 1 "AcceptIncomingCall" 0 "Inactive" ;
VAL_ 1115 HUD_BTInCallOptions_Rq 6 "EndHoldCall" 5 "HoldCall" 4 "GotoHandsfreeMode" 3 "GotoPrivacyMode" 2 "JoinCalls" 1 "SwitchCalls" 0 "Inactive" ;
VAL_ 1115 HUD_BTEndTelService_Rq 1 "EndOngoingTelephonyCall" 0 "Inactive" ;
VAL_ 811 ExtLghtDsply_D_Stat 7 "NotUsed" 6 "PressToOn3" 5 "PressToOff3" 4 "PressToOn2" 3 "PressToOff2" 2 "PressToOn1" 1 "PressToOff1" 0 "Reset" ;
VAL_ 811 SpeedoMajorUnit_D_Confg 3 "NotUsed" 2 "Kph" 1 "Mph" 0 "Null" ;
VAL_ 811 ScMnSoc_Pc_RqMnu 127 "Faulty" 126 "NoDataExists" ;
VAL_ 811 ScEnbl_D_RqMnu 3 "NotUsed" 2 "On" 1 "Off" 0 "Null" ;
VAL_ 811 OnePdlDrvButtn_B_Falt 1 "Faulted" 0 "NotFaulted" ;
VAL_ 811 OnePdlDrvButtn_B_Stat 1 "Pressed" 0 "Not_Pressed" ;
VAL_ 811 LongTermReset_B_RqMnu 1 "On" 0 "Off" ;
VAL_ 811 DistToStopover_L_Actl 65535 "Faulty" ;
VAL_ 811 StopoverType_D_Stat 7 "Faulty" 6 "NotUsed_1" 5 "Other" 4 "Work" 3 "Home" 2 "ChargeStation" 1 "FinalDestination" 0 "Null" ;
VAL_ 811 ExtLghtRight_D_RqMnu 7 "NotUsed" 6 "PressToOn3" 5 "PressToOff3" 4 "PressToOn2" 3 "PressToOff2" 2 "PressToOn1" 1 "PressToOff1" 0 "Reset" ;
VAL_ 811 AutoLghtOvrrd_B_RqDrv 1 "Allowed" 0 "NotAllowed" ;
VAL_ 811 ExtLghtRear_D_RqMnu 7 "NotUsed" 6 "PressToOn3" 5 "PressToOff3" 4 "PressToOn2" 3 "PressToOff2" 2 "PressToOn1" 1 "PressToOff1" 0 "Reset" ;
VAL_ 811 ExtLghtLeft_D_RqMnu 7 "NotUsed" 6 "PressToOn3" 5 "PressToOff3" 4 "PressToOn2" 3 "PressToOff2" 2 "PressToOn1" 1 "PressToOff1" 0 "Reset" ;
VAL_ 811 ExtLghtFront_D_RqMnu 7 "NotUsed" 6 "PressToOn3" 5 "PressToOff3" 4 "PressToOn2" 3 "PressToOff2" 2 "PressToOn1" 1 "PressToOff1" 0 "Reset" ;
VAL_ 811 GoTEditMnte_T_RqMnu 15 "Faulty" 14 "NoDataExists" 13 "NotUsed_2" 12 "NotUsed_1" 11 "Minute_55" 10 "Minute_50" 9 "Minute_45" 8 "Minute_40" 7 "Minute_35" 6 "Minute_30" 5 "Minute_25" 4 "Minute_20" 3 "Minute_15" 2 "Minute_10" 1 "Minute_5" 0 "Minute_0" ;
VAL_ 811 GoTEditHr_T_RqMnu 31 "Faulty" 30 "NoDataExists" ;
VAL_ 563 NtfyDrvTrgtDist_L2_Rq 8191 "Faulty" 8190 "NoDataExists" ;
VAL_ 563 BattChrgStrtStop_D_Rq 3 "ReturnToSettings" 2 "StopCharge" 1 "StartCharge" 0 "NoNewRequest" ;
VAL_ 563 DrvBhavWarn_B_Rq 1 "On" 0 "Off" ;
VAL_ 563 OfbChrgSetSync_D_Rq 3 "Fail" 2 "Success" 1 "InProgress" 0 "NoSyncInProgress" ;
VAL_ 563 KeyOffPwMde_D_Stat 7 "NotUsed_6" 6 "NotUsed_5" 5 "NotUsed_4" 4 "NotUsed_3" 0 "Inactive" 1 "On" 2 "NotUsed_1" 3 "NotUsed_2" ;
VAL_ 563 ModemReset_D_Stat 15 "NotUsed_10" 14 "NotUsed_9" 13 "NotUsed_8" 12 "NotUsed_7" 11 "NotUsed_6" 10 "NotUsed_5" 9 "NotUsed_4" 8 "NotUsed_3" 7 "NotUsed_2" 6 "NotUsed_1" 5 "WifiHotSpotResetComplete" 4 "CcsResetComplete" 3 "OnlineTrafficResetComplete" 2 "PaakResetComplete" 1 "ResetNotComplete" 0 "Null" ;
VAL_ 563 FactoryReset_St 3 "NotUsed_2" 2 "NotUsed_1" 1 "FactoryDefaultsRestored" 0 "Null" ;
VAL_ 794 DcacFaltMsgTxt_D2_Rq_UB 1 "Fresh_data" 0 "Unchanged_data" ;
VAL_ 794 DcacFaltMsgTxt_D2_Rq 63 "NotUsed_47" 17 "NotUsed_1" 16 "HevDerate" 15 "HvacOn" 14 "OvercurrentLP" 13 "EngineRun" 12 "Service" 11 "NotAvailable" 10 "PlugWarn" 9 "PlugWarnDrive" 8 "BreakerC" 7 "BreakerB" 6 "BreakerA" 5 "FuelLow" 4 "AcOnOutput" 3 "Temperature" 2 "Gfci" 1 "Overcurrent" 0 "Ok" ;
VAL_ 794 HvacBlwrRear_D_Stat_UB 1 "Fresh_data" 0 "Unchanged_data" ;
VAL_ 794 HvacBlwrFront_D_Stat_UB 1 "Fresh_data" 0 "Unchanged_data" ;
VAL_ 794 HvacBlwrRear_D_Stat 31 "Not_Used" 20 "Full_On" 19 "95_Percent" 18 "90_Percent" 17 "85_Percent" 16 "80_Percent" 15 "75_Percent" 14 "70_Percent" 13 "65_Percent" 12 "60_Percent" 11 "55_Percent" 10 "50_Percent" 9 "45_Percent" 8 "40_Percent" 7 "35_Percent" 6 "30_Percent" 5 "25_Percent" 4 "20_Percent" 3 "15_Percent" 2 "10_Percent" 1 "5_Percent" 0 "Off" ;
VAL_ 794 HvacBlwrFront_D_Stat 31 "Not_Used" 20 "Full_On" 19 "95_Percent" 18 "90_Percent" 17 "85_Percent" 16 "80_Percent" 15 "75_Percent" 14 "70_Percent" 13 "65_Percent" 12 "60_Percent" 11 "55_Percent" 10 "50_Percent" 9 "45_Percent" 8 "40_Percent" 7 "35_Percent" 6 "30_Percent" 5 "25_Percent" 4 "20_Percent" 3 "15_Percent" 2 "10_Percent" 1 "5_Percent" 0 "Off" ;
VAL_ 794 SpotLghtLeft_D_Stat_UB 1 "Fresh_data" 0 "Unchanged_data" ;
VAL_ 794 SpotLghtRight_D_Stat_UB 1 "Fresh_data" 0 "Unchanged_data" ;
VAL_ 794 SpotLghtRight_D_Stat 1 "On" 0 "Off" ;
VAL_ 794 SpotLghtLeft_D_Stat 1 "On" 0 "Off" ;
